VERSION "created by canmatrix"

NS_ :

BS_:

BU_: MD1_ECM ETC NODE_5 BSM_EBS RM_IRCS IC_Multic SGW BCM_NBM VCM NODE_31 ETS NODE_45 FCCU DICO NODE_72 FMReceiver SGW2 VCU ADCU MRGEN DTCO MBMS TPMS AI_CAID ELC ELC_R NODE_F7 BMS3 TUROLLA PCM SRR_Front_Left SRR_Rear_Right SRR_Front_Right SRR_Front SRR_Rear_Left ELFA3_S THERMOKING_M TMU_HP_Rr NODE_B1 NODE_B2 NODE_B3 NODE_B4 NODE_B5 NODE_B6 NODE_B7 NODE_B8 BMS2 NODE_B9 NODE_BA NODE_FC NODE_BB NODE_BC NODE_BE NODE_BD NODE_BF ACU NODE_C0 BMS1 NODE_C1 FCU NODE_C3 NODE_C4 NODE_EC NODE_C5 NODE_C6 NODE_C7 NODE_C8 VCU2 NODE_CA NODE_CB NODE_CD NODE_CE NODE_CF NODE_ED ST_ScanTool MASTER68_STD1 NODE_D1 NODE_F2 NODE_FD NODE_D2 MCSL NODE_EB NODE_D3 NODE_D4 NODE_D5 NODE_D6 VCCU NODE_D8 NODE_D9 NODE_F9 DiagTool NODE_DA NODE_DB NODE_DC NODE_DD NODE_DE NODE_DF NODE_E0 NODE_E1 NODE_E2 NODE_E9 NODE_E3 SAS NODE_FB NODE_F8 NODE_E6 ELFA3 NODE_F THERMOKING_D FMS MULTIC_S MULTIC_2 BMS4 BMS5 BMS6 BMS7 BMS8 BMS9 BMS10 BMS11 NODE_71

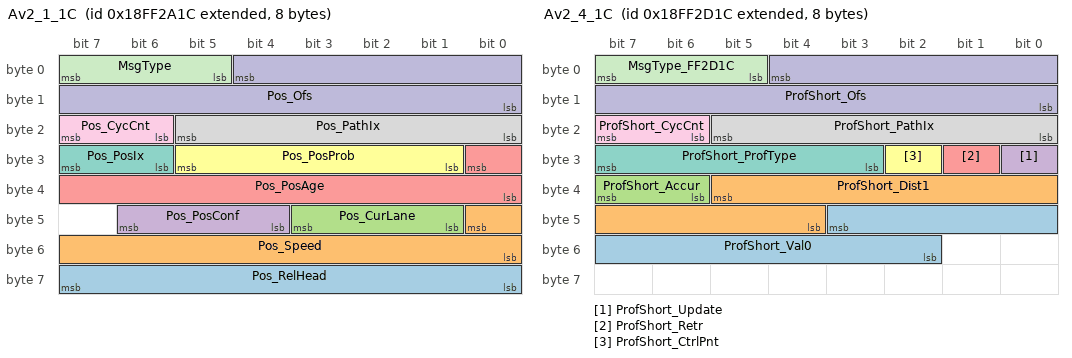
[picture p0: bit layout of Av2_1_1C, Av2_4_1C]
BO_ 2566859292 Av2_1_1C: 8 PCM
 SG_ Pos_RelHead : 63|8@0+ (1.41732283464567,0) [0|358.583] "deg" Vector__XXX
 SG_ Pos_Speed : 40|9@0+ (0.2,-12.8) [-12.8|89.4] "m/s" Vector__XXX
 SG_ Pos_CurLane : 43|3@0+ (1,0) [0|7] "" Vector__XXX
 SG_ Pos_PosConf : 46|3@0+ (1,0) [0|7] "" Vector__XXX
 SG_ Pos_PosAge : 24|9@0+ (5,0) [0|2545] "ms" Vector__XXX
 SG_ Pos_PosProb : 29|5@0+ (3.33333333333333,0) [0|100] "%" Vector__XXX
 SG_ Pos_PosIx : 31|2@0+ (1,0) [0|3] "" Vector__XXX
 SG_ Pos_PathIx : 21|6@0+ (1,0) [8|63] "" Vector__XXX
 SG_ Pos_CycCnt : 23|2@0+ (1,0) [0|3] "" Vector__XXX
 SG_ Pos_Ofs : 4|13@0+ (1,0) [0|8190] "m" Vector__XXX
 SG_ MsgType : 7|3@0+ (1,0) [0|7] "" Vector__XXX

BO_ 2566859548 Av2_2_1C: 8 PCM
 SG_ Seg_NumOfLanesInDrivDir : 58|3@0+ (1,0) [0|7] "" Vector__XXX
 SG_ Seg_NumOfLanesInOppDir : 60|2@0+ (1,0) [0|3] "" Vector__XXX
 SG_ Seg_DividedRoad : 62|2@0+ (1,0) [0|3] "" Vector__XXX
 SG_ Seg_EffSpeedLimType : 50|3@0+ (1,0) [0|7] "" Vector__XXX
 SG_ Seg_EffSpeedLim : 55|5@0+ (1,0) [0|31] "km/h or mph" Vector__XXX
 SG_ Seg_FormOfWay : 43|4@0+ (1,0) [0|14] "" Vector__XXX
 SG_ Seg_ComplexInters : 45|2@0+ (1,0) [0|3] "" Vector__XXX
 SG_ Seg_PartOfCalcRoute : 47|2@0+ (1,0) [0|3] "" Vector__XXX
 SG_ Seg_FunctRoadClass : 34|3@0+ (1,0) [0|6] "" Vector__XXX
 SG_ Seg_RelProb : 39|5@0+ (3.33333333333333,0) [0|100] "%" Vector__XXX
 SG_ Seg_Update : 24|1@0+ (1,0) [0|1] "" Vector__XXX
 SG_ Seg_Retr : 25|1@0+ (1,0) [0|1] "" Vector__XXX
 SG_ Seg_BuiltUpArea : 27|2@0+ (1,0) [0|3] "" Vector__XXX
 SG_ Seg_Bridge : 29|2@0+ (1,0) [0|3] "" Vector__XXX
 SG_ Seg_Tunnel : 31|2@0+ (1,0) [0|3] "" Vector__XXX
 SG_ Seg_PathIx : 21|6@0+ (1,0) [8|63] "" Vector__XXX
 SG_ Seg_CycCnt : 23|2@0+ (1,0) [0|3] "" Vector__XXX
 SG_ Seg_Ofs : 4|13@0+ (1,0) [0|8190] "m" Vector__XXX
 SG_ MsgType_FF2B1C : 7|3@0+ (1,0) [0|7] "" Vector__XXX

BO_ 2566859804 Av2_3_1C: 8 PCM
 SG_ Stub_NumOfLanesInDrivDir : 58|3@0+ (1,0) [0|7] "" Vector__XXX
 SG_ Stub_NumOfLanesInOppDir : 60|2@0+ (1,0) [0|3] "" Vector__XXX
 SG_ Stub_RightOfWay : 62|2@0+ (1,0) [0|3] "" Vector__XXX
 SG_ Stub_LastStubAtOfs : 63|1@0+ (1,0) [0|1] "" Vector__XXX
 SG_ Stub_TurnAngle : 55|8@0+ (1.41732283464567,0) [0|358.583] "deg" Vector__XXX
 SG_ Stub_FormOfWay : 43|4@0+ (1,0) [0|14] "" Vector__XXX
 SG_ Stub_ComplexInters : 45|2@0+ (1,0) [0|3] "" Vector__XXX
 SG_ Stub_PartOfCalcRoute : 47|2@0+ (1,0) [0|3] "" Vector__XXX
 SG_ Stub_FunctRoadClass : 34|3@0+ (1,0) [0|6] "" Vector__XXX
 SG_ Stub_RelProb : 39|5@0+ (3.33333333333333,0) [0|100] "%" Vector__XXX
 SG_ Stub_Update : 24|1@0+ (1,0) [0|1] "" Vector__XXX
 SG_ Stub_Retr : 25|1@0+ (1,0) [0|1] "" Vector__XXX
 SG_ Stub_SubPathIx : 31|6@0+ (1,0) [8|63] "" Vector__XXX
 SG_ Stub_PathIx : 21|6@0+ (1,0) [8|63] "" Vector__XXX
 SG_ Stub_CycCnt : 23|2@0+ (1,0) [0|3] "" Vector__XXX
 SG_ Stub_Ofs : 4|13@0+ (1,0) [0|8190] "m" Vector__XXX
 SG_ MsgType_FF2C1C : 7|3@0+ (1,0) [0|7] "" Vector__XXX

BO_ 2566860060 Av2_4_1C: 8 PCM
 SG_ ProfShort_Val0 : 43|10@0+ (1,0) [0|1023] "" Vector__XXX
 SG_ ProfShort_Dist1 : 37|10@0+ (1,0) [0|1022] "m" Vector__XXX
 SG_ ProfShort_Accur : 39|2@0+ (1,0) [0|3] "" Vector__XXX
 SG_ ProfShort_Update : 24|1@0+ (1,0) [0|1] "" Vector__XXX
 SG_ ProfShort_Retr : 25|1@0+ (1,0) [0|1] "" Vector__XXX
 SG_ ProfShort_CtrlPnt : 26|1@0+ (1,0) [0|1] "" Vector__XXX
 SG_ ProfShort_ProfType M : 31|5@0+ (1,0) [0|31] "" Vector__XXX
 SG_ ProfShort_PathIx : 21|6@0+ (1,0) [8|63] "" Vector__XXX
 SG_ ProfShort_CycCnt : 23|2@0+ (1,0) [0|3] "" Vector__XXX
 SG_ ProfShort_Ofs : 4|13@0+ (1,0) [0|8190] "m" Vector__XXX
 SG_ MsgType_FF2D1C : 7|3@0+ (1,0) [0|7] "" Vector__XXX

BO_ 2566860316 Av2_5_1C: 8 PCM
 SG_ ProfLong_Val31_RsvdForSysSpecTyp m31 : 39|32@0+ (1,1) [1|1] "" Vector__XXX
 SG_ ProfLong_Val30_RsvdForSysSpecTyp m30 : 39|32@0+ (1,1) [1|1] "" Vector__XXX
 SG_ ProfLong_Val29_RsvdForSysSpecTyp m29 : 39|32@0+ (1,1) [1|1] "" Vector__XXX
 SG_ ProfLong_Val28_RsvdForSysSpecTyp m28 : 39|32@0+ (1,1) [1|1] "" Vector__XXX
 SG_ ProfLong_Val27_RsvdForSysSpecTyp m27 : 39|32@0+ (1,1) [1|1] "" Vector__XXX
 SG_ ProfLong_Val26_RsvdForSysSpecTyp m26 : 39|32@0+ (1,1) [1|1] "" Vector__XXX
 SG_ ProfLong_Val25_RsvdForSysSpecTyp m25 : 39|32@0+ (1,1) [1|1] "" Vector__XXX
 SG_ ProfLong_Val24_RsvdForSysSpecTyp m24 : 39|32@0+ (1,1) [1|1] "" Vector__XXX
 SG_ ProfLong_Val23_RsvdForSysSpecTyp m23 : 39|32@0+ (1,1) [1|1] "" Vector__XXX
 SG_ ProfLong_Val22_RsvdForSysSpecTyp m22 : 39|32@0+ (1,1) [1|1] "" Vector__XXX
 SG_ ProfLong_Val21_RsvdForSysSpecTyp m21 : 39|32@0+ (1,1) [1|1] "" Vector__XXX
 SG_ ProfLong_Val20_RsvdForSysSpecTyp m20 : 39|32@0+ (1,1) [1|1] "" Vector__XXX
 SG_ ProfLong_Val19_RsvdForSysSpecTyp m19 : 39|32@0+ (1,1) [1|1] "" Vector__XXX
 SG_ ProfLong_Val18_RsvdForSysSpecTyp m18 : 39|32@0+ (1,1) [1|1] "" Vector__XXX
 SG_ ProfLong_Val17_RsvdForSysSpecTyp m17 : 39|32@0+ (1,1) [1|1] "" Vector__XXX
 SG_ ProfLong_Val16_RsvdForSysSpecTyp m16 : 39|32@0+ (1,1) [1|1] "" Vector__XXX
 SG_ ProfLong_Val15_RsvdForStdTypes m15 : 39|32@0+ (1,1) [1|1] "" Vector__XXX
 SG_ ProfLong_Val14_RsvdForStdTypes m14 : 39|32@0+ (1,1) [1|1] "" Vector__XXX
 SG_ ProfLong_Val13_RsvdForStdTypes m13 : 39|32@0+ (1,1) [1|1] "" Vector__XXX
 SG_ ProfLong_Val12_RsvdForStdTypes m12 : 39|32@0+ (1,1) [1|1] "" Vector__XXX
 SG_ ProfLong_Val11_RsvdForStdTypes m11 : 39|32@0+ (1,1) [1|1] "" Vector__XXX
 SG_ ProfLong_Val10_RsvdForStdTypes m10 : 39|32@0+ (1,1) [1|1] "" Vector__XXX
 SG_ ProfLong_Val9_RsvdForStdTypes m9 : 39|32@0+ (1,1) [1|1] "" Vector__XXX
 SG_ ProfLong_Val8_RsvdForStdTypes m8 : 39|32@0+ (1,1) [1|1] "" Vector__XXX
 SG_ ProfLong_Val7_RsvdForStdTypes m7 : 39|32@0+ (1,1) [1|1] "" Vector__XXX
 SG_ ProfLong_Val6_RsvdForStdTypes m6 : 39|32@0+ (1,1) [1|1] "" Vector__XXX
 SG_ ProfLong_Val5_RsvdForStdTypes m5 : 39|32@0+ (1,1) [1|1] "" Vector__XXX
 SG_ ProfLong_Val4_RsvdForStdTypes m4 : 39|32@0+ (1,1) [1|1] "" Vector__XXX
 SG_ ProfLong_Val3_RsvdForStdTypes m3 : 39|32@0+ (1,1) [1|1] "" Vector__XXX
 SG_ ProfLong_Val2_Lat m2 : 39|32@0+ (1E-007,-90) [-90|331.1081215] "deg" Vector__XXX
 SG_ ProfLong_Val1_Long m1 : 39|32@0+ (1E-007,-180) [-180|241.1081215] "deg" Vector__XXX
 SG_ ProfLong_Update : 24|1@0+ (1,0) [0|1] "" Vector__XXX
 SG_ ProfLong_Retr : 25|1@0+ (1,0) [0|1] "" Vector__XXX
 SG_ ProfLong_CtrlPnt : 26|1@0+ (1,0) [0|1] "" Vector__XXX
 SG_ ProfLong_ProfType M : 31|5@0+ (1,0) [0|31] "" Vector__XXX
 SG_ ProfLong_PathIx : 21|6@0+ (1,0) [8|63] "" Vector__XXX
 SG_ ProfLong_CycCnt : 23|2@0+ (1,0) [0|3] "" Vector__XXX
 SG_ ProfLong_Ofs : 4|13@0+ (1,0) [0|8190] "m" Vector__XXX
 SG_ MsgType_FF2E1C : 7|3@0+ (1,0) [0|7] "" Vector__XXX

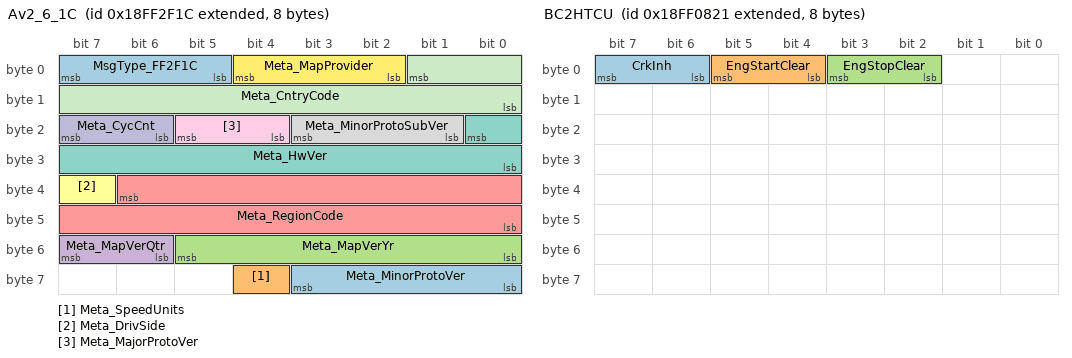
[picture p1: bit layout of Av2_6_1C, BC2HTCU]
BO_ 2566860572 Av2_6_1C: 8 PCM
 SG_ Meta_MinorProtoVer : 59|4@0+ (1,0) [0|15] "" Vector__XXX
 SG_ Meta_SpeedUnits : 60|1@0+ (1,0) [0|1] "" Vector__XXX
 SG_ Meta_MapVerYr : 53|6@0+ (1,2000) [2000|2063] "year" Vector__XXX
 SG_ Meta_MapVerQtr : 55|2@0+ (1,1) [1|4] "Quarter" Vector__XXX
 SG_ Meta_RegionCode : 38|15@0+ (1,0) [0|32767] "" Vector__XXX
 SG_ Meta_DrivSide : 39|1@0+ (1,0) [0|1] "" Vector__XXX
 SG_ Meta_HwVer : 16|9@0+ (1,0) [0|511] "" Vector__XXX
 SG_ Meta_MinorProtoSubVer : 19|3@0+ (1,0) [0|7] "" Vector__XXX
 SG_ Meta_MajorProtoVer : 21|2@0+ (1,0) [0|3] "" Vector__XXX
 SG_ Meta_CycCnt : 23|2@0+ (1,0) [0|3] "" Vector__XXX
 SG_ Meta_CntryCode : 1|10@0+ (1,0) [0|1023] "" Vector__XXX
 SG_ Meta_MapProvider : 4|3@0+ (1,0) [0|7] "" Vector__XXX
 SG_ MsgType_FF2F1C : 7|3@0+ (1,0) [0|7] "" Vector__XXX

BO_ 2565804065 BC_DR: 8 BCM_NBM
 SG_ HandLevPos : 2|6@1+ (1,0) [0|63] ""  PCM,RM_IRCS
 SG_ DisRetFtReq : 0|1@1+ (1,0) [0|1] ""  PCM,RM_IRCS

BO_ 2566850593 BC2HTCU: 8 BCM_NBM
 SG_ CrkInh : 6|2@1+ (1,0) [0|3] ""  PCM
 SG_ EngStartClear : 4|2@1+ (1,0) [0|3] ""  PCM
 SG_ EngStopClear : 2|2@1+ (1,0) [0|3] ""  PCM

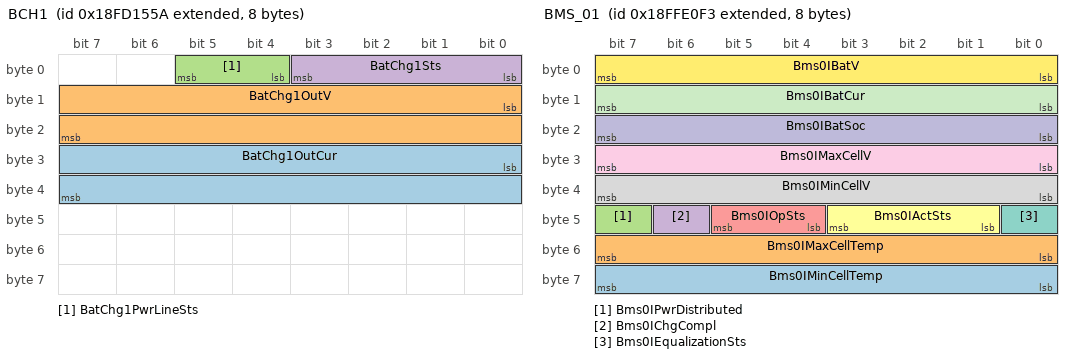
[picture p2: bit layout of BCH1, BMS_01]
BO_ 2566722906 BCH1: 8 DICO
 SG_ BatChg1OutCur : 24|16@1+ (0.05,-1600) [-1600|1612.75] "A"  PCM
 SG_ BatChg1OutV : 8|16@1+ (0.05,0) [0|3212.75] "V"  PCM
 SG_ BatChg1PwrLineSts : 4|2@1+ (1,0) [0|3] ""  PCM
 SG_ BatChg1Sts : 0|4@1+ (1,0) [0|15] ""  PCM

BO_ 2566906099 BMS_01: 8 MBMS
 SG_ Bms0IMinCellTemp : 56|8@1+ (1,-40) [-40|210] "°C"  PCM
 SG_ Bms0IMaxCellTemp : 48|8@1+ (1,-40) [-40|210] "°C"  PCM
 SG_ Bms0IPwrDistributed : 47|1@1+ (1,0) [0|1] ""  PCM
 SG_ Bms0IChgCompl : 46|1@1+ (1,0) [0|1] ""  PCM
 SG_ Bms0IOpSts : 44|2@1+ (1,0) [0|3] ""  PCM
 SG_ Bms0IActSts : 41|3@1+ (1,0) [0|7] ""  PCM
 SG_ Bms0IEqualizationSts : 40|1@1+ (1,0) [0|1] ""  PCM
 SG_ Bms0IMinCellV : 32|8@1+ (20,0) [0|5000] "Mv"  PCM
 SG_ Bms0IMaxCellV : 24|8@1+ (20,0) [0|5000] "Mv"  PCM
 SG_ Bms0IBatSoc : 16|8@1+ (0.4,0) [0|100] "%"  PCM
 SG_ Bms0IBatCur : 8|8@1+ (4,-500) [-500|500] "A"  PCM
 SG_ Bms0IBatV : 0|8@1+ (3.4,0) [0|850] "V"  PCM

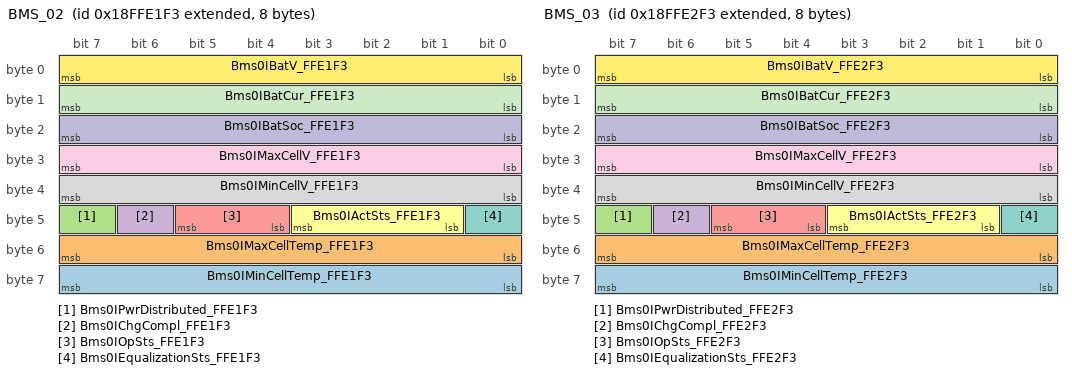
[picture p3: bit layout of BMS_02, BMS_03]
BO_ 2566906355 BMS_02: 8 MBMS
 SG_ Bms0IMinCellTemp_FFE1F3 : 56|8@1+ (1,-40) [-40|210] "°C"  PCM
 SG_ Bms0IMaxCellTemp_FFE1F3 : 48|8@1+ (1,-40) [-40|210] "°C"  PCM
 SG_ Bms0IPwrDistributed_FFE1F3 : 47|1@1+ (1,0) [0|1] ""  PCM
 SG_ Bms0IChgCompl_FFE1F3 : 46|1@1+ (1,0) [0|1] ""  PCM
 SG_ Bms0IOpSts_FFE1F3 : 44|2@1+ (1,0) [0|3] ""  PCM
 SG_ Bms0IActSts_FFE1F3 : 41|3@1+ (1,0) [0|7] ""  PCM
 SG_ Bms0IEqualizationSts_FFE1F3 : 40|1@1+ (1,0) [0|1] ""  PCM
 SG_ Bms0IMinCellV_FFE1F3 : 32|8@1+ (20,0) [0|5000] "Mv"  PCM
 SG_ Bms0IMaxCellV_FFE1F3 : 24|8@1+ (20,0) [0|5000] "Mv"  PCM
 SG_ Bms0IBatSoc_FFE1F3 : 16|8@1+ (0.4,0) [0|100] "%"  PCM
 SG_ Bms0IBatCur_FFE1F3 : 8|8@1+ (4,-500) [-500|500] "A"  PCM
 SG_ Bms0IBatV_FFE1F3 : 0|8@1+ (3.4,0) [0|850] "V"  PCM

BO_ 2566906611 BMS_03: 8 MBMS
 SG_ Bms0IMinCellTemp_FFE2F3 : 56|8@1+ (1,-40) [-40|210] "°C"  PCM
 SG_ Bms0IMaxCellTemp_FFE2F3 : 48|8@1+ (1,-40) [-40|210] "°C"  PCM
 SG_ Bms0IPwrDistributed_FFE2F3 : 47|1@1+ (1,0) [0|1] ""  PCM
 SG_ Bms0IChgCompl_FFE2F3 : 46|1@1+ (1,0) [0|1] ""  PCM
 SG_ Bms0IOpSts_FFE2F3 : 44|2@1+ (1,0) [0|3] ""  PCM
 SG_ Bms0IActSts_FFE2F3 : 41|3@1+ (1,0) [0|7] ""  PCM
 SG_ Bms0IEqualizationSts_FFE2F3 : 40|1@1+ (1,0) [0|1] ""  PCM
 SG_ Bms0IMinCellV_FFE2F3 : 32|8@1+ (20,0) [0|5000] "Mv"  PCM
 SG_ Bms0IMaxCellV_FFE2F3 : 24|8@1+ (20,0) [0|5000] "Mv"  PCM
 SG_ Bms0IBatSoc_FFE2F3 : 16|8@1+ (0.4,0) [0|100] "%"  PCM
 SG_ Bms0IBatCur_FFE2F3 : 8|8@1+ (4,-500) [-500|500] "A"  PCM
 SG_ Bms0IBatV_FFE2F3 : 0|8@1+ (3.4,0) [0|850] "V"  PCM

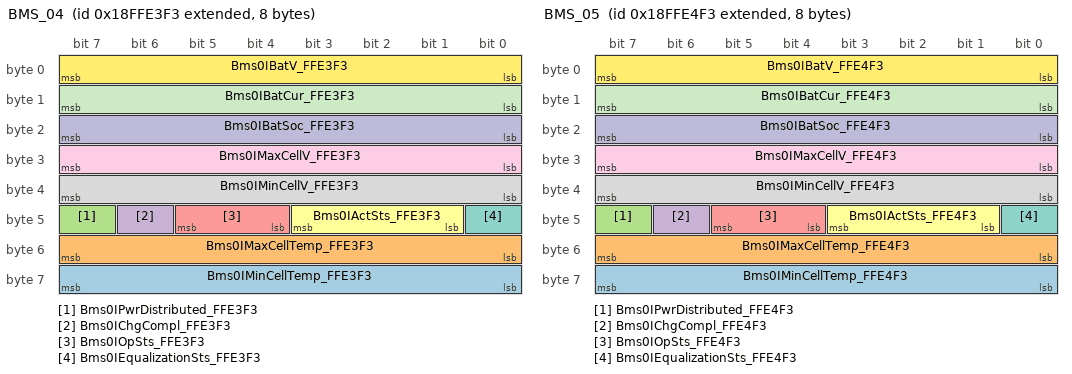
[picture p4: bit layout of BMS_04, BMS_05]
BO_ 2566906867 BMS_04: 8 MBMS
 SG_ Bms0IMinCellTemp_FFE3F3 : 56|8@1+ (1,-40) [-40|210] "°C"  PCM
 SG_ Bms0IMaxCellTemp_FFE3F3 : 48|8@1+ (1,-40) [-40|210] "°C"  PCM
 SG_ Bms0IPwrDistributed_FFE3F3 : 47|1@1+ (1,0) [0|1] ""  PCM
 SG_ Bms0IChgCompl_FFE3F3 : 46|1@1+ (1,0) [0|1] ""  PCM
 SG_ Bms0IOpSts_FFE3F3 : 44|2@1+ (1,0) [0|3] ""  PCM
 SG_ Bms0IActSts_FFE3F3 : 41|3@1+ (1,0) [0|7] ""  PCM
 SG_ Bms0IEqualizationSts_FFE3F3 : 40|1@1+ (1,0) [0|1] ""  PCM
 SG_ Bms0IMinCellV_FFE3F3 : 32|8@1+ (20,0) [0|5000] "Mv"  PCM
 SG_ Bms0IMaxCellV_FFE3F3 : 24|8@1+ (20,0) [0|5000] "Mv"  PCM
 SG_ Bms0IBatSoc_FFE3F3 : 16|8@1+ (0.4,0) [0|100] "%"  PCM
 SG_ Bms0IBatCur_FFE3F3 : 8|8@1+ (4,-500) [-500|500] "A"  PCM
 SG_ Bms0IBatV_FFE3F3 : 0|8@1+ (3.4,0) [0|850] "V"  PCM

BO_ 2566907123 BMS_05: 8 MBMS
 SG_ Bms0IMinCellTemp_FFE4F3 : 56|8@1+ (1,-40) [-40|210] "°C"  PCM
 SG_ Bms0IMaxCellTemp_FFE4F3 : 48|8@1+ (1,-40) [-40|210] "°C"  PCM
 SG_ Bms0IPwrDistributed_FFE4F3 : 47|1@1+ (1,0) [0|1] ""  PCM
 SG_ Bms0IChgCompl_FFE4F3 : 46|1@1+ (1,0) [0|1] ""  PCM
 SG_ Bms0IOpSts_FFE4F3 : 44|2@1+ (1,0) [0|3] ""  PCM
 SG_ Bms0IActSts_FFE4F3 : 41|3@1+ (1,0) [0|7] ""  PCM
 SG_ Bms0IEqualizationSts_FFE4F3 : 40|1@1+ (1,0) [0|1] ""  PCM
 SG_ Bms0IMinCellV_FFE4F3 : 32|8@1+ (20,0) [0|5000] "Mv"  PCM
 SG_ Bms0IMaxCellV_FFE4F3 : 24|8@1+ (20,0) [0|5000] "Mv"  PCM
 SG_ Bms0IBatSoc_FFE4F3 : 16|8@1+ (0.4,0) [0|100] "%"  PCM
 SG_ Bms0IBatCur_FFE4F3 : 8|8@1+ (4,-500) [-500|500] "A"  PCM
 SG_ Bms0IBatV_FFE4F3 : 0|8@1+ (3.4,0) [0|850] "V"  PCM

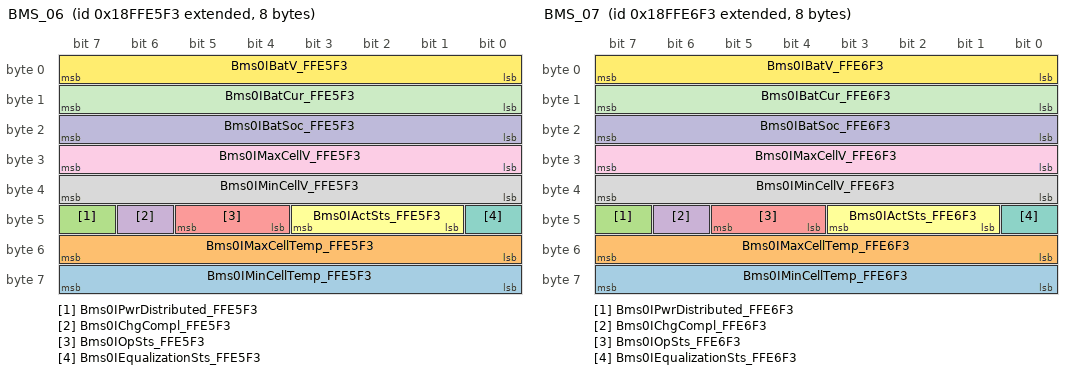
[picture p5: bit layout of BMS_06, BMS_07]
BO_ 2566907379 BMS_06: 8 MBMS
 SG_ Bms0IMinCellTemp_FFE5F3 : 56|8@1+ (1,-40) [-40|210] "°C"  PCM
 SG_ Bms0IMaxCellTemp_FFE5F3 : 48|8@1+ (1,-40) [-40|210] "°C"  PCM
 SG_ Bms0IPwrDistributed_FFE5F3 : 47|1@1+ (1,0) [0|1] ""  PCM
 SG_ Bms0IChgCompl_FFE5F3 : 46|1@1+ (1,0) [0|1] ""  PCM
 SG_ Bms0IOpSts_FFE5F3 : 44|2@1+ (1,0) [0|3] ""  PCM
 SG_ Bms0IActSts_FFE5F3 : 41|3@1+ (1,0) [0|7] ""  PCM
 SG_ Bms0IEqualizationSts_FFE5F3 : 40|1@1+ (1,0) [0|1] ""  PCM
 SG_ Bms0IMinCellV_FFE5F3 : 32|8@1+ (20,0) [0|5000] "Mv"  PCM
 SG_ Bms0IMaxCellV_FFE5F3 : 24|8@1+ (20,0) [0|5000] "Mv"  PCM
 SG_ Bms0IBatSoc_FFE5F3 : 16|8@1+ (0.4,0) [0|100] "%"  PCM
 SG_ Bms0IBatCur_FFE5F3 : 8|8@1+ (4,-500) [-500|500] "A"  PCM
 SG_ Bms0IBatV_FFE5F3 : 0|8@1+ (3.4,0) [0|850] "V"  PCM

BO_ 2566907635 BMS_07: 8 MBMS
 SG_ Bms0IMinCellTemp_FFE6F3 : 56|8@1+ (1,-40) [-40|210] "°C"  PCM
 SG_ Bms0IMaxCellTemp_FFE6F3 : 48|8@1+ (1,-40) [-40|210] "°C"  PCM
 SG_ Bms0IPwrDistributed_FFE6F3 : 47|1@1+ (1,0) [0|1] ""  PCM
 SG_ Bms0IChgCompl_FFE6F3 : 46|1@1+ (1,0) [0|1] ""  PCM
 SG_ Bms0IOpSts_FFE6F3 : 44|2@1+ (1,0) [0|3] ""  PCM
 SG_ Bms0IActSts_FFE6F3 : 41|3@1+ (1,0) [0|7] ""  PCM
 SG_ Bms0IEqualizationSts_FFE6F3 : 40|1@1+ (1,0) [0|1] ""  PCM
 SG_ Bms0IMinCellV_FFE6F3 : 32|8@1+ (20,0) [0|5000] "Mv"  PCM
 SG_ Bms0IMaxCellV_FFE6F3 : 24|8@1+ (20,0) [0|5000] "Mv"  PCM
 SG_ Bms0IBatSoc_FFE6F3 : 16|8@1+ (0.4,0) [0|100] "%"  PCM
 SG_ Bms0IBatCur_FFE6F3 : 8|8@1+ (4,-500) [-500|500] "A"  PCM
 SG_ Bms0IBatV_FFE6F3 : 0|8@1+ (3.4,0) [0|850] "V"  PCM

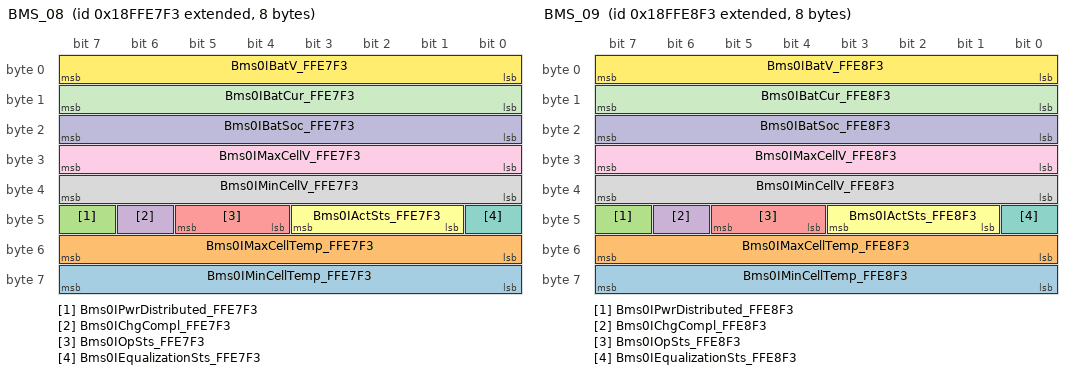
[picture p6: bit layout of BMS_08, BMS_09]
BO_ 2566907891 BMS_08: 8 MBMS
 SG_ Bms0IMinCellTemp_FFE7F3 : 56|8@1+ (1,-40) [-40|210] "°C"  PCM
 SG_ Bms0IMaxCellTemp_FFE7F3 : 48|8@1+ (1,-40) [-40|210] "°C"  PCM
 SG_ Bms0IPwrDistributed_FFE7F3 : 47|1@1+ (1,0) [0|1] ""  PCM
 SG_ Bms0IChgCompl_FFE7F3 : 46|1@1+ (1,0) [0|1] ""  PCM
 SG_ Bms0IOpSts_FFE7F3 : 44|2@1+ (1,0) [0|3] ""  PCM
 SG_ Bms0IActSts_FFE7F3 : 41|3@1+ (1,0) [0|7] ""  PCM
 SG_ Bms0IEqualizationSts_FFE7F3 : 40|1@1+ (1,0) [0|1] ""  PCM
 SG_ Bms0IMinCellV_FFE7F3 : 32|8@1+ (20,0) [0|5000] "Mv"  PCM
 SG_ Bms0IMaxCellV_FFE7F3 : 24|8@1+ (20,0) [0|5000] "Mv"  PCM
 SG_ Bms0IBatSoc_FFE7F3 : 16|8@1+ (0.4,0) [0|100] "%"  PCM
 SG_ Bms0IBatCur_FFE7F3 : 8|8@1+ (4,-500) [-500|500] "A"  PCM
 SG_ Bms0IBatV_FFE7F3 : 0|8@1+ (3.4,0) [0|850] "V"  PCM

BO_ 2566908147 BMS_09: 8 MBMS
 SG_ Bms0IMinCellTemp_FFE8F3 : 56|8@1+ (1,-40) [-40|210] "°C"  PCM
 SG_ Bms0IMaxCellTemp_FFE8F3 : 48|8@1+ (1,-40) [-40|210] "°C"  PCM
 SG_ Bms0IPwrDistributed_FFE8F3 : 47|1@1+ (1,0) [0|1] ""  PCM
 SG_ Bms0IChgCompl_FFE8F3 : 46|1@1+ (1,0) [0|1] ""  PCM
 SG_ Bms0IOpSts_FFE8F3 : 44|2@1+ (1,0) [0|3] ""  PCM
 SG_ Bms0IActSts_FFE8F3 : 41|3@1+ (1,0) [0|7] ""  PCM
 SG_ Bms0IEqualizationSts_FFE8F3 : 40|1@1+ (1,0) [0|1] ""  PCM
 SG_ Bms0IMinCellV_FFE8F3 : 32|8@1+ (20,0) [0|5000] "Mv"  PCM
 SG_ Bms0IMaxCellV_FFE8F3 : 24|8@1+ (20,0) [0|5000] "Mv"  PCM
 SG_ Bms0IBatSoc_FFE8F3 : 16|8@1+ (0.4,0) [0|100] "%"  PCM
 SG_ Bms0IBatCur_FFE8F3 : 8|8@1+ (4,-500) [-500|500] "A"  PCM
 SG_ Bms0IBatV_FFE8F3 : 0|8@1+ (3.4,0) [0|850] "V"  PCM

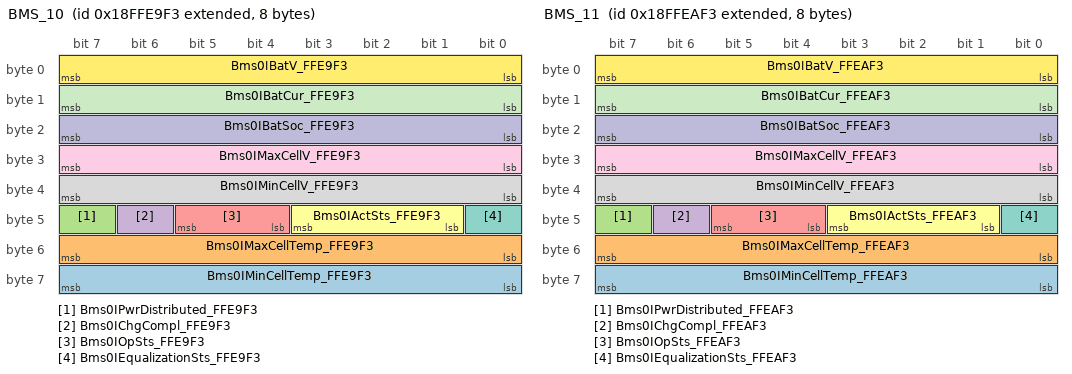
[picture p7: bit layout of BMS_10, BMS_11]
BO_ 2566908403 BMS_10: 8 MBMS
 SG_ Bms0IMinCellTemp_FFE9F3 : 56|8@1+ (1,-40) [-40|210] "°C"  PCM
 SG_ Bms0IMaxCellTemp_FFE9F3 : 48|8@1+ (1,-40) [-40|210] "°C"  PCM
 SG_ Bms0IPwrDistributed_FFE9F3 : 47|1@1+ (1,0) [0|1] ""  PCM
 SG_ Bms0IChgCompl_FFE9F3 : 46|1@1+ (1,0) [0|1] ""  PCM
 SG_ Bms0IOpSts_FFE9F3 : 44|2@1+ (1,0) [0|3] ""  PCM
 SG_ Bms0IActSts_FFE9F3 : 41|3@1+ (1,0) [0|7] ""  PCM
 SG_ Bms0IEqualizationSts_FFE9F3 : 40|1@1+ (1,0) [0|1] ""  PCM
 SG_ Bms0IMinCellV_FFE9F3 : 32|8@1+ (20,0) [0|5000] "Mv"  PCM
 SG_ Bms0IMaxCellV_FFE9F3 : 24|8@1+ (20,0) [0|5000] "Mv"  PCM
 SG_ Bms0IBatSoc_FFE9F3 : 16|8@1+ (0.4,0) [0|100] "%"  PCM
 SG_ Bms0IBatCur_FFE9F3 : 8|8@1+ (4,-500) [-500|500] "A"  PCM
 SG_ Bms0IBatV_FFE9F3 : 0|8@1+ (3.4,0) [0|850] "V"  PCM

BO_ 2566908659 BMS_11: 8 MBMS
 SG_ Bms0IMinCellTemp_FFEAF3 : 56|8@1+ (1,-40) [-40|210] "°C"  PCM
 SG_ Bms0IMaxCellTemp_FFEAF3 : 48|8@1+ (1,-40) [-40|210] "°C"  PCM
 SG_ Bms0IPwrDistributed_FFEAF3 : 47|1@1+ (1,0) [0|1] ""  PCM
 SG_ Bms0IChgCompl_FFEAF3 : 46|1@1+ (1,0) [0|1] ""  PCM
 SG_ Bms0IOpSts_FFEAF3 : 44|2@1+ (1,0) [0|3] ""  PCM
 SG_ Bms0IActSts_FFEAF3 : 41|3@1+ (1,0) [0|7] ""  PCM
 SG_ Bms0IEqualizationSts_FFEAF3 : 40|1@1+ (1,0) [0|1] ""  PCM
 SG_ Bms0IMinCellV_FFEAF3 : 32|8@1+ (20,0) [0|5000] "Mv"  PCM
 SG_ Bms0IMaxCellV_FFEAF3 : 24|8@1+ (20,0) [0|5000] "Mv"  PCM
 SG_ Bms0IBatSoc_FFEAF3 : 16|8@1+ (0.4,0) [0|100] "%"  PCM
 SG_ Bms0IBatCur_FFEAF3 : 8|8@1+ (4,-500) [-500|500] "A"  PCM
 SG_ Bms0IBatV_FFEAF3 : 0|8@1+ (3.4,0) [0|850] "V"  PCM

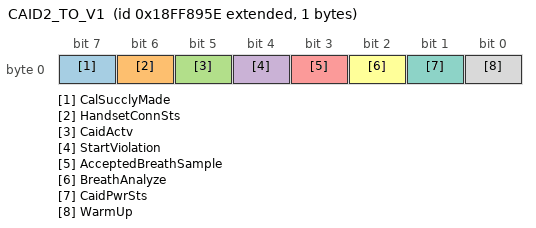
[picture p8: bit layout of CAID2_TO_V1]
BO_ 2566883678 CAID2_TO_V1: 1 AI_CAID
 SG_ CalSucclyMade : 7|1@1+ (1,0) [0|1] ""  PCM
 SG_ HandsetConnSts : 6|1@1+ (1,0) [0|1] ""  PCM
 SG_ CaidActv : 5|1@1+ (1,0) [0|1] ""  PCM
 SG_ StartViolation : 4|1@1+ (1,0) [0|1] ""  PCM
 SG_ AcceptedBreathSample : 3|1@1+ (1,0) [0|1] ""  PCM
 SG_ BreathAnalyze : 2|1@1+ (1,0) [0|1] ""  PCM
 SG_ CaidPwrSts : 1|1@1+ (1,0) [0|1] ""  PCM
 SG_ WarmUp : 0|1@1+ (1,0) [0|1] ""  PCM

BO_ 2566884190 CAID2_TO_V3: 8 AI_CAID
 SG_ DeferredData : 48|8@1+ (1,0) [0|250] ""  PCM

BO_ 2566843648 CCSS_00: 8 MD1_ECM
 SG_ DcdcCurSetPnt24VSide : 56|8@1+ (1,0) [0|250] "A"  PCM
 SG_ MaxVsl : 0|8@1+ (1,0) [0|250] "km/h"  PCM

BO_ 2566843676 CCSS_1C: 8 PCM
 SG_ MaxVsl_FEED1C : 0|8@1+ (1,0) [0|250] "km/h" Vector__XXX

CM_ BO_ 2566859292 "- 30.03.2023: Predisposition PCM3 Protocole ADASIS non J1939
-  TBC if 1 single multiplexed message  or 6-non multiplexed will be used";
CM_ SG_ 2566859292 Pos_PosAge "- Always 0 in Iveco application";
CM_ SG_ 2566859292 Pos_PathIx "- Values 1, 2, 6, 8-63 supported";
CM_ SG_ 2566859292 MsgType "- Always 1";
CM_ BO_ 2566859548 "- 30.03.2023: Predisposition PCM3 Protocole ADASIS non J1939";
CM_ SG_ 2566859548 MsgType_FF2B1C "- Always 2";
CM_ BO_ 2566859804 "- 30.03.2023: Predisposition PCM3 Protocole ADASIS non J1939";
CM_ SG_ 2566859804 MsgType_FF2C1C "- Always 3";
CM_ BO_ 2566860060 "- 30.03.2023: Predisposition PCM3 Protocole ADASIS non J1939";
CM_ SG_ 2566860060 MsgType_FF2D1C "- Always 4";
CM_ BO_ 2566860316 "- 30.03.2023: Predisposition PCM3 Protocole ADASIS non J1939";
CM_ SG_ 2566860316 MsgType_FF2E1C "- Always 5";
CM_ BO_ 2566860572 "- s.Ib..24.work.TELEM: 'AsNeeded'' reuqested for Telem (PCM3)";
CM_ SG_ 2566860572 Meta_RegionCode "- Not used in Iveco application";
CM_ SG_ 2566860572 MsgType_FF2F1C "- Always 6";
CM_ BO_ 2565804065 "- Exception - Should be J1939 p2p. Related to Voith Mild Hybrid project
-  OLD Acronym: PA_BC_DR - Body Computer to Intarder EST42";
CM_ BO_ 2566850593 "- ETC1.Vo.ETC.DiwaNXT..MH.VDB: Msg Predisposal. Only for Mild Hybrid case with AGB Diwa NextGen.
- ETC1.Vo.ETC.DiwaNXT..MH.VDB: The cranking of the engine will be inhibited  by BC till the Mild Hybrid Systems closes properly its start-up sequence. This information is available on message HTCU2BC.CRU_State == 02 / Ready for start-up";
CM_ BO_ 2566722906 "- Specific to Siemens Full Elec vehicles.";
CM_ BO_ 2566906099 "- Specific to Siemens Full Elec vehicles";
CM_ BO_ 2566906355 "- Specific to Siemens Full Elec vehicles";
CM_ BO_ 2566906611 "- Specific to Siemens Full Elec vehicles";
CM_ BO_ 2566906867 "- Specific to Siemens Full Elec vehicles";
CM_ BO_ 2566907123 "- Specific to Siemens Full Elec vehicles";
CM_ BO_ 2566907379 "- Specific to Siemens Full Elec vehicles";
CM_ BO_ 2566907635 "- Specific to Siemens Full Elec vehicles";
CM_ BO_ 2566907891 "- Specific to Siemens Full Elec vehicles";
CM_ BO_ 2566908147 "- Specific to Siemens Full Elec vehicles";
CM_ BO_ 2566908403 "- Specific to Siemens Full Elec vehicles, Forsee only.";
CM_ BO_ 2566908659 "- Specific to Siemens Full Elec vehicles, Forsee only.";
CM_ BO_ 2566843648 "- Not sent by MD1 for CNG";
CM_ SG_ 2566843648 DcdcCurSetPnt24VSide "- Used for Mild Hybrid function";
CM_ SG_ 2566843648 MaxVsl "- 20 km/h in case of Creep Mode active, otherwise FFh";
CM_ SG_ 2566843676 MaxVsl_FEED1C "- Road Speed Limit from GPS maps
-  Type of included limits shall be defined";
BA_DEF_ BO_  "CI_MsgDefinition" STRING ;
BA_DEF_ BO_  "CI_MsgId" INT 0 2147483647;
BA_DEF_ BO_  "CI_MsgName" STRING ;
BA_DEF_ BO_  "GenMsgCycleTime" INT 0 3600000;
BA_DEF_ BO_  "GenMsgCycleTimeFast" INT 0 3600000;
BA_DEF_ BO_  "GenMsgDelayTime" INT 0 3600000;
BA_DEF_ BO_  "GenMsgILSupport" ENUM  "No","Yes";
BA_DEF_ BO_  "GenMsgNrOfRepetition" INT 0 1000000;
BA_DEF_ BO_  "GenMsgRequestable" INT 0 1;
BA_DEF_ BO_  "GenMsgSendType" ENUM  "cyclic","NotUsed","NotUsed","NotUsed","NotUsed","NotUsed","NotUsed","IfActive","noMsgSendType";
BA_DEF_ BO_  "GenMsgStartDelayTime" INT 0 100000;
BA_DEF_ BO_  "TpJ1939VarDlc" ENUM  "No","Yes";
BA_DEF_ BO_  "VFrameFormat" ENUM  "StandardCAN","ExtendedCAN","reserved","J1939PG";
BA_DEF_ SG_  "CI_ParId" STRING ;
BA_DEF_ SG_  "CI_SigId" INT 0 2147483647;
BA_DEF_ SG_  "CI_SigName" STRING ;
BA_DEF_ SG_  "GenSigEVName" STRING ;
BA_DEF_ SG_  "GenSigILSupport" ENUM  "No","Yes";
BA_DEF_ SG_  "GenSigInactiveValue" INT 0 2147483647;
BA_DEF_ SG_  "GenSigSendType" ENUM  "Cyclic","OnWrite","OnWriteWithRepetition","OnChange","OnChangeWithRepetition","IfActive","IfActiveWithRepetition","NoSigSendType";
BA_DEF_ SG_  "GenSigStartValue" INT 0 2147483647;
BA_DEF_ SG_  "GenSigTimeoutTime_ACM_CANAIR" INT 0 3600000;
BA_DEF_ SG_  "GenSigTimeoutTime_ACU" INT 0 3600000;
BA_DEF_ SG_  "GenSigTimeoutTime_ADCU" INT 0 3600000;
BA_DEF_ SG_  "GenSigTimeoutTime_AI_CAID" INT 0 3600000;
BA_DEF_ SG_  "GenSigTimeoutTime_ASM_ELC5_Fr" INT 0 3600000;
BA_DEF_ SG_  "GenSigTimeoutTime_AVAS" INT 0 3600000;
BA_DEF_ SG_  "GenSigTimeoutTime_Av2HP" INT 0 3600000;
BA_DEF_ SG_  "GenSigTimeoutTime_BCM_NBM" INT 0 3600000;
BA_DEF_ SG_  "GenSigTimeoutTime_BSM_EBS" INT 0 3600000;
BA_DEF_ SG_  "GenSigTimeoutTime_DICO" INT 0 3600000;
BA_DEF_ SG_  "GenSigTimeoutTime_DMS" INT 0 3600000;
BA_DEF_ SG_  "GenSigTimeoutTime_EBS_EBR" INT 0 3600000;
BA_DEF_ SG_  "GenSigTimeoutTime_ECM_MD1_D" INT 0 3600000;
BA_DEF_ SG_  "GenSigTimeoutTime_ECM_MD1_G" INT 0 3600000;
BA_DEF_ SG_  "GenSigTimeoutTime_ETC_DiwaNXT" INT 0 3600000;
BA_DEF_ SG_  "GenSigTimeoutTime_ETC_DiwaNXT_MH" INT 0 3600000;
BA_DEF_ SG_  "GenSigTimeoutTime_ETC_Ecolife2" INT 0 3600000;
BA_DEF_ SG_  "GenSigTimeoutTime_FCCU" INT 0 3600000;
BA_DEF_ SG_  "GenSigTimeoutTime_FMS_FMS4" INT 0 3600000;
BA_DEF_ SG_  "GenSigTimeoutTime_FMS_FMS5" INT 0 3600000;
BA_DEF_ SG_  "GenSigTimeoutTime_HVPDU_HV_BOX" INT 0 3600000;
BA_DEF_ SG_  "GenSigTimeoutTime_IC_MulticII" INT 0 3600000;
BA_DEF_ SG_  "GenSigTimeoutTime_IC_MulticS" INT 0 3600000;
BA_DEF_ SG_  "GenSigTimeoutTime_INVEM1_ELFA3" INT 0 3600000;
BA_DEF_ SG_  "GenSigTimeoutTime_MBMS" INT 0 3600000;
BA_DEF_ SG_  "GenSigTimeoutTime_MCSL" INT 0 3600000;
BA_DEF_ SG_  "GenSigTimeoutTime_MPPxPTFE2" INT 0 3600000;
BA_DEF_ SG_  "GenSigTimeoutTime_PCM" INT 0 3600000;
BA_DEF_ SG_  "GenSigTimeoutTime_RDAB_SmtRadio" INT 0 3600000;
BA_DEF_ SG_  "GenSigTimeoutTime_RM_INTD" INT 0 3600000;
BA_DEF_ SG_  "GenSigTimeoutTime_RM_IRCS" INT 0 3600000;
BA_DEF_ SG_  "GenSigTimeoutTime_SAS" INT 0 3600000;
BA_DEF_ SG_  "GenSigTimeoutTime_SGW" INT 0 3600000;
BA_DEF_ SG_  "GenSigTimeoutTime_SGW2" INT 0 3600000;
BA_DEF_ SG_  "GenSigTimeoutTime_TASM_ETS" INT 0 3600000;
BA_DEF_ SG_  "GenSigTimeoutTime_TMU_HP_Fr" INT 0 3600000;
BA_DEF_ SG_  "GenSigTimeoutTime_TMU_HP_Rr" INT 0 3600000;
BA_DEF_ SG_  "GenSigTimeoutTime_TPMS" INT 0 3600000;
BA_DEF_ SG_  "GenSigTimeoutTime_Tacho_DTCO" INT 0 3600000;
BA_DEF_ SG_  "GenSigTimeoutTime_Tacho_MTCO" INT 0 3600000;
BA_DEF_ SG_  "GenSigTimeoutTime_Tacho_TSU" INT 0 3600000;
BA_DEF_ SG_  "GenSigTimeoutTime_VCM" INT 0 3600000;
BA_DEF_ SG_  "GenSigTimeoutTime_VCU" INT 0 3600000;
BA_DEF_ SG_  "GenSigTimeoutTime_VMU" INT 0 3600000;
BA_DEF_ SG_  "SPN" INT 0 524287;
BA_DEF_ SG_  "SigType" ENUM  "Default","Range","RangeSigned","ASCII","Discrete","Control","ReferencePGN","DTC","StringDelimiter","StringLength","StringLengthControl";
BA_DEF_DEF_  "CI_MsgDefinition" "";
BA_DEF_DEF_  "CI_MsgId" 0;
BA_DEF_DEF_  "CI_MsgName" "";
BA_DEF_DEF_  "GenMsgCycleTime" 0;
BA_DEF_DEF_  "GenMsgCycleTimeFast" 0;
BA_DEF_DEF_  "GenMsgDelayTime" 1;
BA_DEF_DEF_  "GenMsgILSupport" "Yes";
BA_DEF_DEF_  "GenMsgNrOfRepetition" 0;
BA_DEF_DEF_  "GenMsgRequestable" 0;
BA_DEF_DEF_  "GenMsgSendType" "noMsgSendType";
BA_DEF_DEF_  "GenMsgStartDelayTime" 0;
BA_DEF_DEF_  "TpJ1939VarDlc" "No";
BA_DEF_DEF_  "VFrameFormat" "J1939PG";
BA_DEF_DEF_  "CI_ParId" "";
BA_DEF_DEF_  "CI_SigId" 0;
BA_DEF_DEF_  "CI_SigName" "";
BA_DEF_DEF_  "GenSigEVName" "Env@Nodename_@Signame";
BA_DEF_DEF_  "GenSigILSupport" "Yes";
BA_DEF_DEF_  "GenSigInactiveValue" 0;
BA_DEF_DEF_  "GenSigSendType" "NoSigSendType";
BA_DEF_DEF_  "GenSigStartValue" 0;
BA_DEF_DEF_  "GenSigTimeoutTime_ACM_CANAIR" 0;
BA_DEF_DEF_  "GenSigTimeoutTime_ACU" 0;
BA_DEF_DEF_  "GenSigTimeoutTime_ADCU" 0;
BA_DEF_DEF_  "GenSigTimeoutTime_AI_CAID" 0;
BA_DEF_DEF_  "GenSigTimeoutTime_ASM_ELC5_Fr" 0;
BA_DEF_DEF_  "GenSigTimeoutTime_AVAS" 0;
BA_DEF_DEF_  "GenSigTimeoutTime_Av2HP" 0;
BA_DEF_DEF_  "GenSigTimeoutTime_BCM_NBM" 0;
BA_DEF_DEF_  "GenSigTimeoutTime_BSM_EBS" 0;
BA_DEF_DEF_  "GenSigTimeoutTime_DICO" 0;
BA_DEF_DEF_  "GenSigTimeoutTime_DMS" 0;
BA_DEF_DEF_  "GenSigTimeoutTime_EBS_EBR" 0;
BA_DEF_DEF_  "GenSigTimeoutTime_ECM_MD1_D" 0;
BA_DEF_DEF_  "GenSigTimeoutTime_ECM_MD1_G" 0;
BA_DEF_DEF_  "GenSigTimeoutTime_ETC_DiwaNXT" 0;
BA_DEF_DEF_  "GenSigTimeoutTime_ETC_DiwaNXT_MH" 0;
BA_DEF_DEF_  "GenSigTimeoutTime_ETC_Ecolife2" 0;
BA_DEF_DEF_  "GenSigTimeoutTime_FCCU" 0;
BA_DEF_DEF_  "GenSigTimeoutTime_FMS_FMS4" 0;
BA_DEF_DEF_  "GenSigTimeoutTime_FMS_FMS5" 0;
BA_DEF_DEF_  "GenSigTimeoutTime_HVPDU_HV_BOX" 0;
BA_DEF_DEF_  "GenSigTimeoutTime_IC_MulticII" 0;
BA_DEF_DEF_  "GenSigTimeoutTime_IC_MulticS" 0;
BA_DEF_DEF_  "GenSigTimeoutTime_INVEM1_ELFA3" 0;
BA_DEF_DEF_  "GenSigTimeoutTime_MBMS" 0;
BA_DEF_DEF_  "GenSigTimeoutTime_MCSL" 0;
BA_DEF_DEF_  "GenSigTimeoutTime_MPPxPTFE2" 0;
BA_DEF_DEF_  "GenSigTimeoutTime_PCM" 0;
BA_DEF_DEF_  "GenSigTimeoutTime_RDAB_SmtRadio" 0;
BA_DEF_DEF_  "GenSigTimeoutTime_RM_INTD" 0;
BA_DEF_DEF_  "GenSigTimeoutTime_RM_IRCS" 0;
BA_DEF_DEF_  "GenSigTimeoutTime_SAS" 0;
BA_DEF_DEF_  "GenSigTimeoutTime_SGW" 0;
BA_DEF_DEF_  "GenSigTimeoutTime_SGW2" 0;
BA_DEF_DEF_  "GenSigTimeoutTime_TASM_ETS" 0;
BA_DEF_DEF_  "GenSigTimeoutTime_TMU_HP_Fr" 0;
BA_DEF_DEF_  "GenSigTimeoutTime_TMU_HP_Rr" 0;
BA_DEF_DEF_  "GenSigTimeoutTime_TPMS" 0;
BA_DEF_DEF_  "GenSigTimeoutTime_Tacho_DTCO" 0;
BA_DEF_DEF_  "GenSigTimeoutTime_Tacho_MTCO" 0;
BA_DEF_DEF_  "GenSigTimeoutTime_Tacho_TSU" 0;
BA_DEF_DEF_  "GenSigTimeoutTime_VCM" 0;
BA_DEF_DEF_  "GenSigTimeoutTime_VCU" 0;
BA_DEF_DEF_  "GenSigTimeoutTime_VMU" 0;
BA_DEF_DEF_  "SPN" 0;
BA_DEF_DEF_  "SigType" "Default";
BA_ "GenMsgStartDelayTime" BO_ 2566859292 160;
BA_ "GenMsgDelayTime" BO_ 2566859292 500;
BA_ "CI_MsgName" BO_ 2566859292 "Av2_1_1C - ADASIS v2 (non-multiplexed) - POSITION Type ";
BA_ "CI_MsgId" BO_ 2566859292 3594;
BA_ "CI_MsgDefinition" BO_ 2566859292 "Iveco Proprietary";
BA_ "GenMsgDelayTime" BO_ 2566859548 100;
BA_ "CI_MsgName" BO_ 2566859548 "Av2_2_1C - ADASIS v2 (non-multiplexed) - SEGMENT Type ";
BA_ "CI_MsgId" BO_ 2566859548 3606;
BA_ "CI_MsgDefinition" BO_ 2566859548 "Iveco Proprietary";
BA_ "GenMsgDelayTime" BO_ 2566859804 100;
BA_ "CI_MsgName" BO_ 2566859804 "Av2_3_1C - ADASIS v2 (non-multiplexed) - STUB Type ";
BA_ "CI_MsgId" BO_ 2566859804 3626;
BA_ "CI_MsgDefinition" BO_ 2566859804 "Iveco Proprietary";
BA_ "GenMsgDelayTime" BO_ 2566860060 100;
BA_ "CI_MsgName" BO_ 2566860060 "Av2_4_1C - ADASIS v2 (non-multiplexed) - PROFILE SHORT Type ";
BA_ "CI_MsgId" BO_ 2566860060 3644;
BA_ "CI_MsgDefinition" BO_ 2566860060 "Iveco Proprietary";
BA_ "GenMsgDelayTime" BO_ 2566860316 100;
BA_ "CI_MsgName" BO_ 2566860316 "Av2_5_1C - ADASIS v2 (non-multiplexed) - PROFILE LONG Type ";
BA_ "CI_MsgId" BO_ 2566860316 3677;
BA_ "CI_MsgDefinition" BO_ 2566860316 "Iveco Proprietary";
BA_ "CI_MsgName" BO_ 2566860572 "Av2_6_1C - ADASIS v2 (non-multiplexed) - META-DATA Type ";
BA_ "CI_MsgId" BO_ 2566860572 21254;
BA_ "CI_MsgDefinition" BO_ 2566860572 "Iveco Proprietary";
BA_ "GenMsgStartDelayTime" BO_ 2565804065 46;
BA_ "GenMsgSendType" BO_ 2565804065 0;
BA_ "GenMsgDelayTime" BO_ 2565804065 50;
BA_ "GenMsgCycleTimeFast" BO_ 2565804065 100;
BA_ "GenMsgCycleTime" BO_ 2565804065 100;
BA_ "CI_MsgName" BO_ 2565804065 "BC_DR - Body Computer to Drivelie retarder";
BA_ "CI_MsgId" BO_ 2565804065 2932;
BA_ "CI_MsgDefinition" BO_ 2565804065 "Iveco SPR2 Proprietary";
BA_ "GenMsgStartDelayTime" BO_ 2566850593 75;
BA_ "GenMsgSendType" BO_ 2566850593 0;
BA_ "GenMsgDelayTime" BO_ 2566850593 50;
BA_ "GenMsgCycleTimeFast" BO_ 2566850593 100;
BA_ "GenMsgCycleTime" BO_ 2566850593 100;
BA_ "CI_MsgName" BO_ 2566850593 "BC2HTCU - BC to HTCU (Mild Hybrid)";
BA_ "CI_MsgId" BO_ 2566850593 4375;
BA_ "CI_MsgDefinition" BO_ 2566850593 "Bosch Proprietary";
BA_ "GenMsgStartDelayTime" BO_ 2566722906 9;
BA_ "GenMsgSendType" BO_ 2566722906 0;
BA_ "GenMsgDelayTime" BO_ 2566722906 50;
BA_ "GenMsgCycleTimeFast" BO_ 2566722906 100;
BA_ "GenMsgCycleTime" BO_ 2566722906 100;
BA_ "CI_MsgName" BO_ 2566722906 "BCH1 - Battery Charger 1";
BA_ "CI_MsgId" BO_ 2566722906 323;
BA_ "CI_MsgDefinition" BO_ 2566722906 "J1939DA";
BA_ "GenMsgStartDelayTime" BO_ 2566906099 56;
BA_ "GenMsgSendType" BO_ 2566906099 0;
BA_ "GenMsgDelayTime" BO_ 2566906099 2500;
BA_ "GenMsgCycleTimeFast" BO_ 2566906099 5000;
BA_ "GenMsgCycleTime" BO_ 2566906099 5000;
BA_ "CI_MsgName" BO_ 2566906099 "BMS_01 - Proprietary Iveco -  BMS0i Infos Frame";
BA_ "CI_MsgId" BO_ 2566906099 10715;
BA_ "CI_MsgDefinition" BO_ 2566906099 "Iveco Proprietary";
BA_ "GenMsgStartDelayTime" BO_ 2566906355 62;
BA_ "GenMsgSendType" BO_ 2566906355 0;
BA_ "GenMsgDelayTime" BO_ 2566906355 2500;
BA_ "GenMsgCycleTimeFast" BO_ 2566906355 5000;
BA_ "GenMsgCycleTime" BO_ 2566906355 5000;
BA_ "CI_MsgName" BO_ 2566906355 "BMS_02 - Proprietary Iveco -  BMS0i Infos Frame";
BA_ "CI_MsgId" BO_ 2566906355 10728;
BA_ "CI_MsgDefinition" BO_ 2566906355 "Iveco Proprietary";
BA_ "GenMsgStartDelayTime" BO_ 2566906611 68;
BA_ "GenMsgSendType" BO_ 2566906611 0;
BA_ "GenMsgDelayTime" BO_ 2566906611 2500;
BA_ "GenMsgCycleTimeFast" BO_ 2566906611 5000;
BA_ "GenMsgCycleTime" BO_ 2566906611 5000;
BA_ "CI_MsgName" BO_ 2566906611 "BMS_03 - Proprietary Iveco -  BMS0i Infos Frame";
BA_ "CI_MsgId" BO_ 2566906611 10741;
BA_ "CI_MsgDefinition" BO_ 2566906611 "Iveco Proprietary";
BA_ "GenMsgStartDelayTime" BO_ 2566906867 74;
BA_ "GenMsgSendType" BO_ 2566906867 0;
BA_ "GenMsgDelayTime" BO_ 2566906867 2500;
BA_ "GenMsgCycleTimeFast" BO_ 2566906867 5000;
BA_ "GenMsgCycleTime" BO_ 2566906867 5000;
BA_ "CI_MsgName" BO_ 2566906867 "BMS_04 - Proprietary Iveco -  BMS0i Infos Frame";
BA_ "CI_MsgId" BO_ 2566906867 10754;
BA_ "CI_MsgDefinition" BO_ 2566906867 "Iveco Proprietary";
BA_ "GenMsgStartDelayTime" BO_ 2566907123 80;
BA_ "GenMsgSendType" BO_ 2566907123 0;
BA_ "GenMsgDelayTime" BO_ 2566907123 2500;
BA_ "GenMsgCycleTimeFast" BO_ 2566907123 5000;
BA_ "GenMsgCycleTime" BO_ 2566907123 5000;
BA_ "CI_MsgName" BO_ 2566907123 "BMS_05 - Proprietary Iveco -  BMS0i Infos Frame";
BA_ "CI_MsgId" BO_ 2566907123 10767;
BA_ "CI_MsgDefinition" BO_ 2566907123 "Iveco Proprietary";
BA_ "GenMsgStartDelayTime" BO_ 2566907379 86;
BA_ "GenMsgSendType" BO_ 2566907379 0;
BA_ "GenMsgDelayTime" BO_ 2566907379 2500;
BA_ "GenMsgCycleTimeFast" BO_ 2566907379 5000;
BA_ "GenMsgCycleTime" BO_ 2566907379 5000;
BA_ "CI_MsgName" BO_ 2566907379 "BMS_06 - Proprietary Iveco -  BMS0i Infos Frame";
BA_ "CI_MsgId" BO_ 2566907379 10780;
BA_ "CI_MsgDefinition" BO_ 2566907379 "Iveco Proprietary";
BA_ "GenMsgStartDelayTime" BO_ 2566907635 92;
BA_ "GenMsgSendType" BO_ 2566907635 0;
BA_ "GenMsgDelayTime" BO_ 2566907635 2500;
BA_ "GenMsgCycleTimeFast" BO_ 2566907635 5000;
BA_ "GenMsgCycleTime" BO_ 2566907635 5000;
BA_ "CI_MsgName" BO_ 2566907635 "BMS_07 - Proprietary Iveco -  BMS0i Infos Frame";
BA_ "CI_MsgId" BO_ 2566907635 10793;
BA_ "CI_MsgDefinition" BO_ 2566907635 "Iveco Proprietary";
BA_ "GenMsgStartDelayTime" BO_ 2566907891 98;
BA_ "GenMsgSendType" BO_ 2566907891 0;
BA_ "GenMsgDelayTime" BO_ 2566907891 2500;
BA_ "GenMsgCycleTimeFast" BO_ 2566907891 5000;
BA_ "GenMsgCycleTime" BO_ 2566907891 5000;
BA_ "CI_MsgName" BO_ 2566907891 "BMS_08 - Proprietary Iveco -  BMS0i Infos Frame";
BA_ "CI_MsgId" BO_ 2566907891 10806;
BA_ "CI_MsgDefinition" BO_ 2566907891 "Iveco Proprietary";
BA_ "GenMsgStartDelayTime" BO_ 2566908147 104;
BA_ "GenMsgSendType" BO_ 2566908147 0;
BA_ "GenMsgDelayTime" BO_ 2566908147 2500;
BA_ "GenMsgCycleTimeFast" BO_ 2566908147 5000;
BA_ "GenMsgCycleTime" BO_ 2566908147 5000;
BA_ "CI_MsgName" BO_ 2566908147 "BMS_09 - Proprietary Iveco -  BMS0i Infos Frame";
BA_ "CI_MsgId" BO_ 2566908147 10819;
BA_ "CI_MsgDefinition" BO_ 2566908147 "Iveco Proprietary";
BA_ "GenMsgStartDelayTime" BO_ 2566908403 106;
BA_ "GenMsgSendType" BO_ 2566908403 0;
BA_ "GenMsgDelayTime" BO_ 2566908403 2500;
BA_ "GenMsgCycleTimeFast" BO_ 2566908403 5000;
BA_ "GenMsgCycleTime" BO_ 2566908403 5000;
BA_ "CI_MsgName" BO_ 2566908403 "BMS_10 - Proprietary Iveco -  BMS0i Infos Frame";
BA_ "CI_MsgId" BO_ 2566908403 10832;
BA_ "CI_MsgDefinition" BO_ 2566908403 "Iveco Proprietary";
BA_ "GenMsgStartDelayTime" BO_ 2566908659 108;
BA_ "GenMsgSendType" BO_ 2566908659 0;
BA_ "GenMsgDelayTime" BO_ 2566908659 2500;
BA_ "GenMsgCycleTimeFast" BO_ 2566908659 5000;
BA_ "GenMsgCycleTime" BO_ 2566908659 5000;
BA_ "CI_MsgName" BO_ 2566908659 "BMS_11 - Proprietary Iveco -  BMS0i Infos Frame";
BA_ "CI_MsgId" BO_ 2566908659 10845;
BA_ "CI_MsgDefinition" BO_ 2566908659 "Iveco Proprietary";
BA_ "GenMsgStartDelayTime" BO_ 2566883678 2;
BA_ "GenMsgSendType" BO_ 2566883678 0;
BA_ "GenMsgDelayTime" BO_ 2566883678 250;
BA_ "GenMsgCycleTimeFast" BO_ 2566883678 500;
BA_ "GenMsgCycleTime" BO_ 2566883678 500;
BA_ "CI_MsgName" BO_ 2566883678 "CAID2_TO_V1 - Connected Alcohol Interlock Device2 To Vehicle 1";
BA_ "CI_MsgId" BO_ 2566883678 2818;
BA_ "CI_MsgDefinition" BO_ 2566883678 "Iveco Proprietary";
BA_ "GenMsgStartDelayTime" BO_ 2566884190 8;
BA_ "GenMsgSendType" BO_ 2566884190 0;
BA_ "GenMsgDelayTime" BO_ 2566884190 500;
BA_ "GenMsgCycleTimeFast" BO_ 2566884190 1000;
BA_ "GenMsgCycleTime" BO_ 2566884190 1000;
BA_ "CI_MsgName" BO_ 2566884190 "CAID2_TO_V3 - CAID2_TO_V3";
BA_ "CI_MsgId" BO_ 2566884190 2833;
BA_ "CI_MsgDefinition" BO_ 2566884190 "Iveco Proprietary";
BA_ "GenMsgStartDelayTime" BO_ 2566843648 34;
BA_ "GenMsgSendType" BO_ 2566843648 0;
BA_ "GenMsgDelayTime" BO_ 2566843648 125;
BA_ "GenMsgCycleTimeFast" BO_ 2566843648 250;
BA_ "GenMsgCycleTime" BO_ 2566843648 250;
BA_ "CI_MsgName" BO_ 2566843648 "CCSS_00 - Cruise Control/Vehicle Speed Setup";
BA_ "CI_MsgId" BO_ 2566843648 2164;
BA_ "CI_MsgDefinition" BO_ 2566843648 "J1939DA";
BA_ "GenMsgStartDelayTime" BO_ 2566843676 156;
BA_ "GenMsgSendType" BO_ 2566843676 0;
BA_ "GenMsgDelayTime" BO_ 2566843676 100;
BA_ "GenMsgCycleTimeFast" BO_ 2566843676 1000;
BA_ "GenMsgCycleTime" BO_ 2566843676 1000;
BA_ "CI_MsgName" BO_ 2566843676 "CCSS_1C - Cruise Control/Vehicle Speed Setup";
BA_ "CI_MsgId" BO_ 2566843676 2170;
BA_ "CI_MsgDefinition" BO_ 2566843676 "J1939DA";
BA_ "SigType" SG_ 2566859292 Pos_RelHead 1;
BA_ "GenSigTimeoutTime_PCM" SG_ 2566859292 Pos_RelHead 5000;
BA_ "CI_SigName" SG_ 2566859292 Pos_RelHead "Position – Relative Heading";
BA_ "CI_SigId" SG_ 2566859292 Pos_RelHead 3605;
BA_ "CI_ParId" SG_ 2566859292 Pos_RelHead "AS008";
BA_ "GenSigTimeoutTime_PCM" SG_ 2566859292 Pos_Speed 5000;
BA_ "GenSigStartValue" SG_ 2566859292 Pos_Speed 511;
BA_ "CI_SigName" SG_ 2566859292 Pos_Speed "Position – Speed";
BA_ "CI_SigId" SG_ 2566859292 Pos_Speed 3604;
BA_ "CI_ParId" SG_ 2566859292 Pos_Speed "AS007";
BA_ "GenSigTimeoutTime_PCM" SG_ 2566859292 Pos_CurLane 5000;
BA_ "CI_SigName" SG_ 2566859292 Pos_CurLane "Position – Current Lane";
BA_ "CI_SigId" SG_ 2566859292 Pos_CurLane 3602;
BA_ "CI_ParId" SG_ 2566859292 Pos_CurLane "AS011";
BA_ "GenSigTimeoutTime_PCM" SG_ 2566859292 Pos_PosConf 5000;
BA_ "GenSigStartValue" SG_ 2566859292 Pos_PosConf 7;
BA_ "CI_SigName" SG_ 2566859292 Pos_PosConf "Position – Position Confidence";
BA_ "CI_SigId" SG_ 2566859292 Pos_PosConf 3603;
BA_ "CI_ParId" SG_ 2566859292 Pos_PosConf "AS010";
BA_ "GenSigTimeoutTime_PCM" SG_ 2566859292 Pos_PosAge 5000;
BA_ "CI_SigName" SG_ 2566859292 Pos_PosAge "Position – Position Age";
BA_ "CI_SigId" SG_ 2566859292 Pos_PosAge 3601;
BA_ "CI_ParId" SG_ 2566859292 Pos_PosAge "AS006";
BA_ "GenSigTimeoutTime_PCM" SG_ 2566859292 Pos_PosProb 5000;
BA_ "CI_SigName" SG_ 2566859292 Pos_PosProb "Position – Position Probability";
BA_ "CI_SigId" SG_ 2566859292 Pos_PosProb 3599;
BA_ "CI_ParId" SG_ 2566859292 Pos_PosProb "AS009";
BA_ "GenSigTimeoutTime_PCM" SG_ 2566859292 Pos_PosIx 5000;
BA_ "CI_SigName" SG_ 2566859292 Pos_PosIx "Position – Position Index";
BA_ "CI_SigId" SG_ 2566859292 Pos_PosIx 3600;
BA_ "CI_ParId" SG_ 2566859292 Pos_PosIx "AS005";
BA_ "GenSigTimeoutTime_PCM" SG_ 2566859292 Pos_PathIx 5000;
BA_ "GenSigStartValue" SG_ 2566859292 Pos_PathIx 8;
BA_ "CI_SigName" SG_ 2566859292 Pos_PathIx "Position – Path Index";
BA_ "CI_SigId" SG_ 2566859292 Pos_PathIx 3597;
BA_ "CI_ParId" SG_ 2566859292 Pos_PathIx "AS003";
BA_ "GenSigTimeoutTime_PCM" SG_ 2566859292 Pos_CycCnt 5000;
BA_ "CI_SigName" SG_ 2566859292 Pos_CycCnt "Position – Cyclic Counter";
BA_ "CI_SigId" SG_ 2566859292 Pos_CycCnt 3598;
BA_ "CI_ParId" SG_ 2566859292 Pos_CycCnt "AS002";
BA_ "GenSigTimeoutTime_PCM" SG_ 2566859292 Pos_Ofs 5000;
BA_ "CI_SigName" SG_ 2566859292 Pos_Ofs "Position – Offset";
BA_ "CI_SigId" SG_ 2566859292 Pos_Ofs 3596;
BA_ "CI_ParId" SG_ 2566859292 Pos_Ofs "AS004";
BA_ "GenSigTimeoutTime_PCM" SG_ 2566859292 MsgType 5000;
BA_ "GenSigStartValue" SG_ 2566859292 MsgType 6;
BA_ "CI_SigName" SG_ 2566859292 MsgType "Message Type";
BA_ "CI_SigId" SG_ 2566859292 MsgType 3595;
BA_ "CI_ParId" SG_ 2566859292 MsgType "AS001";
BA_ "GenSigStartValue" SG_ 2566859548 Seg_NumOfLanesInDrivDir 7;
BA_ "CI_SigName" SG_ 2566859548 Seg_NumOfLanesInDrivDir "Segment – Number of lanes in driving direction";
BA_ "CI_SigId" SG_ 2566859548 Seg_NumOfLanesInDrivDir 3623;
BA_ "CI_ParId" SG_ 2566859548 Seg_NumOfLanesInDrivDir "AS021";
BA_ "SigType" SG_ 2566859548 Seg_NumOfLanesInOppDir 4;
BA_ "GenSigStartValue" SG_ 2566859548 Seg_NumOfLanesInOppDir 3;
BA_ "CI_SigName" SG_ 2566859548 Seg_NumOfLanesInOppDir "Segment – Number of lanes in opposite direction";
BA_ "CI_SigId" SG_ 2566859548 Seg_NumOfLanesInOppDir 3624;
BA_ "CI_ParId" SG_ 2566859548 Seg_NumOfLanesInOppDir "AS022";
BA_ "SigType" SG_ 2566859548 Seg_DividedRoad 4;
BA_ "GenSigStartValue" SG_ 2566859548 Seg_DividedRoad 3;
BA_ "CI_SigName" SG_ 2566859548 Seg_DividedRoad "Segment – Divided Road";
BA_ "CI_SigId" SG_ 2566859548 Seg_DividedRoad 3625;
BA_ "CI_ParId" SG_ 2566859548 Seg_DividedRoad "AS025";
BA_ "GenSigStartValue" SG_ 2566859548 Seg_EffSpeedLimType 7;
BA_ "CI_SigName" SG_ 2566859548 Seg_EffSpeedLimType "Segment – Effective Speed Limit Type";
BA_ "CI_SigId" SG_ 2566859548 Seg_EffSpeedLimType 3621;
BA_ "CI_ParId" SG_ 2566859548 Seg_EffSpeedLimType "AS020";
BA_ "GenSigStartValue" SG_ 2566859548 Seg_EffSpeedLim 31;
BA_ "CI_SigName" SG_ 2566859548 Seg_EffSpeedLim "Segment – Effective Speed Limit";
BA_ "CI_SigId" SG_ 2566859548 Seg_EffSpeedLim 3622;
BA_ "CI_ParId" SG_ 2566859548 Seg_EffSpeedLim "AS019";
BA_ "GenSigStartValue" SG_ 2566859548 Seg_FormOfWay 3;
BA_ "CI_SigName" SG_ 2566859548 Seg_FormOfWay "Segment – Form of Way";
BA_ "CI_SigId" SG_ 2566859548 Seg_FormOfWay 3618;
BA_ "CI_ParId" SG_ 2566859548 Seg_FormOfWay "AS018";
BA_ "SigType" SG_ 2566859548 Seg_ComplexInters 4;
BA_ "GenSigStartValue" SG_ 2566859548 Seg_ComplexInters 3;
BA_ "CI_SigName" SG_ 2566859548 Seg_ComplexInters "Segment – Complex Intersection";
BA_ "CI_SigId" SG_ 2566859548 Seg_ComplexInters 3619;
BA_ "CI_ParId" SG_ 2566859548 Seg_ComplexInters "AS027";
BA_ "SigType" SG_ 2566859548 Seg_PartOfCalcRoute 4;
BA_ "GenSigStartValue" SG_ 2566859548 Seg_PartOfCalcRoute 3;
BA_ "CI_SigName" SG_ 2566859548 Seg_PartOfCalcRoute "Segment – Part of Calculated Route";
BA_ "CI_SigId" SG_ 2566859548 Seg_PartOfCalcRoute 3620;
BA_ "CI_ParId" SG_ 2566859548 Seg_PartOfCalcRoute "AS029";
BA_ "CI_SigName" SG_ 2566859548 Seg_FunctRoadClass "Segment – Functional Road Class";
BA_ "CI_SigId" SG_ 2566859548 Seg_FunctRoadClass 3616;
BA_ "CI_ParId" SG_ 2566859548 Seg_FunctRoadClass "AS017";
BA_ "CI_SigName" SG_ 2566859548 Seg_RelProb "Segment – Relative Probability";
BA_ "CI_SigId" SG_ 2566859548 Seg_RelProb 3617;
BA_ "CI_ParId" SG_ 2566859548 Seg_RelProb "AS028";
BA_ "CI_SigName" SG_ 2566859548 Seg_Update "Segment – Update";
BA_ "CI_SigId" SG_ 2566859548 Seg_Update 3611;
BA_ "CI_ParId" SG_ 2566859548 Seg_Update "AS016";
BA_ "CI_SigName" SG_ 2566859548 Seg_Retr "Segment – Retransmission";
BA_ "CI_SigId" SG_ 2566859548 Seg_Retr 3612;
BA_ "CI_ParId" SG_ 2566859548 Seg_Retr "AS013";
BA_ "SigType" SG_ 2566859548 Seg_BuiltUpArea 4;
BA_ "GenSigStartValue" SG_ 2566859548 Seg_BuiltUpArea 3;
BA_ "CI_SigName" SG_ 2566859548 Seg_BuiltUpArea "Segment – Built-up Area";
BA_ "CI_SigId" SG_ 2566859548 Seg_BuiltUpArea 3613;
BA_ "CI_ParId" SG_ 2566859548 Seg_BuiltUpArea "AS026";
BA_ "SigType" SG_ 2566859548 Seg_Bridge 4;
BA_ "GenSigStartValue" SG_ 2566859548 Seg_Bridge 3;
BA_ "CI_SigName" SG_ 2566859548 Seg_Bridge "Segment – Bridge";
BA_ "CI_SigId" SG_ 2566859548 Seg_Bridge 3614;
BA_ "CI_ParId" SG_ 2566859548 Seg_Bridge "AS024";
BA_ "SigType" SG_ 2566859548 Seg_Tunnel 4;
BA_ "GenSigStartValue" SG_ 2566859548 Seg_Tunnel 3;
BA_ "CI_SigName" SG_ 2566859548 Seg_Tunnel "Segment – Tunnel";
BA_ "CI_SigId" SG_ 2566859548 Seg_Tunnel 3615;
BA_ "CI_ParId" SG_ 2566859548 Seg_Tunnel "AS023";
BA_ "GenSigStartValue" SG_ 2566859548 Seg_PathIx 8;
BA_ "CI_SigName" SG_ 2566859548 Seg_PathIx "Segment – Path Index";
BA_ "CI_SigId" SG_ 2566859548 Seg_PathIx 3609;
BA_ "CI_ParId" SG_ 2566859548 Seg_PathIx "AS014";
BA_ "CI_SigName" SG_ 2566859548 Seg_CycCnt "Segment – Cyclic Counter";
BA_ "CI_SigId" SG_ 2566859548 Seg_CycCnt 3610;
BA_ "CI_ParId" SG_ 2566859548 Seg_CycCnt "AS012";
BA_ "CI_SigName" SG_ 2566859548 Seg_Ofs "Segment – Offset";
BA_ "CI_SigId" SG_ 2566859548 Seg_Ofs 3608;
BA_ "CI_ParId" SG_ 2566859548 Seg_Ofs "AS015";
BA_ "GenSigStartValue" SG_ 2566859548 MsgType_FF2B1C 6;
BA_ "CI_SigName" SG_ 2566859548 MsgType_FF2B1C "Message Type";
BA_ "CI_SigId" SG_ 2566859548 MsgType_FF2B1C 3607;
BA_ "CI_ParId" SG_ 2566859548 MsgType_FF2B1C "AS001";
BA_ "GenSigStartValue" SG_ 2566859804 Stub_NumOfLanesInDrivDir 7;
BA_ "CI_SigName" SG_ 2566859804 Stub_NumOfLanesInDrivDir "Stub – Number of lanes in driving direction";
BA_ "CI_SigId" SG_ 2566859804 Stub_NumOfLanesInDrivDir 3640;
BA_ "CI_ParId" SG_ 2566859804 Stub_NumOfLanesInDrivDir "AS039";
BA_ "SigType" SG_ 2566859804 Stub_NumOfLanesInOppDir 4;
BA_ "GenSigStartValue" SG_ 2566859804 Stub_NumOfLanesInOppDir 3;
BA_ "CI_SigName" SG_ 2566859804 Stub_NumOfLanesInOppDir "Stub – Number of lanes in opposite direction";
BA_ "CI_SigId" SG_ 2566859804 Stub_NumOfLanesInOppDir 3641;
BA_ "CI_ParId" SG_ 2566859804 Stub_NumOfLanesInOppDir "AS040";
BA_ "SigType" SG_ 2566859804 Stub_RightOfWay 4;
BA_ "GenSigStartValue" SG_ 2566859804 Stub_RightOfWay 3;
BA_ "CI_SigName" SG_ 2566859804 Stub_RightOfWay "Stub – Right of Way";
BA_ "CI_SigId" SG_ 2566859804 Stub_RightOfWay 3642;
BA_ "CI_ParId" SG_ 2566859804 Stub_RightOfWay "AS042";
BA_ "CI_SigName" SG_ 2566859804 Stub_LastStubAtOfs "Stub – Last Stub at Offset";
BA_ "CI_SigId" SG_ 2566859804 Stub_LastStubAtOfs 3643;
BA_ "CI_ParId" SG_ 2566859804 Stub_LastStubAtOfs "AS045";
BA_ "SigType" SG_ 2566859804 Stub_TurnAngle 1;
BA_ "CI_SigName" SG_ 2566859804 Stub_TurnAngle "Stub – Turn Angle";
BA_ "CI_SigId" SG_ 2566859804 Stub_TurnAngle 3639;
BA_ "CI_ParId" SG_ 2566859804 Stub_TurnAngle "AS036";
BA_ "GenSigStartValue" SG_ 2566859804 Stub_FormOfWay 3;
BA_ "CI_SigName" SG_ 2566859804 Stub_FormOfWay "Stub – Form of Way";
BA_ "CI_SigId" SG_ 2566859804 Stub_FormOfWay 3636;
BA_ "CI_ParId" SG_ 2566859804 Stub_FormOfWay "AS038";
BA_ "SigType" SG_ 2566859804 Stub_ComplexInters 4;
BA_ "GenSigStartValue" SG_ 2566859804 Stub_ComplexInters 3;
BA_ "CI_SigName" SG_ 2566859804 Stub_ComplexInters "Stub – Complex Intersection";
BA_ "CI_SigId" SG_ 2566859804 Stub_ComplexInters 3637;
BA_ "CI_ParId" SG_ 2566859804 Stub_ComplexInters "AS041";
BA_ "SigType" SG_ 2566859804 Stub_PartOfCalcRoute 4;
BA_ "GenSigStartValue" SG_ 2566859804 Stub_PartOfCalcRoute 3;
BA_ "CI_SigName" SG_ 2566859804 Stub_PartOfCalcRoute "Stub – Part of Calculated Route";
BA_ "CI_SigId" SG_ 2566859804 Stub_PartOfCalcRoute 3638;
BA_ "CI_ParId" SG_ 2566859804 Stub_PartOfCalcRoute "AS044";
BA_ "CI_SigName" SG_ 2566859804 Stub_FunctRoadClass "Stub – Functional Road Class";
BA_ "CI_SigId" SG_ 2566859804 Stub_FunctRoadClass 3634;
BA_ "CI_ParId" SG_ 2566859804 Stub_FunctRoadClass "AS043";
BA_ "CI_SigName" SG_ 2566859804 Stub_RelProb "Stub – Relative Probability";
BA_ "CI_SigId" SG_ 2566859804 Stub_RelProb 3635;
BA_ "CI_ParId" SG_ 2566859804 Stub_RelProb "AS037";
BA_ "CI_SigName" SG_ 2566859804 Stub_Update "Stub – Update";
BA_ "CI_SigId" SG_ 2566859804 Stub_Update 3631;
BA_ "CI_ParId" SG_ 2566859804 Stub_Update "AS034";
BA_ "CI_SigName" SG_ 2566859804 Stub_Retr "Stub – Retransmission";
BA_ "CI_SigId" SG_ 2566859804 Stub_Retr 3632;
BA_ "CI_ParId" SG_ 2566859804 Stub_Retr "AS031";
BA_ "GenSigStartValue" SG_ 2566859804 Stub_SubPathIx 8;
BA_ "CI_SigName" SG_ 2566859804 Stub_SubPathIx "Stub – Sub-Path Index";
BA_ "CI_SigId" SG_ 2566859804 Stub_SubPathIx 3633;
BA_ "CI_ParId" SG_ 2566859804 Stub_SubPathIx "AS035";
BA_ "GenSigStartValue" SG_ 2566859804 Stub_PathIx 8;
BA_ "CI_SigName" SG_ 2566859804 Stub_PathIx "Stub – Path Index";
BA_ "CI_SigId" SG_ 2566859804 Stub_PathIx 3629;
BA_ "CI_ParId" SG_ 2566859804 Stub_PathIx "AS032";
BA_ "CI_SigName" SG_ 2566859804 Stub_CycCnt "Stub – Cyclic Counter";
BA_ "CI_SigId" SG_ 2566859804 Stub_CycCnt 3630;
BA_ "CI_ParId" SG_ 2566859804 Stub_CycCnt "AS030";
BA_ "CI_SigName" SG_ 2566859804 Stub_Ofs "Stub – Offset";
BA_ "CI_SigId" SG_ 2566859804 Stub_Ofs 3628;
BA_ "CI_ParId" SG_ 2566859804 Stub_Ofs "AS033";
BA_ "GenSigStartValue" SG_ 2566859804 MsgType_FF2C1C 6;
BA_ "CI_SigName" SG_ 2566859804 MsgType_FF2C1C "Message Type";
BA_ "CI_SigId" SG_ 2566859804 MsgType_FF2C1C 3627;
BA_ "CI_ParId" SG_ 2566859804 MsgType_FF2C1C "AS001";
BA_ "GenSigStartValue" SG_ 2566860060 ProfShort_Val0 1023;
BA_ "CI_SigName" SG_ 2566860060 ProfShort_Val0 "Profile Short – Value 0";
BA_ "CI_SigId" SG_ 2566860060 ProfShort_Val0 3655;
BA_ "CI_ParId" SG_ 2566860060 ProfShort_Val0 "AS053";
BA_ "CI_SigName" SG_ 2566860060 ProfShort_Dist1 "Profile Short – Distance 1";
BA_ "CI_SigId" SG_ 2566860060 ProfShort_Dist1 3654;
BA_ "CI_ParId" SG_ 2566860060 ProfShort_Dist1 "AS054";
BA_ "SigType" SG_ 2566860060 ProfShort_Accur 4;
BA_ "GenSigStartValue" SG_ 2566860060 ProfShort_Accur 3;
BA_ "CI_SigName" SG_ 2566860060 ProfShort_Accur "Profile Short – Accuracy";
BA_ "CI_SigId" SG_ 2566860060 ProfShort_Accur 3653;
BA_ "CI_ParId" SG_ 2566860060 ProfShort_Accur "AS056";
BA_ "CI_SigName" SG_ 2566860060 ProfShort_Update "Profile Short – Update";
BA_ "CI_SigId" SG_ 2566860060 ProfShort_Update 3649;
BA_ "CI_ParId" SG_ 2566860060 ProfShort_Update "AS050";
BA_ "CI_SigName" SG_ 2566860060 ProfShort_Retr "Profile Short – Retransmission";
BA_ "CI_SigId" SG_ 2566860060 ProfShort_Retr 3650;
BA_ "CI_ParId" SG_ 2566860060 ProfShort_Retr "AS047";
BA_ "CI_SigName" SG_ 2566860060 ProfShort_CtrlPnt "Profile Short – Control Point";
BA_ "CI_SigId" SG_ 2566860060 ProfShort_CtrlPnt 3651;
BA_ "CI_ParId" SG_ 2566860060 ProfShort_CtrlPnt "AS052";
BA_ "CI_SigName" SG_ 2566860060 ProfShort_ProfType "Profile Short – Profile Type";
BA_ "CI_SigId" SG_ 2566860060 ProfShort_ProfType 3652;
BA_ "CI_ParId" SG_ 2566860060 ProfShort_ProfType "AS051";
BA_ "GenSigStartValue" SG_ 2566860060 ProfShort_PathIx 8;
BA_ "CI_SigName" SG_ 2566860060 ProfShort_PathIx "Profile Short – Path Index";
BA_ "CI_SigId" SG_ 2566860060 ProfShort_PathIx 3647;
BA_ "CI_ParId" SG_ 2566860060 ProfShort_PathIx "AS048";
BA_ "CI_SigName" SG_ 2566860060 ProfShort_CycCnt "Profile Short – Cyclic Counter";
BA_ "CI_SigId" SG_ 2566860060 ProfShort_CycCnt 3648;
BA_ "CI_ParId" SG_ 2566860060 ProfShort_CycCnt "AS046";
BA_ "CI_SigName" SG_ 2566860060 ProfShort_Ofs "Profile Short – Offset";
BA_ "CI_SigId" SG_ 2566860060 ProfShort_Ofs 3646;
BA_ "CI_ParId" SG_ 2566860060 ProfShort_Ofs "AS049";
BA_ "GenSigStartValue" SG_ 2566860060 MsgType_FF2D1C 6;
BA_ "CI_SigName" SG_ 2566860060 MsgType_FF2D1C "Message Type";
BA_ "CI_SigId" SG_ 2566860060 MsgType_FF2D1C 3645;
BA_ "CI_ParId" SG_ 2566860060 MsgType_FF2D1C "AS001";
BA_ "CI_SigName" SG_ 2566860316 ProfLong_Val31_RsvdForSysSpecTyp "Profile Long – Value 31 – Reserved for system specific types";
BA_ "CI_SigId" SG_ 2566860316 ProfLong_Val31_RsvdForSysSpecTyp 3717;
BA_ "CI_ParId" SG_ 2566860316 ProfLong_Val31_RsvdForSysSpecTyp "AS155";
BA_ "CI_SigName" SG_ 2566860316 ProfLong_Val30_RsvdForSysSpecTyp "Profile Long – Value 30 – Reserved for system specific types";
BA_ "CI_SigId" SG_ 2566860316 ProfLong_Val30_RsvdForSysSpecTyp 3716;
BA_ "CI_ParId" SG_ 2566860316 ProfLong_Val30_RsvdForSysSpecTyp "AS154";
BA_ "CI_SigName" SG_ 2566860316 ProfLong_Val29_RsvdForSysSpecTyp "Profile Long – Value 29 – Reserved for system specific types";
BA_ "CI_SigId" SG_ 2566860316 ProfLong_Val29_RsvdForSysSpecTyp 3715;
BA_ "CI_ParId" SG_ 2566860316 ProfLong_Val29_RsvdForSysSpecTyp "AS153";
BA_ "CI_SigName" SG_ 2566860316 ProfLong_Val28_RsvdForSysSpecTyp "Profile Long – Value 28 – Reserved for system specific types";
BA_ "CI_SigId" SG_ 2566860316 ProfLong_Val28_RsvdForSysSpecTyp 3714;
BA_ "CI_ParId" SG_ 2566860316 ProfLong_Val28_RsvdForSysSpecTyp "AS152";
BA_ "CI_SigName" SG_ 2566860316 ProfLong_Val27_RsvdForSysSpecTyp "Profile Long – Value 27 – Reserved for system specific types";
BA_ "CI_SigId" SG_ 2566860316 ProfLong_Val27_RsvdForSysSpecTyp 3713;
BA_ "CI_ParId" SG_ 2566860316 ProfLong_Val27_RsvdForSysSpecTyp "AS151";
BA_ "CI_SigName" SG_ 2566860316 ProfLong_Val26_RsvdForSysSpecTyp "Profile Long – Value 26 – Reserved for system specific types";
BA_ "CI_SigId" SG_ 2566860316 ProfLong_Val26_RsvdForSysSpecTyp 3712;
BA_ "CI_ParId" SG_ 2566860316 ProfLong_Val26_RsvdForSysSpecTyp "AS150";
BA_ "CI_SigName" SG_ 2566860316 ProfLong_Val25_RsvdForSysSpecTyp "Profile Long – Value 25 – Reserved for system specific types";
BA_ "CI_SigId" SG_ 2566860316 ProfLong_Val25_RsvdForSysSpecTyp 3711;
BA_ "CI_ParId" SG_ 2566860316 ProfLong_Val25_RsvdForSysSpecTyp "AS149";
BA_ "CI_SigName" SG_ 2566860316 ProfLong_Val24_RsvdForSysSpecTyp "Profile Long – Value 24 – Reserved for system specific types";
BA_ "CI_SigId" SG_ 2566860316 ProfLong_Val24_RsvdForSysSpecTyp 3710;
BA_ "CI_ParId" SG_ 2566860316 ProfLong_Val24_RsvdForSysSpecTyp "AS148";
BA_ "CI_SigName" SG_ 2566860316 ProfLong_Val23_RsvdForSysSpecTyp "Profile Long – Value 23 – Reserved for system specific types";
BA_ "CI_SigId" SG_ 2566860316 ProfLong_Val23_RsvdForSysSpecTyp 3709;
BA_ "CI_ParId" SG_ 2566860316 ProfLong_Val23_RsvdForSysSpecTyp "AS147";
BA_ "CI_SigName" SG_ 2566860316 ProfLong_Val22_RsvdForSysSpecTyp "Profile Long – Value 22 – Reserved for system specific types";
BA_ "CI_SigId" SG_ 2566860316 ProfLong_Val22_RsvdForSysSpecTyp 3708;
BA_ "CI_ParId" SG_ 2566860316 ProfLong_Val22_RsvdForSysSpecTyp "AS146";
BA_ "CI_SigName" SG_ 2566860316 ProfLong_Val21_RsvdForSysSpecTyp "Profile Long – Value 21 – Reserved for system specific types";
BA_ "CI_SigId" SG_ 2566860316 ProfLong_Val21_RsvdForSysSpecTyp 3707;
BA_ "CI_ParId" SG_ 2566860316 ProfLong_Val21_RsvdForSysSpecTyp "AS145";
BA_ "CI_SigName" SG_ 2566860316 ProfLong_Val20_RsvdForSysSpecTyp "Profile Long – Value 20 – Reserved for system specific types";
BA_ "CI_SigId" SG_ 2566860316 ProfLong_Val20_RsvdForSysSpecTyp 3706;
BA_ "CI_ParId" SG_ 2566860316 ProfLong_Val20_RsvdForSysSpecTyp "AS144";
BA_ "CI_SigName" SG_ 2566860316 ProfLong_Val19_RsvdForSysSpecTyp "Profile Long – Value 19 – Reserved for system specific types";
BA_ "CI_SigId" SG_ 2566860316 ProfLong_Val19_RsvdForSysSpecTyp 3705;
BA_ "CI_ParId" SG_ 2566860316 ProfLong_Val19_RsvdForSysSpecTyp "AS143";
BA_ "CI_SigName" SG_ 2566860316 ProfLong_Val18_RsvdForSysSpecTyp "Profile Long – Value 18 – Reserved for system specific types";
BA_ "CI_SigId" SG_ 2566860316 ProfLong_Val18_RsvdForSysSpecTyp 3704;
BA_ "CI_ParId" SG_ 2566860316 ProfLong_Val18_RsvdForSysSpecTyp "AS142";
BA_ "CI_SigName" SG_ 2566860316 ProfLong_Val17_RsvdForSysSpecTyp "Profile Long – Value 17 – Reserved for system specific types";
BA_ "CI_SigId" SG_ 2566860316 ProfLong_Val17_RsvdForSysSpecTyp 3703;
BA_ "CI_ParId" SG_ 2566860316 ProfLong_Val17_RsvdForSysSpecTyp "AS141";
BA_ "CI_SigName" SG_ 2566860316 ProfLong_Val16_RsvdForSysSpecTyp "Profile Long – Value 16 – Reserved for system specific types";
BA_ "CI_SigId" SG_ 2566860316 ProfLong_Val16_RsvdForSysSpecTyp 3702;
BA_ "CI_ParId" SG_ 2566860316 ProfLong_Val16_RsvdForSysSpecTyp "AS140";
BA_ "CI_SigName" SG_ 2566860316 ProfLong_Val15_RsvdForStdTypes "Profile Long – Value 15 – Reserved for standard types";
BA_ "CI_SigId" SG_ 2566860316 ProfLong_Val15_RsvdForStdTypes 3701;
BA_ "CI_ParId" SG_ 2566860316 ProfLong_Val15_RsvdForStdTypes "AS139";
BA_ "CI_SigName" SG_ 2566860316 ProfLong_Val14_RsvdForStdTypes "Profile Long – Value 14 – Reserved for standard types";
BA_ "CI_SigId" SG_ 2566860316 ProfLong_Val14_RsvdForStdTypes 3700;
BA_ "CI_ParId" SG_ 2566860316 ProfLong_Val14_RsvdForStdTypes "AS138";
BA_ "CI_SigName" SG_ 2566860316 ProfLong_Val13_RsvdForStdTypes "Profile Long – Value 13 – Reserved for standard types";
BA_ "CI_SigId" SG_ 2566860316 ProfLong_Val13_RsvdForStdTypes 3699;
BA_ "CI_ParId" SG_ 2566860316 ProfLong_Val13_RsvdForStdTypes "AS137";
BA_ "CI_SigName" SG_ 2566860316 ProfLong_Val12_RsvdForStdTypes "Profile Long – Value 12 – Reserved for standard types";
BA_ "CI_SigId" SG_ 2566860316 ProfLong_Val12_RsvdForStdTypes 3698;
BA_ "CI_ParId" SG_ 2566860316 ProfLong_Val12_RsvdForStdTypes "AS136";
BA_ "CI_SigName" SG_ 2566860316 ProfLong_Val11_RsvdForStdTypes "Profile Long – Value 11 – Reserved for standard types";
BA_ "CI_SigId" SG_ 2566860316 ProfLong_Val11_RsvdForStdTypes 3697;
BA_ "CI_ParId" SG_ 2566860316 ProfLong_Val11_RsvdForStdTypes "AS135";
BA_ "CI_SigName" SG_ 2566860316 ProfLong_Val10_RsvdForStdTypes "Profile Long – Value 10 – Reserved for standard types";
BA_ "CI_SigId" SG_ 2566860316 ProfLong_Val10_RsvdForStdTypes 3696;
BA_ "CI_ParId" SG_ 2566860316 ProfLong_Val10_RsvdForStdTypes "AS134";
BA_ "CI_SigName" SG_ 2566860316 ProfLong_Val9_RsvdForStdTypes "Profile Long – Value 9 – Reserved for standard types";
BA_ "CI_SigId" SG_ 2566860316 ProfLong_Val9_RsvdForStdTypes 3695;
BA_ "CI_ParId" SG_ 2566860316 ProfLong_Val9_RsvdForStdTypes "AS133";
BA_ "CI_SigName" SG_ 2566860316 ProfLong_Val8_RsvdForStdTypes "Profile Long – Value 8 – Reserved for standard types";
BA_ "CI_SigId" SG_ 2566860316 ProfLong_Val8_RsvdForStdTypes 3694;
BA_ "CI_ParId" SG_ 2566860316 ProfLong_Val8_RsvdForStdTypes "AS132";
BA_ "CI_SigName" SG_ 2566860316 ProfLong_Val7_RsvdForStdTypes "Profile Long – Value 7 – Reserved for standard types";
BA_ "CI_SigId" SG_ 2566860316 ProfLong_Val7_RsvdForStdTypes 3693;
BA_ "CI_ParId" SG_ 2566860316 ProfLong_Val7_RsvdForStdTypes "AS131";
BA_ "CI_SigName" SG_ 2566860316 ProfLong_Val6_RsvdForStdTypes "Profile Long – Value 6 – Reserved for standard types";
BA_ "CI_SigId" SG_ 2566860316 ProfLong_Val6_RsvdForStdTypes 3692;
BA_ "CI_ParId" SG_ 2566860316 ProfLong_Val6_RsvdForStdTypes "AS130";
BA_ "CI_SigName" SG_ 2566860316 ProfLong_Val5_RsvdForStdTypes "Profile Long – Value 5 – Reserved for standard types";
BA_ "CI_SigId" SG_ 2566860316 ProfLong_Val5_RsvdForStdTypes 3691;
BA_ "CI_ParId" SG_ 2566860316 ProfLong_Val5_RsvdForStdTypes "AS129";
BA_ "CI_SigName" SG_ 2566860316 ProfLong_Val4_RsvdForStdTypes "Profile Long – Value 4 – Reserved for standard types";
BA_ "CI_SigId" SG_ 2566860316 ProfLong_Val4_RsvdForStdTypes 3690;
BA_ "CI_ParId" SG_ 2566860316 ProfLong_Val4_RsvdForStdTypes "AS128";
BA_ "CI_SigName" SG_ 2566860316 ProfLong_Val3_RsvdForStdTypes "Profile Long – Value 3 – Reserved for standard types";
BA_ "CI_SigId" SG_ 2566860316 ProfLong_Val3_RsvdForStdTypes 3689;
BA_ "CI_ParId" SG_ 2566860316 ProfLong_Val3_RsvdForStdTypes "AS127";
BA_ "SigType" SG_ 2566860316 ProfLong_Val2_Lat 1;
BA_ "GenSigStartValue" SG_ 2566860316 ProfLong_Val2_Lat 900000000;
BA_ "CI_SigName" SG_ 2566860316 ProfLong_Val2_Lat "Profile Long – Value 2 – Latitude";
BA_ "CI_SigId" SG_ 2566860316 ProfLong_Val2_Lat 3688;
BA_ "CI_ParId" SG_ 2566860316 ProfLong_Val2_Lat "AS126";
BA_ "SigType" SG_ 2566860316 ProfLong_Val1_Long 1;
BA_ "GenSigStartValue" SG_ 2566860316 ProfLong_Val1_Long 1800000000;
BA_ "CI_SigName" SG_ 2566860316 ProfLong_Val1_Long "Profile Long – Value 1 – Longitude";
BA_ "CI_SigId" SG_ 2566860316 ProfLong_Val1_Long 3687;
BA_ "CI_ParId" SG_ 2566860316 ProfLong_Val1_Long "AS125";
BA_ "CI_SigName" SG_ 2566860316 ProfLong_Update "Profile Long – Update";
BA_ "CI_SigId" SG_ 2566860316 ProfLong_Update 3682;
BA_ "CI_ParId" SG_ 2566860316 ProfLong_Update "AS061";
BA_ "CI_SigName" SG_ 2566860316 ProfLong_Retr "Profile Long – Retransmission";
BA_ "CI_SigId" SG_ 2566860316 ProfLong_Retr 3683;
BA_ "CI_ParId" SG_ 2566860316 ProfLong_Retr "AS058";
BA_ "CI_SigName" SG_ 2566860316 ProfLong_CtrlPnt "Profile Long – Control Point";
BA_ "CI_SigId" SG_ 2566860316 ProfLong_CtrlPnt 3684;
BA_ "CI_ParId" SG_ 2566860316 ProfLong_CtrlPnt "AS063";
BA_ "CI_SigName" SG_ 2566860316 ProfLong_ProfType "Profile Long – Profile Type";
BA_ "CI_SigId" SG_ 2566860316 ProfLong_ProfType 3685;
BA_ "CI_ParId" SG_ 2566860316 ProfLong_ProfType "AS062";
BA_ "GenSigStartValue" SG_ 2566860316 ProfLong_PathIx 8;
BA_ "CI_SigName" SG_ 2566860316 ProfLong_PathIx "Profile Long – Path Index";
BA_ "CI_SigId" SG_ 2566860316 ProfLong_PathIx 3680;
BA_ "CI_ParId" SG_ 2566860316 ProfLong_PathIx "AS059";
BA_ "CI_SigName" SG_ 2566860316 ProfLong_CycCnt "Profile Long – Cyclic Counter";
BA_ "CI_SigId" SG_ 2566860316 ProfLong_CycCnt 3681;
BA_ "CI_ParId" SG_ 2566860316 ProfLong_CycCnt "AS057";
BA_ "CI_SigName" SG_ 2566860316 ProfLong_Ofs "Profile Long – Offset";
BA_ "CI_SigId" SG_ 2566860316 ProfLong_Ofs 3679;
BA_ "CI_ParId" SG_ 2566860316 ProfLong_Ofs "AS060";
BA_ "GenSigStartValue" SG_ 2566860316 MsgType_FF2E1C 6;
BA_ "CI_SigName" SG_ 2566860316 MsgType_FF2E1C "Message Type";
BA_ "CI_SigId" SG_ 2566860316 MsgType_FF2E1C 3678;
BA_ "CI_ParId" SG_ 2566860316 MsgType_FF2E1C "AS001";
BA_ "CI_SigName" SG_ 2566860572 Meta_MinorProtoVer "Meta-Data – Minor Protocol Version";
BA_ "CI_SigId" SG_ 2566860572 Meta_MinorProtoVer 3730;
BA_ "CI_ParId" SG_ 2566860572 Meta_MinorProtoVer "AS075";
BA_ "CI_SigName" SG_ 2566860572 Meta_SpeedUnits "Meta-Data – Speed Units";
BA_ "CI_SigId" SG_ 2566860572 Meta_SpeedUnits 3731;
BA_ "CI_ParId" SG_ 2566860572 Meta_SpeedUnits "AS073";
BA_ "CI_SigName" SG_ 2566860572 Meta_MapVerYr "Meta-Data – Map Version - Year";
BA_ "CI_SigId" SG_ 2566860572 Meta_MapVerYr 3728;
BA_ "CI_ParId" SG_ 2566860572 Meta_MapVerYr "AS079";
BA_ "CI_SigName" SG_ 2566860572 Meta_MapVerQtr "Meta-Data – Map Version - Year Quarter";
BA_ "CI_SigId" SG_ 2566860572 Meta_MapVerQtr 3729;
BA_ "CI_ParId" SG_ 2566860572 Meta_MapVerQtr "AS080";
BA_ "GenSigStartValue" SG_ 2566860572 Meta_RegionCode 32767;
BA_ "CI_SigName" SG_ 2566860572 Meta_RegionCode "Meta-Data – Region Code";
BA_ "CI_SigId" SG_ 2566860572 Meta_RegionCode 3727;
BA_ "CI_ParId" SG_ 2566860572 Meta_RegionCode "AS071";
BA_ "GenSigStartValue" SG_ 2566860572 Meta_DrivSide 1;
BA_ "CI_SigName" SG_ 2566860572 Meta_DrivSide "Meta-Data – Driving Side";
BA_ "CI_SigId" SG_ 2566860572 Meta_DrivSide 3726;
BA_ "CI_ParId" SG_ 2566860572 Meta_DrivSide "AS072";
BA_ "CI_SigName" SG_ 2566860572 Meta_HwVer "Meta-Data – Hardware Version";
BA_ "CI_SigId" SG_ 2566860572 Meta_HwVer 3725;
BA_ "CI_ParId" SG_ 2566860572 Meta_HwVer "AS077";
BA_ "CI_SigName" SG_ 2566860572 Meta_MinorProtoSubVer "Meta-Data – Minor Protocol Sub-Version";
BA_ "CI_SigId" SG_ 2566860572 Meta_MinorProtoSubVer 3722;
BA_ "CI_ParId" SG_ 2566860572 Meta_MinorProtoSubVer "AS076";
BA_ "CI_SigName" SG_ 2566860572 Meta_MajorProtoVer "Meta-Data – Major Protocol Version";
BA_ "CI_SigId" SG_ 2566860572 Meta_MajorProtoVer 3723;
BA_ "CI_ParId" SG_ 2566860572 Meta_MajorProtoVer "AS074";
BA_ "CI_SigName" SG_ 2566860572 Meta_CycCnt "Meta-Data – Cyclic Counter";
BA_ "CI_SigId" SG_ 2566860572 Meta_CycCnt 3724;
BA_ "CI_ParId" SG_ 2566860572 Meta_CycCnt "AS069";
BA_ "CI_SigName" SG_ 2566860572 Meta_CntryCode "Meta-Data – Country Code";
BA_ "CI_SigId" SG_ 2566860572 Meta_CntryCode 3721;
BA_ "CI_ParId" SG_ 2566860572 Meta_CntryCode "AS070";
BA_ "GenSigStartValue" SG_ 2566860572 Meta_MapProvider 7;
BA_ "CI_SigName" SG_ 2566860572 Meta_MapProvider "Meta-Data – Map Provider";
BA_ "CI_SigId" SG_ 2566860572 Meta_MapProvider 3720;
BA_ "CI_ParId" SG_ 2566860572 Meta_MapProvider "AS078";
BA_ "GenSigStartValue" SG_ 2566860572 MsgType_FF2F1C 6;
BA_ "CI_SigName" SG_ 2566860572 MsgType_FF2F1C "Message Type";
BA_ "CI_SigId" SG_ 2566860572 MsgType_FF2F1C 3719;
BA_ "CI_ParId" SG_ 2566860572 MsgType_FF2F1C "AS001";
BA_ "GenSigTimeoutTime_SGW" SG_ 2565804065 HandLevPos 500;
BA_ "GenSigTimeoutTime_PCM" SG_ 2565804065 HandLevPos 500;
BA_ "CI_SigName" SG_ 2565804065 HandLevPos "Hand Lever Position";
BA_ "CI_SigId" SG_ 2565804065 HandLevPos 2935;
BA_ "CI_ParId" SG_ 2565804065 HandLevPos "IS693";
BA_ "GenSigTimeoutTime_SGW" SG_ 2565804065 DisRetFtReq 500;
BA_ "GenSigTimeoutTime_PCM" SG_ 2565804065 DisRetFtReq 500;
BA_ "GenSigTimeoutTime_BSM_EBS" SG_ 2565804065 DisRetFtReq 500;
BA_ "CI_SigName" SG_ 2565804065 DisRetFtReq "Disable Retarder Foot Request";
BA_ "CI_SigId" SG_ 2565804065 DisRetFtReq 2933;
BA_ "CI_ParId" SG_ 2565804065 DisRetFtReq "IB010";
BA_ "SigType" SG_ 2566850593 CrkInh 4;
BA_ "GenSigTimeoutTime_SGW" SG_ 2566850593 CrkInh 500;
BA_ "GenSigTimeoutTime_PCM" SG_ 2566850593 CrkInh 500;
BA_ "GenSigTimeoutTime_ETC_DiwaNXT_MH" SG_ 2566850593 CrkInh 500;
BA_ "CI_SigName" SG_ 2566850593 CrkInh "Cranking Inhibit";
BA_ "CI_SigId" SG_ 2566850593 CrkInh 4379;
BA_ "CI_ParId" SG_ 2566850593 CrkInh "IB563";
BA_ "SigType" SG_ 2566850593 EngStartClear 4;
BA_ "GenSigTimeoutTime_SGW" SG_ 2566850593 EngStartClear 500;
BA_ "GenSigTimeoutTime_PCM" SG_ 2566850593 EngStartClear 500;
BA_ "GenSigTimeoutTime_ETC_DiwaNXT_MH" SG_ 2566850593 EngStartClear 500;
BA_ "CI_SigName" SG_ 2566850593 EngStartClear "Engine start Clearance";
BA_ "CI_SigId" SG_ 2566850593 EngStartClear 4378;
BA_ "CI_ParId" SG_ 2566850593 EngStartClear "IB562";
BA_ "SigType" SG_ 2566850593 EngStopClear 4;
BA_ "GenSigTimeoutTime_SGW" SG_ 2566850593 EngStopClear 500;
BA_ "GenSigTimeoutTime_PCM" SG_ 2566850593 EngStopClear 500;
BA_ "GenSigTimeoutTime_ETC_DiwaNXT_MH" SG_ 2566850593 EngStopClear 500;
BA_ "CI_SigName" SG_ 2566850593 EngStopClear "Engine stop Clearance";
BA_ "CI_SigId" SG_ 2566850593 EngStopClear 4377;
BA_ "CI_ParId" SG_ 2566850593 EngStopClear "IB561";
BA_ "SigType" SG_ 2566722906 BatChg1OutCur 1;
BA_ "SPN" SG_ 2566722906 BatChg1OutCur 4993;
BA_ "GenSigTimeoutTime_VMU" SG_ 2566722906 BatChg1OutCur 500;
BA_ "GenSigTimeoutTime_VCU" SG_ 2566722906 BatChg1OutCur 500;
BA_ "GenSigTimeoutTime_SGW" SG_ 2566722906 BatChg1OutCur 500;
BA_ "GenSigTimeoutTime_PCM" SG_ 2566722906 BatChg1OutCur 500;
BA_ "GenSigStartValue" SG_ 2566722906 BatChg1OutCur 32000;
BA_ "CI_SigName" SG_ 2566722906 BatChg1OutCur "Battery Charger 1 Output Current";
BA_ "CI_SigId" SG_ 2566722906 BatChg1OutCur 327;
BA_ "CI_ParId" SG_ 2566722906 BatChg1OutCur "4993";
BA_ "SigType" SG_ 2566722906 BatChg1OutV 1;
BA_ "SPN" SG_ 2566722906 BatChg1OutV 4992;
BA_ "GenSigTimeoutTime_VMU" SG_ 2566722906 BatChg1OutV 500;
BA_ "GenSigTimeoutTime_VCU" SG_ 2566722906 BatChg1OutV 500;
BA_ "GenSigTimeoutTime_SGW" SG_ 2566722906 BatChg1OutV 500;
BA_ "GenSigTimeoutTime_PCM" SG_ 2566722906 BatChg1OutV 500;
BA_ "CI_SigName" SG_ 2566722906 BatChg1OutV "Battery Charger 1 Output Voltage";
BA_ "CI_SigId" SG_ 2566722906 BatChg1OutV 326;
BA_ "CI_ParId" SG_ 2566722906 BatChg1OutV "4992";
BA_ "SigType" SG_ 2566722906 BatChg1PwrLineSts 4;
BA_ "SPN" SG_ 2566722906 BatChg1PwrLineSts 4991;
BA_ "GenSigTimeoutTime_VMU" SG_ 2566722906 BatChg1PwrLineSts 500;
BA_ "GenSigTimeoutTime_VCU" SG_ 2566722906 BatChg1PwrLineSts 500;
BA_ "GenSigTimeoutTime_SGW" SG_ 2566722906 BatChg1PwrLineSts 500;
BA_ "GenSigTimeoutTime_PCM" SG_ 2566722906 BatChg1PwrLineSts 500;
BA_ "CI_SigName" SG_ 2566722906 BatChg1PwrLineSts "Battery Charger 1 Power Line State";
BA_ "CI_SigId" SG_ 2566722906 BatChg1PwrLineSts 325;
BA_ "CI_ParId" SG_ 2566722906 BatChg1PwrLineSts "4991";
BA_ "SPN" SG_ 2566722906 BatChg1Sts 4990;
BA_ "GenSigTimeoutTime_VMU" SG_ 2566722906 BatChg1Sts 500;
BA_ "GenSigTimeoutTime_VCU" SG_ 2566722906 BatChg1Sts 500;
BA_ "GenSigTimeoutTime_SGW" SG_ 2566722906 BatChg1Sts 500;
BA_ "GenSigTimeoutTime_PCM" SG_ 2566722906 BatChg1Sts 500;
BA_ "CI_SigName" SG_ 2566722906 BatChg1Sts "Battery Charger 1 State";
BA_ "CI_SigId" SG_ 2566722906 BatChg1Sts 324;
BA_ "CI_ParId" SG_ 2566722906 BatChg1Sts "4990";
BA_ "SigType" SG_ 2566906099 Bms0IMinCellTemp 1;
BA_ "GenSigTimeoutTime_SGW" SG_ 2566906099 Bms0IMinCellTemp 25000;
BA_ "GenSigTimeoutTime_PCM" SG_ 2566906099 Bms0IMinCellTemp 25000;
BA_ "GenSigTimeoutTime_MPPxPTFE2" SG_ 2566906099 Bms0IMinCellTemp 25000;
BA_ "GenSigTimeoutTime_IC_MulticII" SG_ 2566906099 Bms0IMinCellTemp 25000;
BA_ "GenSigTimeoutTime_FMS_FMS4" SG_ 2566906099 Bms0IMinCellTemp 25000;
BA_ "GenSigStartValue" SG_ 2566906099 Bms0IMinCellTemp 40;
BA_ "CI_SigName" SG_ 2566906099 Bms0IMinCellTemp "BMS0i Min Cell Temperature";
BA_ "CI_SigId" SG_ 2566906099 Bms0IMinCellTemp 10727;
BA_ "CI_ParId" SG_ 2566906099 Bms0IMinCellTemp "IB583";
BA_ "SigType" SG_ 2566906099 Bms0IMaxCellTemp 1;
BA_ "GenSigTimeoutTime_SGW" SG_ 2566906099 Bms0IMaxCellTemp 25000;
BA_ "GenSigTimeoutTime_PCM" SG_ 2566906099 Bms0IMaxCellTemp 25000;
BA_ "GenSigTimeoutTime_MPPxPTFE2" SG_ 2566906099 Bms0IMaxCellTemp 25000;
BA_ "GenSigTimeoutTime_IC_MulticII" SG_ 2566906099 Bms0IMaxCellTemp 25000;
BA_ "GenSigTimeoutTime_FMS_FMS4" SG_ 2566906099 Bms0IMaxCellTemp 25000;
BA_ "GenSigStartValue" SG_ 2566906099 Bms0IMaxCellTemp 40;
BA_ "CI_SigName" SG_ 2566906099 Bms0IMaxCellTemp "BMS0i Max Cell Temperature";
BA_ "CI_SigId" SG_ 2566906099 Bms0IMaxCellTemp 10726;
BA_ "CI_ParId" SG_ 2566906099 Bms0IMaxCellTemp "IB582";
BA_ "GenSigTimeoutTime_SGW" SG_ 2566906099 Bms0IPwrDistributed 25000;
BA_ "GenSigTimeoutTime_PCM" SG_ 2566906099 Bms0IPwrDistributed 25000;
BA_ "GenSigTimeoutTime_MPPxPTFE2" SG_ 2566906099 Bms0IPwrDistributed 25000;
BA_ "GenSigTimeoutTime_IC_MulticII" SG_ 2566906099 Bms0IPwrDistributed 25000;
BA_ "GenSigTimeoutTime_FMS_FMS4" SG_ 2566906099 Bms0IPwrDistributed 25000;
BA_ "CI_SigName" SG_ 2566906099 Bms0IPwrDistributed "BMS0i Power Distributed";
BA_ "CI_SigId" SG_ 2566906099 Bms0IPwrDistributed 10725;
BA_ "CI_ParId" SG_ 2566906099 Bms0IPwrDistributed "IB581";
BA_ "GenSigTimeoutTime_SGW" SG_ 2566906099 Bms0IChgCompl 25000;
BA_ "GenSigTimeoutTime_PCM" SG_ 2566906099 Bms0IChgCompl 25000;
BA_ "GenSigTimeoutTime_MPPxPTFE2" SG_ 2566906099 Bms0IChgCompl 25000;
BA_ "GenSigTimeoutTime_IC_MulticII" SG_ 2566906099 Bms0IChgCompl 25000;
BA_ "GenSigTimeoutTime_FMS_FMS4" SG_ 2566906099 Bms0IChgCompl 25000;
BA_ "CI_SigName" SG_ 2566906099 Bms0IChgCompl "BMS0i Charge Completed";
BA_ "CI_SigId" SG_ 2566906099 Bms0IChgCompl 10724;
BA_ "CI_ParId" SG_ 2566906099 Bms0IChgCompl "IB580";
BA_ "SigType" SG_ 2566906099 Bms0IOpSts 4;
BA_ "GenSigTimeoutTime_SGW" SG_ 2566906099 Bms0IOpSts 25000;
BA_ "GenSigTimeoutTime_PCM" SG_ 2566906099 Bms0IOpSts 25000;
BA_ "GenSigTimeoutTime_MPPxPTFE2" SG_ 2566906099 Bms0IOpSts 25000;
BA_ "GenSigTimeoutTime_IC_MulticII" SG_ 2566906099 Bms0IOpSts 25000;
BA_ "GenSigTimeoutTime_FMS_FMS4" SG_ 2566906099 Bms0IOpSts 25000;
BA_ "CI_SigName" SG_ 2566906099 Bms0IOpSts "BMS0i Operating Status";
BA_ "CI_SigId" SG_ 2566906099 Bms0IOpSts 10723;
BA_ "CI_ParId" SG_ 2566906099 Bms0IOpSts "IB579";
BA_ "GenSigTimeoutTime_SGW" SG_ 2566906099 Bms0IActSts 25000;
BA_ "GenSigTimeoutTime_PCM" SG_ 2566906099 Bms0IActSts 25000;
BA_ "GenSigTimeoutTime_MPPxPTFE2" SG_ 2566906099 Bms0IActSts 25000;
BA_ "GenSigTimeoutTime_IC_MulticII" SG_ 2566906099 Bms0IActSts 25000;
BA_ "GenSigTimeoutTime_FMS_FMS4" SG_ 2566906099 Bms0IActSts 25000;
BA_ "CI_SigName" SG_ 2566906099 Bms0IActSts "BMS0i Actual State";
BA_ "CI_SigId" SG_ 2566906099 Bms0IActSts 10722;
BA_ "CI_ParId" SG_ 2566906099 Bms0IActSts "IB578";
BA_ "GenSigTimeoutTime_SGW" SG_ 2566906099 Bms0IEqualizationSts 25000;
BA_ "GenSigTimeoutTime_PCM" SG_ 2566906099 Bms0IEqualizationSts 25000;
BA_ "GenSigTimeoutTime_MPPxPTFE2" SG_ 2566906099 Bms0IEqualizationSts 25000;
BA_ "GenSigTimeoutTime_IC_MulticII" SG_ 2566906099 Bms0IEqualizationSts 25000;
BA_ "GenSigTimeoutTime_FMS_FMS4" SG_ 2566906099 Bms0IEqualizationSts 25000;
BA_ "CI_SigName" SG_ 2566906099 Bms0IEqualizationSts "BMS0i Equalization Status";
BA_ "CI_SigId" SG_ 2566906099 Bms0IEqualizationSts 10721;
BA_ "CI_ParId" SG_ 2566906099 Bms0IEqualizationSts "IB577";
BA_ "SigType" SG_ 2566906099 Bms0IMinCellV 1;
BA_ "GenSigTimeoutTime_SGW" SG_ 2566906099 Bms0IMinCellV 25000;
BA_ "GenSigTimeoutTime_PCM" SG_ 2566906099 Bms0IMinCellV 25000;
BA_ "GenSigTimeoutTime_MPPxPTFE2" SG_ 2566906099 Bms0IMinCellV 25000;
BA_ "GenSigTimeoutTime_IC_MulticII" SG_ 2566906099 Bms0IMinCellV 25000;
BA_ "GenSigTimeoutTime_FMS_FMS4" SG_ 2566906099 Bms0IMinCellV 25000;
BA_ "CI_SigName" SG_ 2566906099 Bms0IMinCellV "BMS0i Min Cell Voltage";
BA_ "CI_SigId" SG_ 2566906099 Bms0IMinCellV 10720;
BA_ "CI_ParId" SG_ 2566906099 Bms0IMinCellV "IB576";
BA_ "SigType" SG_ 2566906099 Bms0IMaxCellV 1;
BA_ "GenSigTimeoutTime_SGW" SG_ 2566906099 Bms0IMaxCellV 25000;
BA_ "GenSigTimeoutTime_PCM" SG_ 2566906099 Bms0IMaxCellV 25000;
BA_ "GenSigTimeoutTime_MPPxPTFE2" SG_ 2566906099 Bms0IMaxCellV 25000;
BA_ "GenSigTimeoutTime_IC_MulticII" SG_ 2566906099 Bms0IMaxCellV 25000;
BA_ "GenSigTimeoutTime_FMS_FMS4" SG_ 2566906099 Bms0IMaxCellV 25000;
BA_ "CI_SigName" SG_ 2566906099 Bms0IMaxCellV "BMS0i Max Cell Voltage";
BA_ "CI_SigId" SG_ 2566906099 Bms0IMaxCellV 10719;
BA_ "CI_ParId" SG_ 2566906099 Bms0IMaxCellV "IB575";
BA_ "SigType" SG_ 2566906099 Bms0IBatSoc 1;
BA_ "GenSigTimeoutTime_SGW" SG_ 2566906099 Bms0IBatSoc 25000;
BA_ "GenSigTimeoutTime_PCM" SG_ 2566906099 Bms0IBatSoc 25000;
BA_ "GenSigTimeoutTime_MPPxPTFE2" SG_ 2566906099 Bms0IBatSoc 25000;
BA_ "GenSigTimeoutTime_IC_MulticII" SG_ 2566906099 Bms0IBatSoc 25000;
BA_ "GenSigTimeoutTime_FMS_FMS4" SG_ 2566906099 Bms0IBatSoc 25000;
BA_ "CI_SigName" SG_ 2566906099 Bms0IBatSoc "BMS0i Battery SOC";
BA_ "CI_SigId" SG_ 2566906099 Bms0IBatSoc 10718;
BA_ "CI_ParId" SG_ 2566906099 Bms0IBatSoc "IB574";
BA_ "SigType" SG_ 2566906099 Bms0IBatCur 1;
BA_ "GenSigTimeoutTime_SGW" SG_ 2566906099 Bms0IBatCur 25000;
BA_ "GenSigTimeoutTime_PCM" SG_ 2566906099 Bms0IBatCur 25000;
BA_ "GenSigTimeoutTime_MPPxPTFE2" SG_ 2566906099 Bms0IBatCur 25000;
BA_ "GenSigTimeoutTime_IC_MulticII" SG_ 2566906099 Bms0IBatCur 25000;
BA_ "GenSigTimeoutTime_FMS_FMS4" SG_ 2566906099 Bms0IBatCur 25000;
BA_ "GenSigStartValue" SG_ 2566906099 Bms0IBatCur 125;
BA_ "CI_SigName" SG_ 2566906099 Bms0IBatCur "BMS0i Battery Current";
BA_ "CI_SigId" SG_ 2566906099 Bms0IBatCur 10717;
BA_ "CI_ParId" SG_ 2566906099 Bms0IBatCur "IB573";
BA_ "SigType" SG_ 2566906099 Bms0IBatV 1;
BA_ "GenSigTimeoutTime_SGW" SG_ 2566906099 Bms0IBatV 25000;
BA_ "GenSigTimeoutTime_PCM" SG_ 2566906099 Bms0IBatV 25000;
BA_ "GenSigTimeoutTime_MPPxPTFE2" SG_ 2566906099 Bms0IBatV 25000;
BA_ "GenSigTimeoutTime_IC_MulticII" SG_ 2566906099 Bms0IBatV 25000;
BA_ "GenSigTimeoutTime_FMS_FMS4" SG_ 2566906099 Bms0IBatV 25000;
BA_ "CI_SigName" SG_ 2566906099 Bms0IBatV "BMS0i Battery Voltage";
BA_ "CI_SigId" SG_ 2566906099 Bms0IBatV 10716;
BA_ "CI_ParId" SG_ 2566906099 Bms0IBatV "IB572";
BA_ "SigType" SG_ 2566906355 Bms0IMinCellTemp_FFE1F3 1;
BA_ "GenSigTimeoutTime_SGW" SG_ 2566906355 Bms0IMinCellTemp_FFE1F3 25000;
BA_ "GenSigTimeoutTime_PCM" SG_ 2566906355 Bms0IMinCellTemp_FFE1F3 25000;
BA_ "GenSigTimeoutTime_MPPxPTFE2" SG_ 2566906355 Bms0IMinCellTemp_FFE1F3 25000;
BA_ "GenSigTimeoutTime_IC_MulticII" SG_ 2566906355 Bms0IMinCellTemp_FFE1F3 25000;
BA_ "GenSigTimeoutTime_FMS_FMS4" SG_ 2566906355 Bms0IMinCellTemp_FFE1F3 25000;
BA_ "GenSigStartValue" SG_ 2566906355 Bms0IMinCellTemp_FFE1F3 40;
BA_ "CI_SigName" SG_ 2566906355 Bms0IMinCellTemp_FFE1F3 "BMS0i Min Cell Temperature";
BA_ "CI_SigId" SG_ 2566906355 Bms0IMinCellTemp_FFE1F3 10740;
BA_ "CI_ParId" SG_ 2566906355 Bms0IMinCellTemp_FFE1F3 "IB583";
BA_ "SigType" SG_ 2566906355 Bms0IMaxCellTemp_FFE1F3 1;
BA_ "GenSigTimeoutTime_SGW" SG_ 2566906355 Bms0IMaxCellTemp_FFE1F3 25000;
BA_ "GenSigTimeoutTime_PCM" SG_ 2566906355 Bms0IMaxCellTemp_FFE1F3 25000;
BA_ "GenSigTimeoutTime_MPPxPTFE2" SG_ 2566906355 Bms0IMaxCellTemp_FFE1F3 25000;
BA_ "GenSigTimeoutTime_IC_MulticII" SG_ 2566906355 Bms0IMaxCellTemp_FFE1F3 25000;
BA_ "GenSigTimeoutTime_FMS_FMS4" SG_ 2566906355 Bms0IMaxCellTemp_FFE1F3 25000;
BA_ "GenSigStartValue" SG_ 2566906355 Bms0IMaxCellTemp_FFE1F3 40;
BA_ "CI_SigName" SG_ 2566906355 Bms0IMaxCellTemp_FFE1F3 "BMS0i Max Cell Temperature";
BA_ "CI_SigId" SG_ 2566906355 Bms0IMaxCellTemp_FFE1F3 10739;
BA_ "CI_ParId" SG_ 2566906355 Bms0IMaxCellTemp_FFE1F3 "IB582";
BA_ "GenSigTimeoutTime_SGW" SG_ 2566906355 Bms0IPwrDistributed_FFE1F3 25000;
BA_ "GenSigTimeoutTime_PCM" SG_ 2566906355 Bms0IPwrDistributed_FFE1F3 25000;
BA_ "GenSigTimeoutTime_MPPxPTFE2" SG_ 2566906355 Bms0IPwrDistributed_FFE1F3 25000;
BA_ "GenSigTimeoutTime_IC_MulticII" SG_ 2566906355 Bms0IPwrDistributed_FFE1F3 25000;
BA_ "GenSigTimeoutTime_FMS_FMS4" SG_ 2566906355 Bms0IPwrDistributed_FFE1F3 25000;
BA_ "CI_SigName" SG_ 2566906355 Bms0IPwrDistributed_FFE1F3 "BMS0i Power Distributed";
BA_ "CI_SigId" SG_ 2566906355 Bms0IPwrDistributed_FFE1F3 10738;
BA_ "CI_ParId" SG_ 2566906355 Bms0IPwrDistributed_FFE1F3 "IB581";
BA_ "GenSigTimeoutTime_SGW" SG_ 2566906355 Bms0IChgCompl_FFE1F3 25000;
BA_ "GenSigTimeoutTime_PCM" SG_ 2566906355 Bms0IChgCompl_FFE1F3 25000;
BA_ "GenSigTimeoutTime_MPPxPTFE2" SG_ 2566906355 Bms0IChgCompl_FFE1F3 25000;
BA_ "GenSigTimeoutTime_IC_MulticII" SG_ 2566906355 Bms0IChgCompl_FFE1F3 25000;
BA_ "GenSigTimeoutTime_FMS_FMS4" SG_ 2566906355 Bms0IChgCompl_FFE1F3 25000;
BA_ "CI_SigName" SG_ 2566906355 Bms0IChgCompl_FFE1F3 "BMS0i Charge Completed";
BA_ "CI_SigId" SG_ 2566906355 Bms0IChgCompl_FFE1F3 10737;
BA_ "CI_ParId" SG_ 2566906355 Bms0IChgCompl_FFE1F3 "IB580";
BA_ "SigType" SG_ 2566906355 Bms0IOpSts_FFE1F3 4;
BA_ "GenSigTimeoutTime_SGW" SG_ 2566906355 Bms0IOpSts_FFE1F3 25000;
BA_ "GenSigTimeoutTime_PCM" SG_ 2566906355 Bms0IOpSts_FFE1F3 25000;
BA_ "GenSigTimeoutTime_MPPxPTFE2" SG_ 2566906355 Bms0IOpSts_FFE1F3 25000;
BA_ "GenSigTimeoutTime_IC_MulticII" SG_ 2566906355 Bms0IOpSts_FFE1F3 25000;
BA_ "GenSigTimeoutTime_FMS_FMS4" SG_ 2566906355 Bms0IOpSts_FFE1F3 25000;
BA_ "CI_SigName" SG_ 2566906355 Bms0IOpSts_FFE1F3 "BMS0i Operating Status";
BA_ "CI_SigId" SG_ 2566906355 Bms0IOpSts_FFE1F3 10736;
BA_ "CI_ParId" SG_ 2566906355 Bms0IOpSts_FFE1F3 "IB579";
BA_ "GenSigTimeoutTime_SGW" SG_ 2566906355 Bms0IActSts_FFE1F3 25000;
BA_ "GenSigTimeoutTime_PCM" SG_ 2566906355 Bms0IActSts_FFE1F3 25000;
BA_ "GenSigTimeoutTime_MPPxPTFE2" SG_ 2566906355 Bms0IActSts_FFE1F3 25000;
BA_ "GenSigTimeoutTime_IC_MulticII" SG_ 2566906355 Bms0IActSts_FFE1F3 25000;
BA_ "GenSigTimeoutTime_FMS_FMS4" SG_ 2566906355 Bms0IActSts_FFE1F3 25000;
BA_ "CI_SigName" SG_ 2566906355 Bms0IActSts_FFE1F3 "BMS0i Actual State";
BA_ "CI_SigId" SG_ 2566906355 Bms0IActSts_FFE1F3 10735;
BA_ "CI_ParId" SG_ 2566906355 Bms0IActSts_FFE1F3 "IB578";
BA_ "GenSigTimeoutTime_SGW" SG_ 2566906355 Bms0IEqualizationSts_FFE1F3 25000;
BA_ "GenSigTimeoutTime_PCM" SG_ 2566906355 Bms0IEqualizationSts_FFE1F3 25000;
BA_ "GenSigTimeoutTime_MPPxPTFE2" SG_ 2566906355 Bms0IEqualizationSts_FFE1F3 25000;
BA_ "GenSigTimeoutTime_IC_MulticII" SG_ 2566906355 Bms0IEqualizationSts_FFE1F3 25000;
BA_ "GenSigTimeoutTime_FMS_FMS4" SG_ 2566906355 Bms0IEqualizationSts_FFE1F3 25000;
BA_ "CI_SigName" SG_ 2566906355 Bms0IEqualizationSts_FFE1F3 "BMS0i Equalization Status";
BA_ "CI_SigId" SG_ 2566906355 Bms0IEqualizationSts_FFE1F3 10734;
BA_ "CI_ParId" SG_ 2566906355 Bms0IEqualizationSts_FFE1F3 "IB577";
BA_ "SigType" SG_ 2566906355 Bms0IMinCellV_FFE1F3 1;
BA_ "GenSigTimeoutTime_SGW" SG_ 2566906355 Bms0IMinCellV_FFE1F3 25000;
BA_ "GenSigTimeoutTime_PCM" SG_ 2566906355 Bms0IMinCellV_FFE1F3 25000;
BA_ "GenSigTimeoutTime_MPPxPTFE2" SG_ 2566906355 Bms0IMinCellV_FFE1F3 25000;
BA_ "GenSigTimeoutTime_IC_MulticII" SG_ 2566906355 Bms0IMinCellV_FFE1F3 25000;
BA_ "GenSigTimeoutTime_FMS_FMS4" SG_ 2566906355 Bms0IMinCellV_FFE1F3 25000;
BA_ "CI_SigName" SG_ 2566906355 Bms0IMinCellV_FFE1F3 "BMS0i Min Cell Voltage";
BA_ "CI_SigId" SG_ 2566906355 Bms0IMinCellV_FFE1F3 10733;
BA_ "CI_ParId" SG_ 2566906355 Bms0IMinCellV_FFE1F3 "IB576";
BA_ "SigType" SG_ 2566906355 Bms0IMaxCellV_FFE1F3 1;
BA_ "GenSigTimeoutTime_SGW" SG_ 2566906355 Bms0IMaxCellV_FFE1F3 25000;
BA_ "GenSigTimeoutTime_PCM" SG_ 2566906355 Bms0IMaxCellV_FFE1F3 25000;
BA_ "GenSigTimeoutTime_MPPxPTFE2" SG_ 2566906355 Bms0IMaxCellV_FFE1F3 25000;
BA_ "GenSigTimeoutTime_IC_MulticII" SG_ 2566906355 Bms0IMaxCellV_FFE1F3 25000;
BA_ "GenSigTimeoutTime_FMS_FMS4" SG_ 2566906355 Bms0IMaxCellV_FFE1F3 25000;
BA_ "CI_SigName" SG_ 2566906355 Bms0IMaxCellV_FFE1F3 "BMS0i Max Cell Voltage";
BA_ "CI_SigId" SG_ 2566906355 Bms0IMaxCellV_FFE1F3 10732;
BA_ "CI_ParId" SG_ 2566906355 Bms0IMaxCellV_FFE1F3 "IB575";
BA_ "SigType" SG_ 2566906355 Bms0IBatSoc_FFE1F3 1;
BA_ "GenSigTimeoutTime_SGW" SG_ 2566906355 Bms0IBatSoc_FFE1F3 25000;
BA_ "GenSigTimeoutTime_PCM" SG_ 2566906355 Bms0IBatSoc_FFE1F3 25000;
BA_ "GenSigTimeoutTime_MPPxPTFE2" SG_ 2566906355 Bms0IBatSoc_FFE1F3 25000;
BA_ "GenSigTimeoutTime_IC_MulticII" SG_ 2566906355 Bms0IBatSoc_FFE1F3 25000;
BA_ "GenSigTimeoutTime_FMS_FMS4" SG_ 2566906355 Bms0IBatSoc_FFE1F3 25000;
BA_ "CI_SigName" SG_ 2566906355 Bms0IBatSoc_FFE1F3 "BMS0i Battery SOC";
BA_ "CI_SigId" SG_ 2566906355 Bms0IBatSoc_FFE1F3 10731;
BA_ "CI_ParId" SG_ 2566906355 Bms0IBatSoc_FFE1F3 "IB574";
BA_ "SigType" SG_ 2566906355 Bms0IBatCur_FFE1F3 1;
BA_ "GenSigTimeoutTime_SGW" SG_ 2566906355 Bms0IBatCur_FFE1F3 25000;
BA_ "GenSigTimeoutTime_PCM" SG_ 2566906355 Bms0IBatCur_FFE1F3 25000;
BA_ "GenSigTimeoutTime_MPPxPTFE2" SG_ 2566906355 Bms0IBatCur_FFE1F3 25000;
BA_ "GenSigTimeoutTime_IC_MulticII" SG_ 2566906355 Bms0IBatCur_FFE1F3 25000;
BA_ "GenSigTimeoutTime_FMS_FMS4" SG_ 2566906355 Bms0IBatCur_FFE1F3 25000;
BA_ "GenSigStartValue" SG_ 2566906355 Bms0IBatCur_FFE1F3 125;
BA_ "CI_SigName" SG_ 2566906355 Bms0IBatCur_FFE1F3 "BMS0i Battery Current";
BA_ "CI_SigId" SG_ 2566906355 Bms0IBatCur_FFE1F3 10730;
BA_ "CI_ParId" SG_ 2566906355 Bms0IBatCur_FFE1F3 "IB573";
BA_ "SigType" SG_ 2566906355 Bms0IBatV_FFE1F3 1;
BA_ "GenSigTimeoutTime_SGW" SG_ 2566906355 Bms0IBatV_FFE1F3 25000;
BA_ "GenSigTimeoutTime_PCM" SG_ 2566906355 Bms0IBatV_FFE1F3 25000;
BA_ "GenSigTimeoutTime_MPPxPTFE2" SG_ 2566906355 Bms0IBatV_FFE1F3 25000;
BA_ "GenSigTimeoutTime_IC_MulticII" SG_ 2566906355 Bms0IBatV_FFE1F3 25000;
BA_ "GenSigTimeoutTime_FMS_FMS4" SG_ 2566906355 Bms0IBatV_FFE1F3 25000;
BA_ "CI_SigName" SG_ 2566906355 Bms0IBatV_FFE1F3 "BMS0i Battery Voltage";
BA_ "CI_SigId" SG_ 2566906355 Bms0IBatV_FFE1F3 10729;
BA_ "CI_ParId" SG_ 2566906355 Bms0IBatV_FFE1F3 "IB572";
BA_ "SigType" SG_ 2566906611 Bms0IMinCellTemp_FFE2F3 1;
BA_ "GenSigTimeoutTime_SGW" SG_ 2566906611 Bms0IMinCellTemp_FFE2F3 25000;
BA_ "GenSigTimeoutTime_PCM" SG_ 2566906611 Bms0IMinCellTemp_FFE2F3 25000;
BA_ "GenSigTimeoutTime_MPPxPTFE2" SG_ 2566906611 Bms0IMinCellTemp_FFE2F3 25000;
BA_ "GenSigTimeoutTime_IC_MulticII" SG_ 2566906611 Bms0IMinCellTemp_FFE2F3 25000;
BA_ "GenSigTimeoutTime_FMS_FMS4" SG_ 2566906611 Bms0IMinCellTemp_FFE2F3 25000;
BA_ "GenSigStartValue" SG_ 2566906611 Bms0IMinCellTemp_FFE2F3 40;
BA_ "CI_SigName" SG_ 2566906611 Bms0IMinCellTemp_FFE2F3 "BMS0i Min Cell Temperature";
BA_ "CI_SigId" SG_ 2566906611 Bms0IMinCellTemp_FFE2F3 10753;
BA_ "CI_ParId" SG_ 2566906611 Bms0IMinCellTemp_FFE2F3 "IB583";
BA_ "SigType" SG_ 2566906611 Bms0IMaxCellTemp_FFE2F3 1;
BA_ "GenSigTimeoutTime_SGW" SG_ 2566906611 Bms0IMaxCellTemp_FFE2F3 25000;
BA_ "GenSigTimeoutTime_PCM" SG_ 2566906611 Bms0IMaxCellTemp_FFE2F3 25000;
BA_ "GenSigTimeoutTime_MPPxPTFE2" SG_ 2566906611 Bms0IMaxCellTemp_FFE2F3 25000;
BA_ "GenSigTimeoutTime_IC_MulticII" SG_ 2566906611 Bms0IMaxCellTemp_FFE2F3 25000;
BA_ "GenSigTimeoutTime_FMS_FMS4" SG_ 2566906611 Bms0IMaxCellTemp_FFE2F3 25000;
BA_ "GenSigStartValue" SG_ 2566906611 Bms0IMaxCellTemp_FFE2F3 40;
BA_ "CI_SigName" SG_ 2566906611 Bms0IMaxCellTemp_FFE2F3 "BMS0i Max Cell Temperature";
BA_ "CI_SigId" SG_ 2566906611 Bms0IMaxCellTemp_FFE2F3 10752;
BA_ "CI_ParId" SG_ 2566906611 Bms0IMaxCellTemp_FFE2F3 "IB582";
BA_ "GenSigTimeoutTime_SGW" SG_ 2566906611 Bms0IPwrDistributed_FFE2F3 25000;
BA_ "GenSigTimeoutTime_PCM" SG_ 2566906611 Bms0IPwrDistributed_FFE2F3 25000;
BA_ "GenSigTimeoutTime_MPPxPTFE2" SG_ 2566906611 Bms0IPwrDistributed_FFE2F3 25000;
BA_ "GenSigTimeoutTime_IC_MulticII" SG_ 2566906611 Bms0IPwrDistributed_FFE2F3 25000;
BA_ "GenSigTimeoutTime_FMS_FMS4" SG_ 2566906611 Bms0IPwrDistributed_FFE2F3 25000;
BA_ "CI_SigName" SG_ 2566906611 Bms0IPwrDistributed_FFE2F3 "BMS0i Power Distributed";
BA_ "CI_SigId" SG_ 2566906611 Bms0IPwrDistributed_FFE2F3 10751;
BA_ "CI_ParId" SG_ 2566906611 Bms0IPwrDistributed_FFE2F3 "IB581";
BA_ "GenSigTimeoutTime_SGW" SG_ 2566906611 Bms0IChgCompl_FFE2F3 25000;
BA_ "GenSigTimeoutTime_PCM" SG_ 2566906611 Bms0IChgCompl_FFE2F3 25000;
BA_ "GenSigTimeoutTime_MPPxPTFE2" SG_ 2566906611 Bms0IChgCompl_FFE2F3 25000;
BA_ "GenSigTimeoutTime_IC_MulticII" SG_ 2566906611 Bms0IChgCompl_FFE2F3 25000;
BA_ "GenSigTimeoutTime_FMS_FMS4" SG_ 2566906611 Bms0IChgCompl_FFE2F3 25000;
BA_ "CI_SigName" SG_ 2566906611 Bms0IChgCompl_FFE2F3 "BMS0i Charge Completed";
BA_ "CI_SigId" SG_ 2566906611 Bms0IChgCompl_FFE2F3 10750;
BA_ "CI_ParId" SG_ 2566906611 Bms0IChgCompl_FFE2F3 "IB580";
BA_ "SigType" SG_ 2566906611 Bms0IOpSts_FFE2F3 4;
BA_ "GenSigTimeoutTime_SGW" SG_ 2566906611 Bms0IOpSts_FFE2F3 25000;
BA_ "GenSigTimeoutTime_PCM" SG_ 2566906611 Bms0IOpSts_FFE2F3 25000;
BA_ "GenSigTimeoutTime_MPPxPTFE2" SG_ 2566906611 Bms0IOpSts_FFE2F3 25000;
BA_ "GenSigTimeoutTime_IC_MulticII" SG_ 2566906611 Bms0IOpSts_FFE2F3 25000;
BA_ "GenSigTimeoutTime_FMS_FMS4" SG_ 2566906611 Bms0IOpSts_FFE2F3 25000;
BA_ "CI_SigName" SG_ 2566906611 Bms0IOpSts_FFE2F3 "BMS0i Operating Status";
BA_ "CI_SigId" SG_ 2566906611 Bms0IOpSts_FFE2F3 10749;
BA_ "CI_ParId" SG_ 2566906611 Bms0IOpSts_FFE2F3 "IB579";
BA_ "GenSigTimeoutTime_SGW" SG_ 2566906611 Bms0IActSts_FFE2F3 25000;
BA_ "GenSigTimeoutTime_PCM" SG_ 2566906611 Bms0IActSts_FFE2F3 25000;
BA_ "GenSigTimeoutTime_MPPxPTFE2" SG_ 2566906611 Bms0IActSts_FFE2F3 25000;
BA_ "GenSigTimeoutTime_IC_MulticII" SG_ 2566906611 Bms0IActSts_FFE2F3 25000;
BA_ "GenSigTimeoutTime_FMS_FMS4" SG_ 2566906611 Bms0IActSts_FFE2F3 25000;
BA_ "CI_SigName" SG_ 2566906611 Bms0IActSts_FFE2F3 "BMS0i Actual State";
BA_ "CI_SigId" SG_ 2566906611 Bms0IActSts_FFE2F3 10748;
BA_ "CI_ParId" SG_ 2566906611 Bms0IActSts_FFE2F3 "IB578";
BA_ "GenSigTimeoutTime_SGW" SG_ 2566906611 Bms0IEqualizationSts_FFE2F3 25000;
BA_ "GenSigTimeoutTime_PCM" SG_ 2566906611 Bms0IEqualizationSts_FFE2F3 25000;
BA_ "GenSigTimeoutTime_MPPxPTFE2" SG_ 2566906611 Bms0IEqualizationSts_FFE2F3 25000;
BA_ "GenSigTimeoutTime_IC_MulticII" SG_ 2566906611 Bms0IEqualizationSts_FFE2F3 25000;
BA_ "GenSigTimeoutTime_FMS_FMS4" SG_ 2566906611 Bms0IEqualizationSts_FFE2F3 25000;
BA_ "CI_SigName" SG_ 2566906611 Bms0IEqualizationSts_FFE2F3 "BMS0i Equalization Status";
BA_ "CI_SigId" SG_ 2566906611 Bms0IEqualizationSts_FFE2F3 10747;
BA_ "CI_ParId" SG_ 2566906611 Bms0IEqualizationSts_FFE2F3 "IB577";
BA_ "SigType" SG_ 2566906611 Bms0IMinCellV_FFE2F3 1;
BA_ "GenSigTimeoutTime_SGW" SG_ 2566906611 Bms0IMinCellV_FFE2F3 25000;
BA_ "GenSigTimeoutTime_PCM" SG_ 2566906611 Bms0IMinCellV_FFE2F3 25000;
BA_ "GenSigTimeoutTime_MPPxPTFE2" SG_ 2566906611 Bms0IMinCellV_FFE2F3 25000;
BA_ "GenSigTimeoutTime_IC_MulticII" SG_ 2566906611 Bms0IMinCellV_FFE2F3 25000;
BA_ "GenSigTimeoutTime_FMS_FMS4" SG_ 2566906611 Bms0IMinCellV_FFE2F3 25000;
BA_ "CI_SigName" SG_ 2566906611 Bms0IMinCellV_FFE2F3 "BMS0i Min Cell Voltage";
BA_ "CI_SigId" SG_ 2566906611 Bms0IMinCellV_FFE2F3 10746;
BA_ "CI_ParId" SG_ 2566906611 Bms0IMinCellV_FFE2F3 "IB576";
BA_ "SigType" SG_ 2566906611 Bms0IMaxCellV_FFE2F3 1;
BA_ "GenSigTimeoutTime_SGW" SG_ 2566906611 Bms0IMaxCellV_FFE2F3 25000;
BA_ "GenSigTimeoutTime_PCM" SG_ 2566906611 Bms0IMaxCellV_FFE2F3 25000;
BA_ "GenSigTimeoutTime_MPPxPTFE2" SG_ 2566906611 Bms0IMaxCellV_FFE2F3 25000;
BA_ "GenSigTimeoutTime_IC_MulticII" SG_ 2566906611 Bms0IMaxCellV_FFE2F3 25000;
BA_ "GenSigTimeoutTime_FMS_FMS4" SG_ 2566906611 Bms0IMaxCellV_FFE2F3 25000;
BA_ "CI_SigName" SG_ 2566906611 Bms0IMaxCellV_FFE2F3 "BMS0i Max Cell Voltage";
BA_ "CI_SigId" SG_ 2566906611 Bms0IMaxCellV_FFE2F3 10745;
BA_ "CI_ParId" SG_ 2566906611 Bms0IMaxCellV_FFE2F3 "IB575";
BA_ "SigType" SG_ 2566906611 Bms0IBatSoc_FFE2F3 1;
BA_ "GenSigTimeoutTime_SGW" SG_ 2566906611 Bms0IBatSoc_FFE2F3 25000;
BA_ "GenSigTimeoutTime_PCM" SG_ 2566906611 Bms0IBatSoc_FFE2F3 25000;
BA_ "GenSigTimeoutTime_MPPxPTFE2" SG_ 2566906611 Bms0IBatSoc_FFE2F3 25000;
BA_ "GenSigTimeoutTime_IC_MulticII" SG_ 2566906611 Bms0IBatSoc_FFE2F3 25000;
BA_ "GenSigTimeoutTime_FMS_FMS4" SG_ 2566906611 Bms0IBatSoc_FFE2F3 25000;
BA_ "CI_SigName" SG_ 2566906611 Bms0IBatSoc_FFE2F3 "BMS0i Battery SOC";
BA_ "CI_SigId" SG_ 2566906611 Bms0IBatSoc_FFE2F3 10744;
BA_ "CI_ParId" SG_ 2566906611 Bms0IBatSoc_FFE2F3 "IB574";
BA_ "SigType" SG_ 2566906611 Bms0IBatCur_FFE2F3 1;
BA_ "GenSigTimeoutTime_SGW" SG_ 2566906611 Bms0IBatCur_FFE2F3 25000;
BA_ "GenSigTimeoutTime_PCM" SG_ 2566906611 Bms0IBatCur_FFE2F3 25000;
BA_ "GenSigTimeoutTime_MPPxPTFE2" SG_ 2566906611 Bms0IBatCur_FFE2F3 25000;
BA_ "GenSigTimeoutTime_IC_MulticII" SG_ 2566906611 Bms0IBatCur_FFE2F3 25000;
BA_ "GenSigTimeoutTime_FMS_FMS4" SG_ 2566906611 Bms0IBatCur_FFE2F3 25000;
BA_ "GenSigStartValue" SG_ 2566906611 Bms0IBatCur_FFE2F3 125;
BA_ "CI_SigName" SG_ 2566906611 Bms0IBatCur_FFE2F3 "BMS0i Battery Current";
BA_ "CI_SigId" SG_ 2566906611 Bms0IBatCur_FFE2F3 10743;
BA_ "CI_ParId" SG_ 2566906611 Bms0IBatCur_FFE2F3 "IB573";
BA_ "SigType" SG_ 2566906611 Bms0IBatV_FFE2F3 1;
BA_ "GenSigTimeoutTime_SGW" SG_ 2566906611 Bms0IBatV_FFE2F3 25000;
BA_ "GenSigTimeoutTime_PCM" SG_ 2566906611 Bms0IBatV_FFE2F3 25000;
BA_ "GenSigTimeoutTime_MPPxPTFE2" SG_ 2566906611 Bms0IBatV_FFE2F3 25000;
BA_ "GenSigTimeoutTime_IC_MulticII" SG_ 2566906611 Bms0IBatV_FFE2F3 25000;
BA_ "GenSigTimeoutTime_FMS_FMS4" SG_ 2566906611 Bms0IBatV_FFE2F3 25000;
BA_ "CI_SigName" SG_ 2566906611 Bms0IBatV_FFE2F3 "BMS0i Battery Voltage";
BA_ "CI_SigId" SG_ 2566906611 Bms0IBatV_FFE2F3 10742;
BA_ "CI_ParId" SG_ 2566906611 Bms0IBatV_FFE2F3 "IB572";
BA_ "SigType" SG_ 2566906867 Bms0IMinCellTemp_FFE3F3 1;
BA_ "GenSigTimeoutTime_SGW" SG_ 2566906867 Bms0IMinCellTemp_FFE3F3 25000;
BA_ "GenSigTimeoutTime_PCM" SG_ 2566906867 Bms0IMinCellTemp_FFE3F3 25000;
BA_ "GenSigTimeoutTime_MPPxPTFE2" SG_ 2566906867 Bms0IMinCellTemp_FFE3F3 25000;
BA_ "GenSigTimeoutTime_IC_MulticII" SG_ 2566906867 Bms0IMinCellTemp_FFE3F3 25000;
BA_ "GenSigTimeoutTime_FMS_FMS4" SG_ 2566906867 Bms0IMinCellTemp_FFE3F3 25000;
BA_ "GenSigStartValue" SG_ 2566906867 Bms0IMinCellTemp_FFE3F3 40;
BA_ "CI_SigName" SG_ 2566906867 Bms0IMinCellTemp_FFE3F3 "BMS0i Min Cell Temperature";
BA_ "CI_SigId" SG_ 2566906867 Bms0IMinCellTemp_FFE3F3 10766;
BA_ "CI_ParId" SG_ 2566906867 Bms0IMinCellTemp_FFE3F3 "IB583";
BA_ "SigType" SG_ 2566906867 Bms0IMaxCellTemp_FFE3F3 1;
BA_ "GenSigTimeoutTime_SGW" SG_ 2566906867 Bms0IMaxCellTemp_FFE3F3 25000;
BA_ "GenSigTimeoutTime_PCM" SG_ 2566906867 Bms0IMaxCellTemp_FFE3F3 25000;
BA_ "GenSigTimeoutTime_MPPxPTFE2" SG_ 2566906867 Bms0IMaxCellTemp_FFE3F3 25000;
BA_ "GenSigTimeoutTime_IC_MulticII" SG_ 2566906867 Bms0IMaxCellTemp_FFE3F3 25000;
BA_ "GenSigTimeoutTime_FMS_FMS4" SG_ 2566906867 Bms0IMaxCellTemp_FFE3F3 25000;
BA_ "GenSigStartValue" SG_ 2566906867 Bms0IMaxCellTemp_FFE3F3 40;
BA_ "CI_SigName" SG_ 2566906867 Bms0IMaxCellTemp_FFE3F3 "BMS0i Max Cell Temperature";
BA_ "CI_SigId" SG_ 2566906867 Bms0IMaxCellTemp_FFE3F3 10765;
BA_ "CI_ParId" SG_ 2566906867 Bms0IMaxCellTemp_FFE3F3 "IB582";
BA_ "GenSigTimeoutTime_SGW" SG_ 2566906867 Bms0IPwrDistributed_FFE3F3 25000;
BA_ "GenSigTimeoutTime_PCM" SG_ 2566906867 Bms0IPwrDistributed_FFE3F3 25000;
BA_ "GenSigTimeoutTime_MPPxPTFE2" SG_ 2566906867 Bms0IPwrDistributed_FFE3F3 25000;
BA_ "GenSigTimeoutTime_IC_MulticII" SG_ 2566906867 Bms0IPwrDistributed_FFE3F3 25000;
BA_ "GenSigTimeoutTime_FMS_FMS4" SG_ 2566906867 Bms0IPwrDistributed_FFE3F3 25000;
BA_ "CI_SigName" SG_ 2566906867 Bms0IPwrDistributed_FFE3F3 "BMS0i Power Distributed";
BA_ "CI_SigId" SG_ 2566906867 Bms0IPwrDistributed_FFE3F3 10764;
BA_ "CI_ParId" SG_ 2566906867 Bms0IPwrDistributed_FFE3F3 "IB581";
BA_ "GenSigTimeoutTime_SGW" SG_ 2566906867 Bms0IChgCompl_FFE3F3 25000;
BA_ "GenSigTimeoutTime_PCM" SG_ 2566906867 Bms0IChgCompl_FFE3F3 25000;
BA_ "GenSigTimeoutTime_MPPxPTFE2" SG_ 2566906867 Bms0IChgCompl_FFE3F3 25000;
BA_ "GenSigTimeoutTime_IC_MulticII" SG_ 2566906867 Bms0IChgCompl_FFE3F3 25000;
BA_ "GenSigTimeoutTime_FMS_FMS4" SG_ 2566906867 Bms0IChgCompl_FFE3F3 25000;
BA_ "CI_SigName" SG_ 2566906867 Bms0IChgCompl_FFE3F3 "BMS0i Charge Completed";
BA_ "CI_SigId" SG_ 2566906867 Bms0IChgCompl_FFE3F3 10763;
BA_ "CI_ParId" SG_ 2566906867 Bms0IChgCompl_FFE3F3 "IB580";
BA_ "SigType" SG_ 2566906867 Bms0IOpSts_FFE3F3 4;
BA_ "GenSigTimeoutTime_SGW" SG_ 2566906867 Bms0IOpSts_FFE3F3 25000;
BA_ "GenSigTimeoutTime_PCM" SG_ 2566906867 Bms0IOpSts_FFE3F3 25000;
BA_ "GenSigTimeoutTime_MPPxPTFE2" SG_ 2566906867 Bms0IOpSts_FFE3F3 25000;
BA_ "GenSigTimeoutTime_IC_MulticII" SG_ 2566906867 Bms0IOpSts_FFE3F3 25000;
BA_ "GenSigTimeoutTime_FMS_FMS4" SG_ 2566906867 Bms0IOpSts_FFE3F3 25000;
BA_ "CI_SigName" SG_ 2566906867 Bms0IOpSts_FFE3F3 "BMS0i Operating Status";
BA_ "CI_SigId" SG_ 2566906867 Bms0IOpSts_FFE3F3 10762;
BA_ "CI_ParId" SG_ 2566906867 Bms0IOpSts_FFE3F3 "IB579";
BA_ "GenSigTimeoutTime_SGW" SG_ 2566906867 Bms0IActSts_FFE3F3 25000;
BA_ "GenSigTimeoutTime_PCM" SG_ 2566906867 Bms0IActSts_FFE3F3 25000;
BA_ "GenSigTimeoutTime_MPPxPTFE2" SG_ 2566906867 Bms0IActSts_FFE3F3 25000;
BA_ "GenSigTimeoutTime_IC_MulticII" SG_ 2566906867 Bms0IActSts_FFE3F3 25000;
BA_ "GenSigTimeoutTime_FMS_FMS4" SG_ 2566906867 Bms0IActSts_FFE3F3 25000;
BA_ "CI_SigName" SG_ 2566906867 Bms0IActSts_FFE3F3 "BMS0i Actual State";
BA_ "CI_SigId" SG_ 2566906867 Bms0IActSts_FFE3F3 10761;
BA_ "CI_ParId" SG_ 2566906867 Bms0IActSts_FFE3F3 "IB578";
BA_ "GenSigTimeoutTime_SGW" SG_ 2566906867 Bms0IEqualizationSts_FFE3F3 25000;
BA_ "GenSigTimeoutTime_PCM" SG_ 2566906867 Bms0IEqualizationSts_FFE3F3 25000;
BA_ "GenSigTimeoutTime_MPPxPTFE2" SG_ 2566906867 Bms0IEqualizationSts_FFE3F3 25000;
BA_ "GenSigTimeoutTime_IC_MulticII" SG_ 2566906867 Bms0IEqualizationSts_FFE3F3 25000;
BA_ "GenSigTimeoutTime_FMS_FMS4" SG_ 2566906867 Bms0IEqualizationSts_FFE3F3 25000;
BA_ "CI_SigName" SG_ 2566906867 Bms0IEqualizationSts_FFE3F3 "BMS0i Equalization Status";
BA_ "CI_SigId" SG_ 2566906867 Bms0IEqualizationSts_FFE3F3 10760;
BA_ "CI_ParId" SG_ 2566906867 Bms0IEqualizationSts_FFE3F3 "IB577";
BA_ "SigType" SG_ 2566906867 Bms0IMinCellV_FFE3F3 1;
BA_ "GenSigTimeoutTime_SGW" SG_ 2566906867 Bms0IMinCellV_FFE3F3 25000;
BA_ "GenSigTimeoutTime_PCM" SG_ 2566906867 Bms0IMinCellV_FFE3F3 25000;
BA_ "GenSigTimeoutTime_MPPxPTFE2" SG_ 2566906867 Bms0IMinCellV_FFE3F3 25000;
BA_ "GenSigTimeoutTime_IC_MulticII" SG_ 2566906867 Bms0IMinCellV_FFE3F3 25000;
BA_ "GenSigTimeoutTime_FMS_FMS4" SG_ 2566906867 Bms0IMinCellV_FFE3F3 25000;
BA_ "CI_SigName" SG_ 2566906867 Bms0IMinCellV_FFE3F3 "BMS0i Min Cell Voltage";
BA_ "CI_SigId" SG_ 2566906867 Bms0IMinCellV_FFE3F3 10759;
BA_ "CI_ParId" SG_ 2566906867 Bms0IMinCellV_FFE3F3 "IB576";
BA_ "SigType" SG_ 2566906867 Bms0IMaxCellV_FFE3F3 1;
BA_ "GenSigTimeoutTime_SGW" SG_ 2566906867 Bms0IMaxCellV_FFE3F3 25000;
BA_ "GenSigTimeoutTime_PCM" SG_ 2566906867 Bms0IMaxCellV_FFE3F3 25000;
BA_ "GenSigTimeoutTime_MPPxPTFE2" SG_ 2566906867 Bms0IMaxCellV_FFE3F3 25000;
BA_ "GenSigTimeoutTime_IC_MulticII" SG_ 2566906867 Bms0IMaxCellV_FFE3F3 25000;
BA_ "GenSigTimeoutTime_FMS_FMS4" SG_ 2566906867 Bms0IMaxCellV_FFE3F3 25000;
BA_ "CI_SigName" SG_ 2566906867 Bms0IMaxCellV_FFE3F3 "BMS0i Max Cell Voltage";
BA_ "CI_SigId" SG_ 2566906867 Bms0IMaxCellV_FFE3F3 10758;
BA_ "CI_ParId" SG_ 2566906867 Bms0IMaxCellV_FFE3F3 "IB575";
BA_ "SigType" SG_ 2566906867 Bms0IBatSoc_FFE3F3 1;
BA_ "GenSigTimeoutTime_SGW" SG_ 2566906867 Bms0IBatSoc_FFE3F3 25000;
BA_ "GenSigTimeoutTime_PCM" SG_ 2566906867 Bms0IBatSoc_FFE3F3 25000;
BA_ "GenSigTimeoutTime_MPPxPTFE2" SG_ 2566906867 Bms0IBatSoc_FFE3F3 25000;
BA_ "GenSigTimeoutTime_IC_MulticII" SG_ 2566906867 Bms0IBatSoc_FFE3F3 25000;
BA_ "GenSigTimeoutTime_FMS_FMS4" SG_ 2566906867 Bms0IBatSoc_FFE3F3 25000;
BA_ "CI_SigName" SG_ 2566906867 Bms0IBatSoc_FFE3F3 "BMS0i Battery SOC";
BA_ "CI_SigId" SG_ 2566906867 Bms0IBatSoc_FFE3F3 10757;
BA_ "CI_ParId" SG_ 2566906867 Bms0IBatSoc_FFE3F3 "IB574";
BA_ "SigType" SG_ 2566906867 Bms0IBatCur_FFE3F3 1;
BA_ "GenSigTimeoutTime_SGW" SG_ 2566906867 Bms0IBatCur_FFE3F3 25000;
BA_ "GenSigTimeoutTime_PCM" SG_ 2566906867 Bms0IBatCur_FFE3F3 25000;
BA_ "GenSigTimeoutTime_MPPxPTFE2" SG_ 2566906867 Bms0IBatCur_FFE3F3 25000;
BA_ "GenSigTimeoutTime_IC_MulticII" SG_ 2566906867 Bms0IBatCur_FFE3F3 25000;
BA_ "GenSigTimeoutTime_FMS_FMS4" SG_ 2566906867 Bms0IBatCur_FFE3F3 25000;
BA_ "GenSigStartValue" SG_ 2566906867 Bms0IBatCur_FFE3F3 125;
BA_ "CI_SigName" SG_ 2566906867 Bms0IBatCur_FFE3F3 "BMS0i Battery Current";
BA_ "CI_SigId" SG_ 2566906867 Bms0IBatCur_FFE3F3 10756;
BA_ "CI_ParId" SG_ 2566906867 Bms0IBatCur_FFE3F3 "IB573";
BA_ "SigType" SG_ 2566906867 Bms0IBatV_FFE3F3 1;
BA_ "GenSigTimeoutTime_SGW" SG_ 2566906867 Bms0IBatV_FFE3F3 25000;
BA_ "GenSigTimeoutTime_PCM" SG_ 2566906867 Bms0IBatV_FFE3F3 25000;
BA_ "GenSigTimeoutTime_MPPxPTFE2" SG_ 2566906867 Bms0IBatV_FFE3F3 25000;
BA_ "GenSigTimeoutTime_IC_MulticII" SG_ 2566906867 Bms0IBatV_FFE3F3 25000;
BA_ "GenSigTimeoutTime_FMS_FMS4" SG_ 2566906867 Bms0IBatV_FFE3F3 25000;
BA_ "CI_SigName" SG_ 2566906867 Bms0IBatV_FFE3F3 "BMS0i Battery Voltage";
BA_ "CI_SigId" SG_ 2566906867 Bms0IBatV_FFE3F3 10755;
BA_ "CI_ParId" SG_ 2566906867 Bms0IBatV_FFE3F3 "IB572";
BA_ "SigType" SG_ 2566907123 Bms0IMinCellTemp_FFE4F3 1;
BA_ "GenSigTimeoutTime_SGW" SG_ 2566907123 Bms0IMinCellTemp_FFE4F3 25000;
BA_ "GenSigTimeoutTime_PCM" SG_ 2566907123 Bms0IMinCellTemp_FFE4F3 25000;
BA_ "GenSigTimeoutTime_MPPxPTFE2" SG_ 2566907123 Bms0IMinCellTemp_FFE4F3 25000;
BA_ "GenSigTimeoutTime_IC_MulticII" SG_ 2566907123 Bms0IMinCellTemp_FFE4F3 25000;
BA_ "GenSigTimeoutTime_FMS_FMS4" SG_ 2566907123 Bms0IMinCellTemp_FFE4F3 25000;
BA_ "GenSigStartValue" SG_ 2566907123 Bms0IMinCellTemp_FFE4F3 40;
BA_ "CI_SigName" SG_ 2566907123 Bms0IMinCellTemp_FFE4F3 "BMS0i Min Cell Temperature";
BA_ "CI_SigId" SG_ 2566907123 Bms0IMinCellTemp_FFE4F3 10779;
BA_ "CI_ParId" SG_ 2566907123 Bms0IMinCellTemp_FFE4F3 "IB583";
BA_ "SigType" SG_ 2566907123 Bms0IMaxCellTemp_FFE4F3 1;
BA_ "GenSigTimeoutTime_SGW" SG_ 2566907123 Bms0IMaxCellTemp_FFE4F3 25000;
BA_ "GenSigTimeoutTime_PCM" SG_ 2566907123 Bms0IMaxCellTemp_FFE4F3 25000;
BA_ "GenSigTimeoutTime_MPPxPTFE2" SG_ 2566907123 Bms0IMaxCellTemp_FFE4F3 25000;
BA_ "GenSigTimeoutTime_IC_MulticII" SG_ 2566907123 Bms0IMaxCellTemp_FFE4F3 25000;
BA_ "GenSigTimeoutTime_FMS_FMS4" SG_ 2566907123 Bms0IMaxCellTemp_FFE4F3 25000;
BA_ "GenSigStartValue" SG_ 2566907123 Bms0IMaxCellTemp_FFE4F3 40;
BA_ "CI_SigName" SG_ 2566907123 Bms0IMaxCellTemp_FFE4F3 "BMS0i Max Cell Temperature";
BA_ "CI_SigId" SG_ 2566907123 Bms0IMaxCellTemp_FFE4F3 10778;
BA_ "CI_ParId" SG_ 2566907123 Bms0IMaxCellTemp_FFE4F3 "IB582";
BA_ "GenSigTimeoutTime_SGW" SG_ 2566907123 Bms0IPwrDistributed_FFE4F3 25000;
BA_ "GenSigTimeoutTime_PCM" SG_ 2566907123 Bms0IPwrDistributed_FFE4F3 25000;
BA_ "GenSigTimeoutTime_MPPxPTFE2" SG_ 2566907123 Bms0IPwrDistributed_FFE4F3 25000;
BA_ "GenSigTimeoutTime_IC_MulticII" SG_ 2566907123 Bms0IPwrDistributed_FFE4F3 25000;
BA_ "GenSigTimeoutTime_FMS_FMS4" SG_ 2566907123 Bms0IPwrDistributed_FFE4F3 25000;
BA_ "CI_SigName" SG_ 2566907123 Bms0IPwrDistributed_FFE4F3 "BMS0i Power Distributed";
BA_ "CI_SigId" SG_ 2566907123 Bms0IPwrDistributed_FFE4F3 10777;
BA_ "CI_ParId" SG_ 2566907123 Bms0IPwrDistributed_FFE4F3 "IB581";
BA_ "GenSigTimeoutTime_SGW" SG_ 2566907123 Bms0IChgCompl_FFE4F3 25000;
BA_ "GenSigTimeoutTime_PCM" SG_ 2566907123 Bms0IChgCompl_FFE4F3 25000;
BA_ "GenSigTimeoutTime_MPPxPTFE2" SG_ 2566907123 Bms0IChgCompl_FFE4F3 25000;
BA_ "GenSigTimeoutTime_IC_MulticII" SG_ 2566907123 Bms0IChgCompl_FFE4F3 25000;
BA_ "GenSigTimeoutTime_FMS_FMS4" SG_ 2566907123 Bms0IChgCompl_FFE4F3 25000;
BA_ "CI_SigName" SG_ 2566907123 Bms0IChgCompl_FFE4F3 "BMS0i Charge Completed";
BA_ "CI_SigId" SG_ 2566907123 Bms0IChgCompl_FFE4F3 10776;
BA_ "CI_ParId" SG_ 2566907123 Bms0IChgCompl_FFE4F3 "IB580";
BA_ "SigType" SG_ 2566907123 Bms0IOpSts_FFE4F3 4;
BA_ "GenSigTimeoutTime_SGW" SG_ 2566907123 Bms0IOpSts_FFE4F3 25000;
BA_ "GenSigTimeoutTime_PCM" SG_ 2566907123 Bms0IOpSts_FFE4F3 25000;
BA_ "GenSigTimeoutTime_MPPxPTFE2" SG_ 2566907123 Bms0IOpSts_FFE4F3 25000;
BA_ "GenSigTimeoutTime_IC_MulticII" SG_ 2566907123 Bms0IOpSts_FFE4F3 25000;
BA_ "GenSigTimeoutTime_FMS_FMS4" SG_ 2566907123 Bms0IOpSts_FFE4F3 25000;
BA_ "CI_SigName" SG_ 2566907123 Bms0IOpSts_FFE4F3 "BMS0i Operating Status";
BA_ "CI_SigId" SG_ 2566907123 Bms0IOpSts_FFE4F3 10775;
BA_ "CI_ParId" SG_ 2566907123 Bms0IOpSts_FFE4F3 "IB579";
BA_ "GenSigTimeoutTime_SGW" SG_ 2566907123 Bms0IActSts_FFE4F3 25000;
BA_ "GenSigTimeoutTime_PCM" SG_ 2566907123 Bms0IActSts_FFE4F3 25000;
BA_ "GenSigTimeoutTime_MPPxPTFE2" SG_ 2566907123 Bms0IActSts_FFE4F3 25000;
BA_ "GenSigTimeoutTime_IC_MulticII" SG_ 2566907123 Bms0IActSts_FFE4F3 25000;
BA_ "GenSigTimeoutTime_FMS_FMS4" SG_ 2566907123 Bms0IActSts_FFE4F3 25000;
BA_ "CI_SigName" SG_ 2566907123 Bms0IActSts_FFE4F3 "BMS0i Actual State";
BA_ "CI_SigId" SG_ 2566907123 Bms0IActSts_FFE4F3 10774;
BA_ "CI_ParId" SG_ 2566907123 Bms0IActSts_FFE4F3 "IB578";
BA_ "GenSigTimeoutTime_SGW" SG_ 2566907123 Bms0IEqualizationSts_FFE4F3 25000;
BA_ "GenSigTimeoutTime_PCM" SG_ 2566907123 Bms0IEqualizationSts_FFE4F3 25000;
BA_ "GenSigTimeoutTime_MPPxPTFE2" SG_ 2566907123 Bms0IEqualizationSts_FFE4F3 25000;
BA_ "GenSigTimeoutTime_IC_MulticII" SG_ 2566907123 Bms0IEqualizationSts_FFE4F3 25000;
BA_ "GenSigTimeoutTime_FMS_FMS4" SG_ 2566907123 Bms0IEqualizationSts_FFE4F3 25000;
BA_ "CI_SigName" SG_ 2566907123 Bms0IEqualizationSts_FFE4F3 "BMS0i Equalization Status";
BA_ "CI_SigId" SG_ 2566907123 Bms0IEqualizationSts_FFE4F3 10773;
BA_ "CI_ParId" SG_ 2566907123 Bms0IEqualizationSts_FFE4F3 "IB577";
BA_ "SigType" SG_ 2566907123 Bms0IMinCellV_FFE4F3 1;
BA_ "GenSigTimeoutTime_SGW" SG_ 2566907123 Bms0IMinCellV_FFE4F3 25000;
BA_ "GenSigTimeoutTime_PCM" SG_ 2566907123 Bms0IMinCellV_FFE4F3 25000;
BA_ "GenSigTimeoutTime_MPPxPTFE2" SG_ 2566907123 Bms0IMinCellV_FFE4F3 25000;
BA_ "GenSigTimeoutTime_IC_MulticII" SG_ 2566907123 Bms0IMinCellV_FFE4F3 25000;
BA_ "GenSigTimeoutTime_FMS_FMS4" SG_ 2566907123 Bms0IMinCellV_FFE4F3 25000;
BA_ "CI_SigName" SG_ 2566907123 Bms0IMinCellV_FFE4F3 "BMS0i Min Cell Voltage";
BA_ "CI_SigId" SG_ 2566907123 Bms0IMinCellV_FFE4F3 10772;
BA_ "CI_ParId" SG_ 2566907123 Bms0IMinCellV_FFE4F3 "IB576";
BA_ "SigType" SG_ 2566907123 Bms0IMaxCellV_FFE4F3 1;
BA_ "GenSigTimeoutTime_SGW" SG_ 2566907123 Bms0IMaxCellV_FFE4F3 25000;
BA_ "GenSigTimeoutTime_PCM" SG_ 2566907123 Bms0IMaxCellV_FFE4F3 25000;
BA_ "GenSigTimeoutTime_MPPxPTFE2" SG_ 2566907123 Bms0IMaxCellV_FFE4F3 25000;
BA_ "GenSigTimeoutTime_IC_MulticII" SG_ 2566907123 Bms0IMaxCellV_FFE4F3 25000;
BA_ "GenSigTimeoutTime_FMS_FMS4" SG_ 2566907123 Bms0IMaxCellV_FFE4F3 25000;
BA_ "CI_SigName" SG_ 2566907123 Bms0IMaxCellV_FFE4F3 "BMS0i Max Cell Voltage";
BA_ "CI_SigId" SG_ 2566907123 Bms0IMaxCellV_FFE4F3 10771;
BA_ "CI_ParId" SG_ 2566907123 Bms0IMaxCellV_FFE4F3 "IB575";
BA_ "SigType" SG_ 2566907123 Bms0IBatSoc_FFE4F3 1;
BA_ "GenSigTimeoutTime_SGW" SG_ 2566907123 Bms0IBatSoc_FFE4F3 25000;
BA_ "GenSigTimeoutTime_PCM" SG_ 2566907123 Bms0IBatSoc_FFE4F3 25000;
BA_ "GenSigTimeoutTime_MPPxPTFE2" SG_ 2566907123 Bms0IBatSoc_FFE4F3 25000;
BA_ "GenSigTimeoutTime_IC_MulticII" SG_ 2566907123 Bms0IBatSoc_FFE4F3 25000;
BA_ "GenSigTimeoutTime_FMS_FMS4" SG_ 2566907123 Bms0IBatSoc_FFE4F3 25000;
BA_ "CI_SigName" SG_ 2566907123 Bms0IBatSoc_FFE4F3 "BMS0i Battery SOC";
BA_ "CI_SigId" SG_ 2566907123 Bms0IBatSoc_FFE4F3 10770;
BA_ "CI_ParId" SG_ 2566907123 Bms0IBatSoc_FFE4F3 "IB574";
BA_ "SigType" SG_ 2566907123 Bms0IBatCur_FFE4F3 1;
BA_ "GenSigTimeoutTime_SGW" SG_ 2566907123 Bms0IBatCur_FFE4F3 25000;
BA_ "GenSigTimeoutTime_PCM" SG_ 2566907123 Bms0IBatCur_FFE4F3 25000;
BA_ "GenSigTimeoutTime_MPPxPTFE2" SG_ 2566907123 Bms0IBatCur_FFE4F3 25000;
BA_ "GenSigTimeoutTime_IC_MulticII" SG_ 2566907123 Bms0IBatCur_FFE4F3 25000;
BA_ "GenSigTimeoutTime_FMS_FMS4" SG_ 2566907123 Bms0IBatCur_FFE4F3 25000;
BA_ "GenSigStartValue" SG_ 2566907123 Bms0IBatCur_FFE4F3 125;
BA_ "CI_SigName" SG_ 2566907123 Bms0IBatCur_FFE4F3 "BMS0i Battery Current";
BA_ "CI_SigId" SG_ 2566907123 Bms0IBatCur_FFE4F3 10769;
BA_ "CI_ParId" SG_ 2566907123 Bms0IBatCur_FFE4F3 "IB573";
BA_ "SigType" SG_ 2566907123 Bms0IBatV_FFE4F3 1;
BA_ "GenSigTimeoutTime_SGW" SG_ 2566907123 Bms0IBatV_FFE4F3 25000;
BA_ "GenSigTimeoutTime_PCM" SG_ 2566907123 Bms0IBatV_FFE4F3 25000;
BA_ "GenSigTimeoutTime_MPPxPTFE2" SG_ 2566907123 Bms0IBatV_FFE4F3 25000;
BA_ "GenSigTimeoutTime_IC_MulticII" SG_ 2566907123 Bms0IBatV_FFE4F3 25000;
BA_ "GenSigTimeoutTime_FMS_FMS4" SG_ 2566907123 Bms0IBatV_FFE4F3 25000;
BA_ "CI_SigName" SG_ 2566907123 Bms0IBatV_FFE4F3 "BMS0i Battery Voltage";
BA_ "CI_SigId" SG_ 2566907123 Bms0IBatV_FFE4F3 10768;
BA_ "CI_ParId" SG_ 2566907123 Bms0IBatV_FFE4F3 "IB572";
BA_ "SigType" SG_ 2566907379 Bms0IMinCellTemp_FFE5F3 1;
BA_ "GenSigTimeoutTime_SGW" SG_ 2566907379 Bms0IMinCellTemp_FFE5F3 25000;
BA_ "GenSigTimeoutTime_PCM" SG_ 2566907379 Bms0IMinCellTemp_FFE5F3 25000;
BA_ "GenSigTimeoutTime_MPPxPTFE2" SG_ 2566907379 Bms0IMinCellTemp_FFE5F3 25000;
BA_ "GenSigTimeoutTime_IC_MulticII" SG_ 2566907379 Bms0IMinCellTemp_FFE5F3 25000;
BA_ "GenSigTimeoutTime_FMS_FMS4" SG_ 2566907379 Bms0IMinCellTemp_FFE5F3 25000;
BA_ "GenSigStartValue" SG_ 2566907379 Bms0IMinCellTemp_FFE5F3 40;
BA_ "CI_SigName" SG_ 2566907379 Bms0IMinCellTemp_FFE5F3 "BMS0i Min Cell Temperature";
BA_ "CI_SigId" SG_ 2566907379 Bms0IMinCellTemp_FFE5F3 10792;
BA_ "CI_ParId" SG_ 2566907379 Bms0IMinCellTemp_FFE5F3 "IB583";
BA_ "SigType" SG_ 2566907379 Bms0IMaxCellTemp_FFE5F3 1;
BA_ "GenSigTimeoutTime_SGW" SG_ 2566907379 Bms0IMaxCellTemp_FFE5F3 25000;
BA_ "GenSigTimeoutTime_PCM" SG_ 2566907379 Bms0IMaxCellTemp_FFE5F3 25000;
BA_ "GenSigTimeoutTime_MPPxPTFE2" SG_ 2566907379 Bms0IMaxCellTemp_FFE5F3 25000;
BA_ "GenSigTimeoutTime_IC_MulticII" SG_ 2566907379 Bms0IMaxCellTemp_FFE5F3 25000;
BA_ "GenSigTimeoutTime_FMS_FMS4" SG_ 2566907379 Bms0IMaxCellTemp_FFE5F3 25000;
BA_ "GenSigStartValue" SG_ 2566907379 Bms0IMaxCellTemp_FFE5F3 40;
BA_ "CI_SigName" SG_ 2566907379 Bms0IMaxCellTemp_FFE5F3 "BMS0i Max Cell Temperature";
BA_ "CI_SigId" SG_ 2566907379 Bms0IMaxCellTemp_FFE5F3 10791;
BA_ "CI_ParId" SG_ 2566907379 Bms0IMaxCellTemp_FFE5F3 "IB582";
BA_ "GenSigTimeoutTime_SGW" SG_ 2566907379 Bms0IPwrDistributed_FFE5F3 25000;
BA_ "GenSigTimeoutTime_PCM" SG_ 2566907379 Bms0IPwrDistributed_FFE5F3 25000;
BA_ "GenSigTimeoutTime_MPPxPTFE2" SG_ 2566907379 Bms0IPwrDistributed_FFE5F3 25000;
BA_ "GenSigTimeoutTime_IC_MulticII" SG_ 2566907379 Bms0IPwrDistributed_FFE5F3 25000;
BA_ "GenSigTimeoutTime_FMS_FMS4" SG_ 2566907379 Bms0IPwrDistributed_FFE5F3 25000;
BA_ "CI_SigName" SG_ 2566907379 Bms0IPwrDistributed_FFE5F3 "BMS0i Power Distributed";
BA_ "CI_SigId" SG_ 2566907379 Bms0IPwrDistributed_FFE5F3 10790;
BA_ "CI_ParId" SG_ 2566907379 Bms0IPwrDistributed_FFE5F3 "IB581";
BA_ "GenSigTimeoutTime_SGW" SG_ 2566907379 Bms0IChgCompl_FFE5F3 25000;
BA_ "GenSigTimeoutTime_PCM" SG_ 2566907379 Bms0IChgCompl_FFE5F3 25000;
BA_ "GenSigTimeoutTime_MPPxPTFE2" SG_ 2566907379 Bms0IChgCompl_FFE5F3 25000;
BA_ "GenSigTimeoutTime_IC_MulticII" SG_ 2566907379 Bms0IChgCompl_FFE5F3 25000;
BA_ "GenSigTimeoutTime_FMS_FMS4" SG_ 2566907379 Bms0IChgCompl_FFE5F3 25000;
BA_ "CI_SigName" SG_ 2566907379 Bms0IChgCompl_FFE5F3 "BMS0i Charge Completed";
BA_ "CI_SigId" SG_ 2566907379 Bms0IChgCompl_FFE5F3 10789;
BA_ "CI_ParId" SG_ 2566907379 Bms0IChgCompl_FFE5F3 "IB580";
BA_ "SigType" SG_ 2566907379 Bms0IOpSts_FFE5F3 4;
BA_ "GenSigTimeoutTime_SGW" SG_ 2566907379 Bms0IOpSts_FFE5F3 25000;
BA_ "GenSigTimeoutTime_PCM" SG_ 2566907379 Bms0IOpSts_FFE5F3 25000;
BA_ "GenSigTimeoutTime_MPPxPTFE2" SG_ 2566907379 Bms0IOpSts_FFE5F3 25000;
BA_ "GenSigTimeoutTime_IC_MulticII" SG_ 2566907379 Bms0IOpSts_FFE5F3 25000;
BA_ "GenSigTimeoutTime_FMS_FMS4" SG_ 2566907379 Bms0IOpSts_FFE5F3 25000;
BA_ "CI_SigName" SG_ 2566907379 Bms0IOpSts_FFE5F3 "BMS0i Operating Status";
BA_ "CI_SigId" SG_ 2566907379 Bms0IOpSts_FFE5F3 10788;
BA_ "CI_ParId" SG_ 2566907379 Bms0IOpSts_FFE5F3 "IB579";
BA_ "GenSigTimeoutTime_SGW" SG_ 2566907379 Bms0IActSts_FFE5F3 25000;
BA_ "GenSigTimeoutTime_PCM" SG_ 2566907379 Bms0IActSts_FFE5F3 25000;
BA_ "GenSigTimeoutTime_MPPxPTFE2" SG_ 2566907379 Bms0IActSts_FFE5F3 25000;
BA_ "GenSigTimeoutTime_IC_MulticII" SG_ 2566907379 Bms0IActSts_FFE5F3 25000;
BA_ "GenSigTimeoutTime_FMS_FMS4" SG_ 2566907379 Bms0IActSts_FFE5F3 25000;
BA_ "CI_SigName" SG_ 2566907379 Bms0IActSts_FFE5F3 "BMS0i Actual State";
BA_ "CI_SigId" SG_ 2566907379 Bms0IActSts_FFE5F3 10787;
BA_ "CI_ParId" SG_ 2566907379 Bms0IActSts_FFE5F3 "IB578";
BA_ "GenSigTimeoutTime_SGW" SG_ 2566907379 Bms0IEqualizationSts_FFE5F3 25000;
BA_ "GenSigTimeoutTime_PCM" SG_ 2566907379 Bms0IEqualizationSts_FFE5F3 25000;
BA_ "GenSigTimeoutTime_MPPxPTFE2" SG_ 2566907379 Bms0IEqualizationSts_FFE5F3 25000;
BA_ "GenSigTimeoutTime_IC_MulticII" SG_ 2566907379 Bms0IEqualizationSts_FFE5F3 25000;
BA_ "GenSigTimeoutTime_FMS_FMS4" SG_ 2566907379 Bms0IEqualizationSts_FFE5F3 25000;
BA_ "CI_SigName" SG_ 2566907379 Bms0IEqualizationSts_FFE5F3 "BMS0i Equalization Status";
BA_ "CI_SigId" SG_ 2566907379 Bms0IEqualizationSts_FFE5F3 10786;
BA_ "CI_ParId" SG_ 2566907379 Bms0IEqualizationSts_FFE5F3 "IB577";
BA_ "SigType" SG_ 2566907379 Bms0IMinCellV_FFE5F3 1;
BA_ "GenSigTimeoutTime_SGW" SG_ 2566907379 Bms0IMinCellV_FFE5F3 25000;
BA_ "GenSigTimeoutTime_PCM" SG_ 2566907379 Bms0IMinCellV_FFE5F3 25000;
BA_ "GenSigTimeoutTime_MPPxPTFE2" SG_ 2566907379 Bms0IMinCellV_FFE5F3 25000;
BA_ "GenSigTimeoutTime_IC_MulticII" SG_ 2566907379 Bms0IMinCellV_FFE5F3 25000;
BA_ "GenSigTimeoutTime_FMS_FMS4" SG_ 2566907379 Bms0IMinCellV_FFE5F3 25000;
BA_ "CI_SigName" SG_ 2566907379 Bms0IMinCellV_FFE5F3 "BMS0i Min Cell Voltage";
BA_ "CI_SigId" SG_ 2566907379 Bms0IMinCellV_FFE5F3 10785;
BA_ "CI_ParId" SG_ 2566907379 Bms0IMinCellV_FFE5F3 "IB576";
BA_ "SigType" SG_ 2566907379 Bms0IMaxCellV_FFE5F3 1;
BA_ "GenSigTimeoutTime_SGW" SG_ 2566907379 Bms0IMaxCellV_FFE5F3 25000;
BA_ "GenSigTimeoutTime_PCM" SG_ 2566907379 Bms0IMaxCellV_FFE5F3 25000;
BA_ "GenSigTimeoutTime_MPPxPTFE2" SG_ 2566907379 Bms0IMaxCellV_FFE5F3 25000;
BA_ "GenSigTimeoutTime_IC_MulticII" SG_ 2566907379 Bms0IMaxCellV_FFE5F3 25000;
BA_ "GenSigTimeoutTime_FMS_FMS4" SG_ 2566907379 Bms0IMaxCellV_FFE5F3 25000;
BA_ "CI_SigName" SG_ 2566907379 Bms0IMaxCellV_FFE5F3 "BMS0i Max Cell Voltage";
BA_ "CI_SigId" SG_ 2566907379 Bms0IMaxCellV_FFE5F3 10784;
BA_ "CI_ParId" SG_ 2566907379 Bms0IMaxCellV_FFE5F3 "IB575";
BA_ "SigType" SG_ 2566907379 Bms0IBatSoc_FFE5F3 1;
BA_ "GenSigTimeoutTime_SGW" SG_ 2566907379 Bms0IBatSoc_FFE5F3 25000;
BA_ "GenSigTimeoutTime_PCM" SG_ 2566907379 Bms0IBatSoc_FFE5F3 25000;
BA_ "GenSigTimeoutTime_MPPxPTFE2" SG_ 2566907379 Bms0IBatSoc_FFE5F3 25000;
BA_ "GenSigTimeoutTime_IC_MulticII" SG_ 2566907379 Bms0IBatSoc_FFE5F3 25000;
BA_ "GenSigTimeoutTime_FMS_FMS4" SG_ 2566907379 Bms0IBatSoc_FFE5F3 25000;
BA_ "CI_SigName" SG_ 2566907379 Bms0IBatSoc_FFE5F3 "BMS0i Battery SOC";
BA_ "CI_SigId" SG_ 2566907379 Bms0IBatSoc_FFE5F3 10783;
BA_ "CI_ParId" SG_ 2566907379 Bms0IBatSoc_FFE5F3 "IB574";
BA_ "SigType" SG_ 2566907379 Bms0IBatCur_FFE5F3 1;
BA_ "GenSigTimeoutTime_SGW" SG_ 2566907379 Bms0IBatCur_FFE5F3 25000;
BA_ "GenSigTimeoutTime_PCM" SG_ 2566907379 Bms0IBatCur_FFE5F3 25000;
BA_ "GenSigTimeoutTime_MPPxPTFE2" SG_ 2566907379 Bms0IBatCur_FFE5F3 25000;
BA_ "GenSigTimeoutTime_IC_MulticII" SG_ 2566907379 Bms0IBatCur_FFE5F3 25000;
BA_ "GenSigTimeoutTime_FMS_FMS4" SG_ 2566907379 Bms0IBatCur_FFE5F3 25000;
BA_ "GenSigStartValue" SG_ 2566907379 Bms0IBatCur_FFE5F3 125;
BA_ "CI_SigName" SG_ 2566907379 Bms0IBatCur_FFE5F3 "BMS0i Battery Current";
BA_ "CI_SigId" SG_ 2566907379 Bms0IBatCur_FFE5F3 10782;
BA_ "CI_ParId" SG_ 2566907379 Bms0IBatCur_FFE5F3 "IB573";
BA_ "SigType" SG_ 2566907379 Bms0IBatV_FFE5F3 1;
BA_ "GenSigTimeoutTime_SGW" SG_ 2566907379 Bms0IBatV_FFE5F3 25000;
BA_ "GenSigTimeoutTime_PCM" SG_ 2566907379 Bms0IBatV_FFE5F3 25000;
BA_ "GenSigTimeoutTime_MPPxPTFE2" SG_ 2566907379 Bms0IBatV_FFE5F3 25000;
BA_ "GenSigTimeoutTime_IC_MulticII" SG_ 2566907379 Bms0IBatV_FFE5F3 25000;
BA_ "GenSigTimeoutTime_FMS_FMS4" SG_ 2566907379 Bms0IBatV_FFE5F3 25000;
BA_ "CI_SigName" SG_ 2566907379 Bms0IBatV_FFE5F3 "BMS0i Battery Voltage";
BA_ "CI_SigId" SG_ 2566907379 Bms0IBatV_FFE5F3 10781;
BA_ "CI_ParId" SG_ 2566907379 Bms0IBatV_FFE5F3 "IB572";
BA_ "SigType" SG_ 2566907635 Bms0IMinCellTemp_FFE6F3 1;
BA_ "GenSigTimeoutTime_SGW" SG_ 2566907635 Bms0IMinCellTemp_FFE6F3 25000;
BA_ "GenSigTimeoutTime_PCM" SG_ 2566907635 Bms0IMinCellTemp_FFE6F3 25000;
BA_ "GenSigTimeoutTime_MPPxPTFE2" SG_ 2566907635 Bms0IMinCellTemp_FFE6F3 25000;
BA_ "GenSigTimeoutTime_IC_MulticII" SG_ 2566907635 Bms0IMinCellTemp_FFE6F3 25000;
BA_ "GenSigTimeoutTime_FMS_FMS4" SG_ 2566907635 Bms0IMinCellTemp_FFE6F3 25000;
BA_ "GenSigStartValue" SG_ 2566907635 Bms0IMinCellTemp_FFE6F3 40;
BA_ "CI_SigName" SG_ 2566907635 Bms0IMinCellTemp_FFE6F3 "BMS0i Min Cell Temperature";
BA_ "CI_SigId" SG_ 2566907635 Bms0IMinCellTemp_FFE6F3 10805;
BA_ "CI_ParId" SG_ 2566907635 Bms0IMinCellTemp_FFE6F3 "IB583";
BA_ "SigType" SG_ 2566907635 Bms0IMaxCellTemp_FFE6F3 1;
BA_ "GenSigTimeoutTime_SGW" SG_ 2566907635 Bms0IMaxCellTemp_FFE6F3 25000;
BA_ "GenSigTimeoutTime_PCM" SG_ 2566907635 Bms0IMaxCellTemp_FFE6F3 25000;
BA_ "GenSigTimeoutTime_MPPxPTFE2" SG_ 2566907635 Bms0IMaxCellTemp_FFE6F3 25000;
BA_ "GenSigTimeoutTime_IC_MulticII" SG_ 2566907635 Bms0IMaxCellTemp_FFE6F3 25000;
BA_ "GenSigTimeoutTime_FMS_FMS4" SG_ 2566907635 Bms0IMaxCellTemp_FFE6F3 25000;
BA_ "GenSigStartValue" SG_ 2566907635 Bms0IMaxCellTemp_FFE6F3 40;
BA_ "CI_SigName" SG_ 2566907635 Bms0IMaxCellTemp_FFE6F3 "BMS0i Max Cell Temperature";
BA_ "CI_SigId" SG_ 2566907635 Bms0IMaxCellTemp_FFE6F3 10804;
BA_ "CI_ParId" SG_ 2566907635 Bms0IMaxCellTemp_FFE6F3 "IB582";
BA_ "GenSigTimeoutTime_SGW" SG_ 2566907635 Bms0IPwrDistributed_FFE6F3 25000;
BA_ "GenSigTimeoutTime_PCM" SG_ 2566907635 Bms0IPwrDistributed_FFE6F3 25000;
BA_ "GenSigTimeoutTime_MPPxPTFE2" SG_ 2566907635 Bms0IPwrDistributed_FFE6F3 25000;
BA_ "GenSigTimeoutTime_IC_MulticII" SG_ 2566907635 Bms0IPwrDistributed_FFE6F3 25000;
BA_ "GenSigTimeoutTime_FMS_FMS4" SG_ 2566907635 Bms0IPwrDistributed_FFE6F3 25000;
BA_ "CI_SigName" SG_ 2566907635 Bms0IPwrDistributed_FFE6F3 "BMS0i Power Distributed";
BA_ "CI_SigId" SG_ 2566907635 Bms0IPwrDistributed_FFE6F3 10803;
BA_ "CI_ParId" SG_ 2566907635 Bms0IPwrDistributed_FFE6F3 "IB581";
BA_ "GenSigTimeoutTime_SGW" SG_ 2566907635 Bms0IChgCompl_FFE6F3 25000;
BA_ "GenSigTimeoutTime_PCM" SG_ 2566907635 Bms0IChgCompl_FFE6F3 25000;
BA_ "GenSigTimeoutTime_MPPxPTFE2" SG_ 2566907635 Bms0IChgCompl_FFE6F3 25000;
BA_ "GenSigTimeoutTime_IC_MulticII" SG_ 2566907635 Bms0IChgCompl_FFE6F3 25000;
BA_ "GenSigTimeoutTime_FMS_FMS4" SG_ 2566907635 Bms0IChgCompl_FFE6F3 25000;
BA_ "CI_SigName" SG_ 2566907635 Bms0IChgCompl_FFE6F3 "BMS0i Charge Completed";
BA_ "CI_SigId" SG_ 2566907635 Bms0IChgCompl_FFE6F3 10802;
BA_ "CI_ParId" SG_ 2566907635 Bms0IChgCompl_FFE6F3 "IB580";
BA_ "SigType" SG_ 2566907635 Bms0IOpSts_FFE6F3 4;
BA_ "GenSigTimeoutTime_SGW" SG_ 2566907635 Bms0IOpSts_FFE6F3 25000;
BA_ "GenSigTimeoutTime_PCM" SG_ 2566907635 Bms0IOpSts_FFE6F3 25000;
BA_ "GenSigTimeoutTime_MPPxPTFE2" SG_ 2566907635 Bms0IOpSts_FFE6F3 25000;
BA_ "GenSigTimeoutTime_IC_MulticII" SG_ 2566907635 Bms0IOpSts_FFE6F3 25000;
BA_ "GenSigTimeoutTime_FMS_FMS4" SG_ 2566907635 Bms0IOpSts_FFE6F3 25000;
BA_ "CI_SigName" SG_ 2566907635 Bms0IOpSts_FFE6F3 "BMS0i Operating Status";
BA_ "CI_SigId" SG_ 2566907635 Bms0IOpSts_FFE6F3 10801;
BA_ "CI_ParId" SG_ 2566907635 Bms0IOpSts_FFE6F3 "IB579";
BA_ "GenSigTimeoutTime_SGW" SG_ 2566907635 Bms0IActSts_FFE6F3 25000;
BA_ "GenSigTimeoutTime_PCM" SG_ 2566907635 Bms0IActSts_FFE6F3 25000;
BA_ "GenSigTimeoutTime_MPPxPTFE2" SG_ 2566907635 Bms0IActSts_FFE6F3 25000;
BA_ "GenSigTimeoutTime_IC_MulticII" SG_ 2566907635 Bms0IActSts_FFE6F3 25000;
BA_ "GenSigTimeoutTime_FMS_FMS4" SG_ 2566907635 Bms0IActSts_FFE6F3 25000;
BA_ "CI_SigName" SG_ 2566907635 Bms0IActSts_FFE6F3 "BMS0i Actual State";
BA_ "CI_SigId" SG_ 2566907635 Bms0IActSts_FFE6F3 10800;
BA_ "CI_ParId" SG_ 2566907635 Bms0IActSts_FFE6F3 "IB578";
BA_ "GenSigTimeoutTime_SGW" SG_ 2566907635 Bms0IEqualizationSts_FFE6F3 25000;
BA_ "GenSigTimeoutTime_PCM" SG_ 2566907635 Bms0IEqualizationSts_FFE6F3 25000;
BA_ "GenSigTimeoutTime_MPPxPTFE2" SG_ 2566907635 Bms0IEqualizationSts_FFE6F3 25000;
BA_ "GenSigTimeoutTime_IC_MulticII" SG_ 2566907635 Bms0IEqualizationSts_FFE6F3 25000;
BA_ "GenSigTimeoutTime_FMS_FMS4" SG_ 2566907635 Bms0IEqualizationSts_FFE6F3 25000;
BA_ "CI_SigName" SG_ 2566907635 Bms0IEqualizationSts_FFE6F3 "BMS0i Equalization Status";
BA_ "CI_SigId" SG_ 2566907635 Bms0IEqualizationSts_FFE6F3 10799;
BA_ "CI_ParId" SG_ 2566907635 Bms0IEqualizationSts_FFE6F3 "IB577";
BA_ "SigType" SG_ 2566907635 Bms0IMinCellV_FFE6F3 1;
BA_ "GenSigTimeoutTime_SGW" SG_ 2566907635 Bms0IMinCellV_FFE6F3 25000;
BA_ "GenSigTimeoutTime_PCM" SG_ 2566907635 Bms0IMinCellV_FFE6F3 25000;
BA_ "GenSigTimeoutTime_MPPxPTFE2" SG_ 2566907635 Bms0IMinCellV_FFE6F3 25000;
BA_ "GenSigTimeoutTime_IC_MulticII" SG_ 2566907635 Bms0IMinCellV_FFE6F3 25000;
BA_ "GenSigTimeoutTime_FMS_FMS4" SG_ 2566907635 Bms0IMinCellV_FFE6F3 25000;
BA_ "CI_SigName" SG_ 2566907635 Bms0IMinCellV_FFE6F3 "BMS0i Min Cell Voltage";
BA_ "CI_SigId" SG_ 2566907635 Bms0IMinCellV_FFE6F3 10798;
BA_ "CI_ParId" SG_ 2566907635 Bms0IMinCellV_FFE6F3 "IB576";
BA_ "SigType" SG_ 2566907635 Bms0IMaxCellV_FFE6F3 1;
BA_ "GenSigTimeoutTime_SGW" SG_ 2566907635 Bms0IMaxCellV_FFE6F3 25000;
BA_ "GenSigTimeoutTime_PCM" SG_ 2566907635 Bms0IMaxCellV_FFE6F3 25000;
BA_ "GenSigTimeoutTime_MPPxPTFE2" SG_ 2566907635 Bms0IMaxCellV_FFE6F3 25000;
BA_ "GenSigTimeoutTime_IC_MulticII" SG_ 2566907635 Bms0IMaxCellV_FFE6F3 25000;
BA_ "GenSigTimeoutTime_FMS_FMS4" SG_ 2566907635 Bms0IMaxCellV_FFE6F3 25000;
BA_ "CI_SigName" SG_ 2566907635 Bms0IMaxCellV_FFE6F3 "BMS0i Max Cell Voltage";
BA_ "CI_SigId" SG_ 2566907635 Bms0IMaxCellV_FFE6F3 10797;
BA_ "CI_ParId" SG_ 2566907635 Bms0IMaxCellV_FFE6F3 "IB575";
BA_ "SigType" SG_ 2566907635 Bms0IBatSoc_FFE6F3 1;
BA_ "GenSigTimeoutTime_SGW" SG_ 2566907635 Bms0IBatSoc_FFE6F3 25000;
BA_ "GenSigTimeoutTime_PCM" SG_ 2566907635 Bms0IBatSoc_FFE6F3 25000;
BA_ "GenSigTimeoutTime_MPPxPTFE2" SG_ 2566907635 Bms0IBatSoc_FFE6F3 25000;
BA_ "GenSigTimeoutTime_IC_MulticII" SG_ 2566907635 Bms0IBatSoc_FFE6F3 25000;
BA_ "GenSigTimeoutTime_FMS_FMS4" SG_ 2566907635 Bms0IBatSoc_FFE6F3 25000;
BA_ "CI_SigName" SG_ 2566907635 Bms0IBatSoc_FFE6F3 "BMS0i Battery SOC";
BA_ "CI_SigId" SG_ 2566907635 Bms0IBatSoc_FFE6F3 10796;
BA_ "CI_ParId" SG_ 2566907635 Bms0IBatSoc_FFE6F3 "IB574";
BA_ "SigType" SG_ 2566907635 Bms0IBatCur_FFE6F3 1;
BA_ "GenSigTimeoutTime_SGW" SG_ 2566907635 Bms0IBatCur_FFE6F3 25000;
BA_ "GenSigTimeoutTime_PCM" SG_ 2566907635 Bms0IBatCur_FFE6F3 25000;
BA_ "GenSigTimeoutTime_MPPxPTFE2" SG_ 2566907635 Bms0IBatCur_FFE6F3 25000;
BA_ "GenSigTimeoutTime_IC_MulticII" SG_ 2566907635 Bms0IBatCur_FFE6F3 25000;
BA_ "GenSigTimeoutTime_FMS_FMS4" SG_ 2566907635 Bms0IBatCur_FFE6F3 25000;
BA_ "GenSigStartValue" SG_ 2566907635 Bms0IBatCur_FFE6F3 125;
BA_ "CI_SigName" SG_ 2566907635 Bms0IBatCur_FFE6F3 "BMS0i Battery Current";
BA_ "CI_SigId" SG_ 2566907635 Bms0IBatCur_FFE6F3 10795;
BA_ "CI_ParId" SG_ 2566907635 Bms0IBatCur_FFE6F3 "IB573";
BA_ "SigType" SG_ 2566907635 Bms0IBatV_FFE6F3 1;
BA_ "GenSigTimeoutTime_SGW" SG_ 2566907635 Bms0IBatV_FFE6F3 25000;
BA_ "GenSigTimeoutTime_PCM" SG_ 2566907635 Bms0IBatV_FFE6F3 25000;
BA_ "GenSigTimeoutTime_MPPxPTFE2" SG_ 2566907635 Bms0IBatV_FFE6F3 25000;
BA_ "GenSigTimeoutTime_IC_MulticII" SG_ 2566907635 Bms0IBatV_FFE6F3 25000;
BA_ "GenSigTimeoutTime_FMS_FMS4" SG_ 2566907635 Bms0IBatV_FFE6F3 25000;
BA_ "CI_SigName" SG_ 2566907635 Bms0IBatV_FFE6F3 "BMS0i Battery Voltage";
BA_ "CI_SigId" SG_ 2566907635 Bms0IBatV_FFE6F3 10794;
BA_ "CI_ParId" SG_ 2566907635 Bms0IBatV_FFE6F3 "IB572";
BA_ "SigType" SG_ 2566907891 Bms0IMinCellTemp_FFE7F3 1;
BA_ "GenSigTimeoutTime_SGW" SG_ 2566907891 Bms0IMinCellTemp_FFE7F3 25000;
BA_ "GenSigTimeoutTime_PCM" SG_ 2566907891 Bms0IMinCellTemp_FFE7F3 25000;
BA_ "GenSigTimeoutTime_MPPxPTFE2" SG_ 2566907891 Bms0IMinCellTemp_FFE7F3 25000;
BA_ "GenSigTimeoutTime_IC_MulticII" SG_ 2566907891 Bms0IMinCellTemp_FFE7F3 25000;
BA_ "GenSigTimeoutTime_FMS_FMS4" SG_ 2566907891 Bms0IMinCellTemp_FFE7F3 25000;
BA_ "GenSigStartValue" SG_ 2566907891 Bms0IMinCellTemp_FFE7F3 40;
BA_ "CI_SigName" SG_ 2566907891 Bms0IMinCellTemp_FFE7F3 "BMS0i Min Cell Temperature";
BA_ "CI_SigId" SG_ 2566907891 Bms0IMinCellTemp_FFE7F3 10818;
BA_ "CI_ParId" SG_ 2566907891 Bms0IMinCellTemp_FFE7F3 "IB583";
BA_ "SigType" SG_ 2566907891 Bms0IMaxCellTemp_FFE7F3 1;
BA_ "GenSigTimeoutTime_SGW" SG_ 2566907891 Bms0IMaxCellTemp_FFE7F3 25000;
BA_ "GenSigTimeoutTime_PCM" SG_ 2566907891 Bms0IMaxCellTemp_FFE7F3 25000;
BA_ "GenSigTimeoutTime_MPPxPTFE2" SG_ 2566907891 Bms0IMaxCellTemp_FFE7F3 25000;
BA_ "GenSigTimeoutTime_IC_MulticII" SG_ 2566907891 Bms0IMaxCellTemp_FFE7F3 25000;
BA_ "GenSigTimeoutTime_FMS_FMS4" SG_ 2566907891 Bms0IMaxCellTemp_FFE7F3 25000;
BA_ "GenSigStartValue" SG_ 2566907891 Bms0IMaxCellTemp_FFE7F3 40;
BA_ "CI_SigName" SG_ 2566907891 Bms0IMaxCellTemp_FFE7F3 "BMS0i Max Cell Temperature";
BA_ "CI_SigId" SG_ 2566907891 Bms0IMaxCellTemp_FFE7F3 10817;
BA_ "CI_ParId" SG_ 2566907891 Bms0IMaxCellTemp_FFE7F3 "IB582";
BA_ "GenSigTimeoutTime_SGW" SG_ 2566907891 Bms0IPwrDistributed_FFE7F3 25000;
BA_ "GenSigTimeoutTime_PCM" SG_ 2566907891 Bms0IPwrDistributed_FFE7F3 25000;
BA_ "GenSigTimeoutTime_MPPxPTFE2" SG_ 2566907891 Bms0IPwrDistributed_FFE7F3 25000;
BA_ "GenSigTimeoutTime_IC_MulticII" SG_ 2566907891 Bms0IPwrDistributed_FFE7F3 25000;
BA_ "GenSigTimeoutTime_FMS_FMS4" SG_ 2566907891 Bms0IPwrDistributed_FFE7F3 25000;
BA_ "CI_SigName" SG_ 2566907891 Bms0IPwrDistributed_FFE7F3 "BMS0i Power Distributed";
BA_ "CI_SigId" SG_ 2566907891 Bms0IPwrDistributed_FFE7F3 10816;
BA_ "CI_ParId" SG_ 2566907891 Bms0IPwrDistributed_FFE7F3 "IB581";
BA_ "GenSigTimeoutTime_SGW" SG_ 2566907891 Bms0IChgCompl_FFE7F3 25000;
BA_ "GenSigTimeoutTime_PCM" SG_ 2566907891 Bms0IChgCompl_FFE7F3 25000;
BA_ "GenSigTimeoutTime_MPPxPTFE2" SG_ 2566907891 Bms0IChgCompl_FFE7F3 25000;
BA_ "GenSigTimeoutTime_IC_MulticII" SG_ 2566907891 Bms0IChgCompl_FFE7F3 25000;
BA_ "GenSigTimeoutTime_FMS_FMS4" SG_ 2566907891 Bms0IChgCompl_FFE7F3 25000;
BA_ "CI_SigName" SG_ 2566907891 Bms0IChgCompl_FFE7F3 "BMS0i Charge Completed";
BA_ "CI_SigId" SG_ 2566907891 Bms0IChgCompl_FFE7F3 10815;
BA_ "CI_ParId" SG_ 2566907891 Bms0IChgCompl_FFE7F3 "IB580";
BA_ "SigType" SG_ 2566907891 Bms0IOpSts_FFE7F3 4;
BA_ "GenSigTimeoutTime_SGW" SG_ 2566907891 Bms0IOpSts_FFE7F3 25000;
BA_ "GenSigTimeoutTime_PCM" SG_ 2566907891 Bms0IOpSts_FFE7F3 25000;
BA_ "GenSigTimeoutTime_MPPxPTFE2" SG_ 2566907891 Bms0IOpSts_FFE7F3 25000;
BA_ "GenSigTimeoutTime_IC_MulticII" SG_ 2566907891 Bms0IOpSts_FFE7F3 25000;
BA_ "GenSigTimeoutTime_FMS_FMS4" SG_ 2566907891 Bms0IOpSts_FFE7F3 25000;
BA_ "CI_SigName" SG_ 2566907891 Bms0IOpSts_FFE7F3 "BMS0i Operating Status";
BA_ "CI_SigId" SG_ 2566907891 Bms0IOpSts_FFE7F3 10814;
BA_ "CI_ParId" SG_ 2566907891 Bms0IOpSts_FFE7F3 "IB579";
BA_ "GenSigTimeoutTime_SGW" SG_ 2566907891 Bms0IActSts_FFE7F3 25000;
BA_ "GenSigTimeoutTime_PCM" SG_ 2566907891 Bms0IActSts_FFE7F3 25000;
BA_ "GenSigTimeoutTime_MPPxPTFE2" SG_ 2566907891 Bms0IActSts_FFE7F3 25000;
BA_ "GenSigTimeoutTime_IC_MulticII" SG_ 2566907891 Bms0IActSts_FFE7F3 25000;
BA_ "GenSigTimeoutTime_FMS_FMS4" SG_ 2566907891 Bms0IActSts_FFE7F3 25000;
BA_ "CI_SigName" SG_ 2566907891 Bms0IActSts_FFE7F3 "BMS0i Actual State";
BA_ "CI_SigId" SG_ 2566907891 Bms0IActSts_FFE7F3 10813;
BA_ "CI_ParId" SG_ 2566907891 Bms0IActSts_FFE7F3 "IB578";
BA_ "GenSigTimeoutTime_SGW" SG_ 2566907891 Bms0IEqualizationSts_FFE7F3 25000;
BA_ "GenSigTimeoutTime_PCM" SG_ 2566907891 Bms0IEqualizationSts_FFE7F3 25000;
BA_ "GenSigTimeoutTime_MPPxPTFE2" SG_ 2566907891 Bms0IEqualizationSts_FFE7F3 25000;
BA_ "GenSigTimeoutTime_IC_MulticII" SG_ 2566907891 Bms0IEqualizationSts_FFE7F3 25000;
BA_ "GenSigTimeoutTime_FMS_FMS4" SG_ 2566907891 Bms0IEqualizationSts_FFE7F3 25000;
BA_ "CI_SigName" SG_ 2566907891 Bms0IEqualizationSts_FFE7F3 "BMS0i Equalization Status";
BA_ "CI_SigId" SG_ 2566907891 Bms0IEqualizationSts_FFE7F3 10812;
BA_ "CI_ParId" SG_ 2566907891 Bms0IEqualizationSts_FFE7F3 "IB577";
BA_ "SigType" SG_ 2566907891 Bms0IMinCellV_FFE7F3 1;
BA_ "GenSigTimeoutTime_SGW" SG_ 2566907891 Bms0IMinCellV_FFE7F3 25000;
BA_ "GenSigTimeoutTime_PCM" SG_ 2566907891 Bms0IMinCellV_FFE7F3 25000;
BA_ "GenSigTimeoutTime_MPPxPTFE2" SG_ 2566907891 Bms0IMinCellV_FFE7F3 25000;
BA_ "GenSigTimeoutTime_IC_MulticII" SG_ 2566907891 Bms0IMinCellV_FFE7F3 25000;
BA_ "GenSigTimeoutTime_FMS_FMS4" SG_ 2566907891 Bms0IMinCellV_FFE7F3 25000;
BA_ "CI_SigName" SG_ 2566907891 Bms0IMinCellV_FFE7F3 "BMS0i Min Cell Voltage";
BA_ "CI_SigId" SG_ 2566907891 Bms0IMinCellV_FFE7F3 10811;
BA_ "CI_ParId" SG_ 2566907891 Bms0IMinCellV_FFE7F3 "IB576";
BA_ "SigType" SG_ 2566907891 Bms0IMaxCellV_FFE7F3 1;
BA_ "GenSigTimeoutTime_SGW" SG_ 2566907891 Bms0IMaxCellV_FFE7F3 25000;
BA_ "GenSigTimeoutTime_PCM" SG_ 2566907891 Bms0IMaxCellV_FFE7F3 25000;
BA_ "GenSigTimeoutTime_MPPxPTFE2" SG_ 2566907891 Bms0IMaxCellV_FFE7F3 25000;
BA_ "GenSigTimeoutTime_IC_MulticII" SG_ 2566907891 Bms0IMaxCellV_FFE7F3 25000;
BA_ "GenSigTimeoutTime_FMS_FMS4" SG_ 2566907891 Bms0IMaxCellV_FFE7F3 25000;
BA_ "CI_SigName" SG_ 2566907891 Bms0IMaxCellV_FFE7F3 "BMS0i Max Cell Voltage";
BA_ "CI_SigId" SG_ 2566907891 Bms0IMaxCellV_FFE7F3 10810;
BA_ "CI_ParId" SG_ 2566907891 Bms0IMaxCellV_FFE7F3 "IB575";
BA_ "SigType" SG_ 2566907891 Bms0IBatSoc_FFE7F3 1;
BA_ "GenSigTimeoutTime_SGW" SG_ 2566907891 Bms0IBatSoc_FFE7F3 25000;
BA_ "GenSigTimeoutTime_PCM" SG_ 2566907891 Bms0IBatSoc_FFE7F3 25000;
BA_ "GenSigTimeoutTime_MPPxPTFE2" SG_ 2566907891 Bms0IBatSoc_FFE7F3 25000;
BA_ "GenSigTimeoutTime_IC_MulticII" SG_ 2566907891 Bms0IBatSoc_FFE7F3 25000;
BA_ "GenSigTimeoutTime_FMS_FMS4" SG_ 2566907891 Bms0IBatSoc_FFE7F3 25000;
BA_ "CI_SigName" SG_ 2566907891 Bms0IBatSoc_FFE7F3 "BMS0i Battery SOC";
BA_ "CI_SigId" SG_ 2566907891 Bms0IBatSoc_FFE7F3 10809;
BA_ "CI_ParId" SG_ 2566907891 Bms0IBatSoc_FFE7F3 "IB574";
BA_ "SigType" SG_ 2566907891 Bms0IBatCur_FFE7F3 1;
BA_ "GenSigTimeoutTime_SGW" SG_ 2566907891 Bms0IBatCur_FFE7F3 25000;
BA_ "GenSigTimeoutTime_PCM" SG_ 2566907891 Bms0IBatCur_FFE7F3 25000;
BA_ "GenSigTimeoutTime_MPPxPTFE2" SG_ 2566907891 Bms0IBatCur_FFE7F3 25000;
BA_ "GenSigTimeoutTime_IC_MulticII" SG_ 2566907891 Bms0IBatCur_FFE7F3 25000;
BA_ "GenSigTimeoutTime_FMS_FMS4" SG_ 2566907891 Bms0IBatCur_FFE7F3 25000;
BA_ "GenSigStartValue" SG_ 2566907891 Bms0IBatCur_FFE7F3 125;
BA_ "CI_SigName" SG_ 2566907891 Bms0IBatCur_FFE7F3 "BMS0i Battery Current";
BA_ "CI_SigId" SG_ 2566907891 Bms0IBatCur_FFE7F3 10808;
BA_ "CI_ParId" SG_ 2566907891 Bms0IBatCur_FFE7F3 "IB573";
BA_ "SigType" SG_ 2566907891 Bms0IBatV_FFE7F3 1;
BA_ "GenSigTimeoutTime_SGW" SG_ 2566907891 Bms0IBatV_FFE7F3 25000;
BA_ "GenSigTimeoutTime_PCM" SG_ 2566907891 Bms0IBatV_FFE7F3 25000;
BA_ "GenSigTimeoutTime_MPPxPTFE2" SG_ 2566907891 Bms0IBatV_FFE7F3 25000;
BA_ "GenSigTimeoutTime_IC_MulticII" SG_ 2566907891 Bms0IBatV_FFE7F3 25000;
BA_ "GenSigTimeoutTime_FMS_FMS4" SG_ 2566907891 Bms0IBatV_FFE7F3 25000;
BA_ "CI_SigName" SG_ 2566907891 Bms0IBatV_FFE7F3 "BMS0i Battery Voltage";
BA_ "CI_SigId" SG_ 2566907891 Bms0IBatV_FFE7F3 10807;
BA_ "CI_ParId" SG_ 2566907891 Bms0IBatV_FFE7F3 "IB572";
BA_ "SigType" SG_ 2566908147 Bms0IMinCellTemp_FFE8F3 1;
BA_ "GenSigTimeoutTime_SGW" SG_ 2566908147 Bms0IMinCellTemp_FFE8F3 25000;
BA_ "GenSigTimeoutTime_PCM" SG_ 2566908147 Bms0IMinCellTemp_FFE8F3 25000;
BA_ "GenSigTimeoutTime_MPPxPTFE2" SG_ 2566908147 Bms0IMinCellTemp_FFE8F3 25000;
BA_ "GenSigTimeoutTime_IC_MulticII" SG_ 2566908147 Bms0IMinCellTemp_FFE8F3 25000;
BA_ "GenSigTimeoutTime_FMS_FMS4" SG_ 2566908147 Bms0IMinCellTemp_FFE8F3 25000;
BA_ "GenSigStartValue" SG_ 2566908147 Bms0IMinCellTemp_FFE8F3 40;
BA_ "CI_SigName" SG_ 2566908147 Bms0IMinCellTemp_FFE8F3 "BMS0i Min Cell Temperature";
BA_ "CI_SigId" SG_ 2566908147 Bms0IMinCellTemp_FFE8F3 10831;
BA_ "CI_ParId" SG_ 2566908147 Bms0IMinCellTemp_FFE8F3 "IB583";
BA_ "SigType" SG_ 2566908147 Bms0IMaxCellTemp_FFE8F3 1;
BA_ "GenSigTimeoutTime_SGW" SG_ 2566908147 Bms0IMaxCellTemp_FFE8F3 25000;
BA_ "GenSigTimeoutTime_PCM" SG_ 2566908147 Bms0IMaxCellTemp_FFE8F3 25000;
BA_ "GenSigTimeoutTime_MPPxPTFE2" SG_ 2566908147 Bms0IMaxCellTemp_FFE8F3 25000;
BA_ "GenSigTimeoutTime_IC_MulticII" SG_ 2566908147 Bms0IMaxCellTemp_FFE8F3 25000;
BA_ "GenSigTimeoutTime_FMS_FMS4" SG_ 2566908147 Bms0IMaxCellTemp_FFE8F3 25000;
BA_ "GenSigStartValue" SG_ 2566908147 Bms0IMaxCellTemp_FFE8F3 40;
BA_ "CI_SigName" SG_ 2566908147 Bms0IMaxCellTemp_FFE8F3 "BMS0i Max Cell Temperature";
BA_ "CI_SigId" SG_ 2566908147 Bms0IMaxCellTemp_FFE8F3 10830;
BA_ "CI_ParId" SG_ 2566908147 Bms0IMaxCellTemp_FFE8F3 "IB582";
BA_ "GenSigTimeoutTime_SGW" SG_ 2566908147 Bms0IPwrDistributed_FFE8F3 25000;
BA_ "GenSigTimeoutTime_PCM" SG_ 2566908147 Bms0IPwrDistributed_FFE8F3 25000;
BA_ "GenSigTimeoutTime_MPPxPTFE2" SG_ 2566908147 Bms0IPwrDistributed_FFE8F3 25000;
BA_ "GenSigTimeoutTime_IC_MulticII" SG_ 2566908147 Bms0IPwrDistributed_FFE8F3 25000;
BA_ "GenSigTimeoutTime_FMS_FMS4" SG_ 2566908147 Bms0IPwrDistributed_FFE8F3 25000;
BA_ "CI_SigName" SG_ 2566908147 Bms0IPwrDistributed_FFE8F3 "BMS0i Power Distributed";
BA_ "CI_SigId" SG_ 2566908147 Bms0IPwrDistributed_FFE8F3 10829;
BA_ "CI_ParId" SG_ 2566908147 Bms0IPwrDistributed_FFE8F3 "IB581";
BA_ "GenSigTimeoutTime_SGW" SG_ 2566908147 Bms0IChgCompl_FFE8F3 25000;
BA_ "GenSigTimeoutTime_PCM" SG_ 2566908147 Bms0IChgCompl_FFE8F3 25000;
BA_ "GenSigTimeoutTime_MPPxPTFE2" SG_ 2566908147 Bms0IChgCompl_FFE8F3 25000;
BA_ "GenSigTimeoutTime_IC_MulticII" SG_ 2566908147 Bms0IChgCompl_FFE8F3 25000;
BA_ "GenSigTimeoutTime_FMS_FMS4" SG_ 2566908147 Bms0IChgCompl_FFE8F3 25000;
BA_ "CI_SigName" SG_ 2566908147 Bms0IChgCompl_FFE8F3 "BMS0i Charge Completed";
BA_ "CI_SigId" SG_ 2566908147 Bms0IChgCompl_FFE8F3 10828;
BA_ "CI_ParId" SG_ 2566908147 Bms0IChgCompl_FFE8F3 "IB580";
BA_ "SigType" SG_ 2566908147 Bms0IOpSts_FFE8F3 4;
BA_ "GenSigTimeoutTime_SGW" SG_ 2566908147 Bms0IOpSts_FFE8F3 25000;
BA_ "GenSigTimeoutTime_PCM" SG_ 2566908147 Bms0IOpSts_FFE8F3 25000;
BA_ "GenSigTimeoutTime_MPPxPTFE2" SG_ 2566908147 Bms0IOpSts_FFE8F3 25000;
BA_ "GenSigTimeoutTime_IC_MulticII" SG_ 2566908147 Bms0IOpSts_FFE8F3 25000;
BA_ "GenSigTimeoutTime_FMS_FMS4" SG_ 2566908147 Bms0IOpSts_FFE8F3 25000;
BA_ "CI_SigName" SG_ 2566908147 Bms0IOpSts_FFE8F3 "BMS0i Operating Status";
BA_ "CI_SigId" SG_ 2566908147 Bms0IOpSts_FFE8F3 10827;
BA_ "CI_ParId" SG_ 2566908147 Bms0IOpSts_FFE8F3 "IB579";
BA_ "GenSigTimeoutTime_SGW" SG_ 2566908147 Bms0IActSts_FFE8F3 25000;
BA_ "GenSigTimeoutTime_PCM" SG_ 2566908147 Bms0IActSts_FFE8F3 25000;
BA_ "GenSigTimeoutTime_MPPxPTFE2" SG_ 2566908147 Bms0IActSts_FFE8F3 25000;
BA_ "GenSigTimeoutTime_IC_MulticII" SG_ 2566908147 Bms0IActSts_FFE8F3 25000;
BA_ "GenSigTimeoutTime_FMS_FMS4" SG_ 2566908147 Bms0IActSts_FFE8F3 25000;
BA_ "CI_SigName" SG_ 2566908147 Bms0IActSts_FFE8F3 "BMS0i Actual State";
BA_ "CI_SigId" SG_ 2566908147 Bms0IActSts_FFE8F3 10826;
BA_ "CI_ParId" SG_ 2566908147 Bms0IActSts_FFE8F3 "IB578";
BA_ "GenSigTimeoutTime_SGW" SG_ 2566908147 Bms0IEqualizationSts_FFE8F3 25000;
BA_ "GenSigTimeoutTime_PCM" SG_ 2566908147 Bms0IEqualizationSts_FFE8F3 25000;
BA_ "GenSigTimeoutTime_MPPxPTFE2" SG_ 2566908147 Bms0IEqualizationSts_FFE8F3 25000;
BA_ "GenSigTimeoutTime_IC_MulticII" SG_ 2566908147 Bms0IEqualizationSts_FFE8F3 25000;
BA_ "GenSigTimeoutTime_FMS_FMS4" SG_ 2566908147 Bms0IEqualizationSts_FFE8F3 25000;
BA_ "CI_SigName" SG_ 2566908147 Bms0IEqualizationSts_FFE8F3 "BMS0i Equalization Status";
BA_ "CI_SigId" SG_ 2566908147 Bms0IEqualizationSts_FFE8F3 10825;
BA_ "CI_ParId" SG_ 2566908147 Bms0IEqualizationSts_FFE8F3 "IB577";
BA_ "SigType" SG_ 2566908147 Bms0IMinCellV_FFE8F3 1;
BA_ "GenSigTimeoutTime_SGW" SG_ 2566908147 Bms0IMinCellV_FFE8F3 25000;
BA_ "GenSigTimeoutTime_PCM" SG_ 2566908147 Bms0IMinCellV_FFE8F3 25000;
BA_ "GenSigTimeoutTime_MPPxPTFE2" SG_ 2566908147 Bms0IMinCellV_FFE8F3 25000;
BA_ "GenSigTimeoutTime_IC_MulticII" SG_ 2566908147 Bms0IMinCellV_FFE8F3 25000;
BA_ "GenSigTimeoutTime_FMS_FMS4" SG_ 2566908147 Bms0IMinCellV_FFE8F3 25000;
BA_ "CI_SigName" SG_ 2566908147 Bms0IMinCellV_FFE8F3 "BMS0i Min Cell Voltage";
BA_ "CI_SigId" SG_ 2566908147 Bms0IMinCellV_FFE8F3 10824;
BA_ "CI_ParId" SG_ 2566908147 Bms0IMinCellV_FFE8F3 "IB576";
BA_ "SigType" SG_ 2566908147 Bms0IMaxCellV_FFE8F3 1;
BA_ "GenSigTimeoutTime_SGW" SG_ 2566908147 Bms0IMaxCellV_FFE8F3 25000;
BA_ "GenSigTimeoutTime_PCM" SG_ 2566908147 Bms0IMaxCellV_FFE8F3 25000;
BA_ "GenSigTimeoutTime_MPPxPTFE2" SG_ 2566908147 Bms0IMaxCellV_FFE8F3 25000;
BA_ "GenSigTimeoutTime_IC_MulticII" SG_ 2566908147 Bms0IMaxCellV_FFE8F3 25000;
BA_ "GenSigTimeoutTime_FMS_FMS4" SG_ 2566908147 Bms0IMaxCellV_FFE8F3 25000;
BA_ "CI_SigName" SG_ 2566908147 Bms0IMaxCellV_FFE8F3 "BMS0i Max Cell Voltage";
BA_ "CI_SigId" SG_ 2566908147 Bms0IMaxCellV_FFE8F3 10823;
BA_ "CI_ParId" SG_ 2566908147 Bms0IMaxCellV_FFE8F3 "IB575";
BA_ "SigType" SG_ 2566908147 Bms0IBatSoc_FFE8F3 1;
BA_ "GenSigTimeoutTime_SGW" SG_ 2566908147 Bms0IBatSoc_FFE8F3 25000;
BA_ "GenSigTimeoutTime_PCM" SG_ 2566908147 Bms0IBatSoc_FFE8F3 25000;
BA_ "GenSigTimeoutTime_MPPxPTFE2" SG_ 2566908147 Bms0IBatSoc_FFE8F3 25000;
BA_ "GenSigTimeoutTime_IC_MulticII" SG_ 2566908147 Bms0IBatSoc_FFE8F3 25000;
BA_ "GenSigTimeoutTime_FMS_FMS4" SG_ 2566908147 Bms0IBatSoc_FFE8F3 25000;
BA_ "CI_SigName" SG_ 2566908147 Bms0IBatSoc_FFE8F3 "BMS0i Battery SOC";
BA_ "CI_SigId" SG_ 2566908147 Bms0IBatSoc_FFE8F3 10822;
BA_ "CI_ParId" SG_ 2566908147 Bms0IBatSoc_FFE8F3 "IB574";
BA_ "SigType" SG_ 2566908147 Bms0IBatCur_FFE8F3 1;
BA_ "GenSigTimeoutTime_SGW" SG_ 2566908147 Bms0IBatCur_FFE8F3 25000;
BA_ "GenSigTimeoutTime_PCM" SG_ 2566908147 Bms0IBatCur_FFE8F3 25000;
BA_ "GenSigTimeoutTime_MPPxPTFE2" SG_ 2566908147 Bms0IBatCur_FFE8F3 25000;
BA_ "GenSigTimeoutTime_IC_MulticII" SG_ 2566908147 Bms0IBatCur_FFE8F3 25000;
BA_ "GenSigTimeoutTime_FMS_FMS4" SG_ 2566908147 Bms0IBatCur_FFE8F3 25000;
BA_ "GenSigStartValue" SG_ 2566908147 Bms0IBatCur_FFE8F3 125;
BA_ "CI_SigName" SG_ 2566908147 Bms0IBatCur_FFE8F3 "BMS0i Battery Current";
BA_ "CI_SigId" SG_ 2566908147 Bms0IBatCur_FFE8F3 10821;
BA_ "CI_ParId" SG_ 2566908147 Bms0IBatCur_FFE8F3 "IB573";
BA_ "SigType" SG_ 2566908147 Bms0IBatV_FFE8F3 1;
BA_ "GenSigTimeoutTime_SGW" SG_ 2566908147 Bms0IBatV_FFE8F3 25000;
BA_ "GenSigTimeoutTime_PCM" SG_ 2566908147 Bms0IBatV_FFE8F3 25000;
BA_ "GenSigTimeoutTime_MPPxPTFE2" SG_ 2566908147 Bms0IBatV_FFE8F3 25000;
BA_ "GenSigTimeoutTime_IC_MulticII" SG_ 2566908147 Bms0IBatV_FFE8F3 25000;
BA_ "GenSigTimeoutTime_FMS_FMS4" SG_ 2566908147 Bms0IBatV_FFE8F3 25000;
BA_ "CI_SigName" SG_ 2566908147 Bms0IBatV_FFE8F3 "BMS0i Battery Voltage";
BA_ "CI_SigId" SG_ 2566908147 Bms0IBatV_FFE8F3 10820;
BA_ "CI_ParId" SG_ 2566908147 Bms0IBatV_FFE8F3 "IB572";
BA_ "SigType" SG_ 2566908403 Bms0IMinCellTemp_FFE9F3 1;
BA_ "GenSigTimeoutTime_SGW" SG_ 2566908403 Bms0IMinCellTemp_FFE9F3 25000;
BA_ "GenSigTimeoutTime_PCM" SG_ 2566908403 Bms0IMinCellTemp_FFE9F3 25000;
BA_ "GenSigTimeoutTime_IC_MulticII" SG_ 2566908403 Bms0IMinCellTemp_FFE9F3 25000;
BA_ "GenSigTimeoutTime_FMS_FMS4" SG_ 2566908403 Bms0IMinCellTemp_FFE9F3 25000;
BA_ "GenSigStartValue" SG_ 2566908403 Bms0IMinCellTemp_FFE9F3 40;
BA_ "CI_SigName" SG_ 2566908403 Bms0IMinCellTemp_FFE9F3 "BMS0i Min Cell Temperature";
BA_ "CI_SigId" SG_ 2566908403 Bms0IMinCellTemp_FFE9F3 10844;
BA_ "CI_ParId" SG_ 2566908403 Bms0IMinCellTemp_FFE9F3 "IB583";
BA_ "SigType" SG_ 2566908403 Bms0IMaxCellTemp_FFE9F3 1;
BA_ "GenSigTimeoutTime_SGW" SG_ 2566908403 Bms0IMaxCellTemp_FFE9F3 25000;
BA_ "GenSigTimeoutTime_PCM" SG_ 2566908403 Bms0IMaxCellTemp_FFE9F3 25000;
BA_ "GenSigTimeoutTime_IC_MulticII" SG_ 2566908403 Bms0IMaxCellTemp_FFE9F3 25000;
BA_ "GenSigTimeoutTime_FMS_FMS4" SG_ 2566908403 Bms0IMaxCellTemp_FFE9F3 25000;
BA_ "GenSigStartValue" SG_ 2566908403 Bms0IMaxCellTemp_FFE9F3 40;
BA_ "CI_SigName" SG_ 2566908403 Bms0IMaxCellTemp_FFE9F3 "BMS0i Max Cell Temperature";
BA_ "CI_SigId" SG_ 2566908403 Bms0IMaxCellTemp_FFE9F3 10843;
BA_ "CI_ParId" SG_ 2566908403 Bms0IMaxCellTemp_FFE9F3 "IB582";
BA_ "GenSigTimeoutTime_SGW" SG_ 2566908403 Bms0IPwrDistributed_FFE9F3 25000;
BA_ "GenSigTimeoutTime_PCM" SG_ 2566908403 Bms0IPwrDistributed_FFE9F3 25000;
BA_ "GenSigTimeoutTime_IC_MulticII" SG_ 2566908403 Bms0IPwrDistributed_FFE9F3 25000;
BA_ "GenSigTimeoutTime_FMS_FMS4" SG_ 2566908403 Bms0IPwrDistributed_FFE9F3 25000;
BA_ "CI_SigName" SG_ 2566908403 Bms0IPwrDistributed_FFE9F3 "BMS0i Power Distributed";
BA_ "CI_SigId" SG_ 2566908403 Bms0IPwrDistributed_FFE9F3 10842;
BA_ "CI_ParId" SG_ 2566908403 Bms0IPwrDistributed_FFE9F3 "IB581";
BA_ "GenSigTimeoutTime_SGW" SG_ 2566908403 Bms0IChgCompl_FFE9F3 25000;
BA_ "GenSigTimeoutTime_PCM" SG_ 2566908403 Bms0IChgCompl_FFE9F3 25000;
BA_ "GenSigTimeoutTime_IC_MulticII" SG_ 2566908403 Bms0IChgCompl_FFE9F3 25000;
BA_ "GenSigTimeoutTime_FMS_FMS4" SG_ 2566908403 Bms0IChgCompl_FFE9F3 25000;
BA_ "CI_SigName" SG_ 2566908403 Bms0IChgCompl_FFE9F3 "BMS0i Charge Completed";
BA_ "CI_SigId" SG_ 2566908403 Bms0IChgCompl_FFE9F3 10841;
BA_ "CI_ParId" SG_ 2566908403 Bms0IChgCompl_FFE9F3 "IB580";
BA_ "SigType" SG_ 2566908403 Bms0IOpSts_FFE9F3 4;
BA_ "GenSigTimeoutTime_SGW" SG_ 2566908403 Bms0IOpSts_FFE9F3 25000;
BA_ "GenSigTimeoutTime_PCM" SG_ 2566908403 Bms0IOpSts_FFE9F3 25000;
BA_ "GenSigTimeoutTime_IC_MulticII" SG_ 2566908403 Bms0IOpSts_FFE9F3 25000;
BA_ "GenSigTimeoutTime_FMS_FMS4" SG_ 2566908403 Bms0IOpSts_FFE9F3 25000;
BA_ "CI_SigName" SG_ 2566908403 Bms0IOpSts_FFE9F3 "BMS0i Operating Status";
BA_ "CI_SigId" SG_ 2566908403 Bms0IOpSts_FFE9F3 10840;
BA_ "CI_ParId" SG_ 2566908403 Bms0IOpSts_FFE9F3 "IB579";
BA_ "GenSigTimeoutTime_SGW" SG_ 2566908403 Bms0IActSts_FFE9F3 25000;
BA_ "GenSigTimeoutTime_PCM" SG_ 2566908403 Bms0IActSts_FFE9F3 25000;
BA_ "GenSigTimeoutTime_IC_MulticII" SG_ 2566908403 Bms0IActSts_FFE9F3 25000;
BA_ "GenSigTimeoutTime_FMS_FMS4" SG_ 2566908403 Bms0IActSts_FFE9F3 25000;
BA_ "CI_SigName" SG_ 2566908403 Bms0IActSts_FFE9F3 "BMS0i Actual State";
BA_ "CI_SigId" SG_ 2566908403 Bms0IActSts_FFE9F3 10839;
BA_ "CI_ParId" SG_ 2566908403 Bms0IActSts_FFE9F3 "IB578";
BA_ "GenSigTimeoutTime_SGW" SG_ 2566908403 Bms0IEqualizationSts_FFE9F3 25000;
BA_ "GenSigTimeoutTime_PCM" SG_ 2566908403 Bms0IEqualizationSts_FFE9F3 25000;
BA_ "GenSigTimeoutTime_IC_MulticII" SG_ 2566908403 Bms0IEqualizationSts_FFE9F3 25000;
BA_ "GenSigTimeoutTime_FMS_FMS4" SG_ 2566908403 Bms0IEqualizationSts_FFE9F3 25000;
BA_ "CI_SigName" SG_ 2566908403 Bms0IEqualizationSts_FFE9F3 "BMS0i Equalization Status";
BA_ "CI_SigId" SG_ 2566908403 Bms0IEqualizationSts_FFE9F3 10838;
BA_ "CI_ParId" SG_ 2566908403 Bms0IEqualizationSts_FFE9F3 "IB577";
BA_ "SigType" SG_ 2566908403 Bms0IMinCellV_FFE9F3 1;
BA_ "GenSigTimeoutTime_SGW" SG_ 2566908403 Bms0IMinCellV_FFE9F3 25000;
BA_ "GenSigTimeoutTime_PCM" SG_ 2566908403 Bms0IMinCellV_FFE9F3 25000;
BA_ "GenSigTimeoutTime_IC_MulticII" SG_ 2566908403 Bms0IMinCellV_FFE9F3 25000;
BA_ "GenSigTimeoutTime_FMS_FMS4" SG_ 2566908403 Bms0IMinCellV_FFE9F3 25000;
BA_ "CI_SigName" SG_ 2566908403 Bms0IMinCellV_FFE9F3 "BMS0i Min Cell Voltage";
BA_ "CI_SigId" SG_ 2566908403 Bms0IMinCellV_FFE9F3 10837;
BA_ "CI_ParId" SG_ 2566908403 Bms0IMinCellV_FFE9F3 "IB576";
BA_ "SigType" SG_ 2566908403 Bms0IMaxCellV_FFE9F3 1;
BA_ "GenSigTimeoutTime_SGW" SG_ 2566908403 Bms0IMaxCellV_FFE9F3 25000;
BA_ "GenSigTimeoutTime_PCM" SG_ 2566908403 Bms0IMaxCellV_FFE9F3 25000;
BA_ "GenSigTimeoutTime_IC_MulticII" SG_ 2566908403 Bms0IMaxCellV_FFE9F3 25000;
BA_ "GenSigTimeoutTime_FMS_FMS4" SG_ 2566908403 Bms0IMaxCellV_FFE9F3 25000;
BA_ "CI_SigName" SG_ 2566908403 Bms0IMaxCellV_FFE9F3 "BMS0i Max Cell Voltage";
BA_ "CI_SigId" SG_ 2566908403 Bms0IMaxCellV_FFE9F3 10836;
BA_ "CI_ParId" SG_ 2566908403 Bms0IMaxCellV_FFE9F3 "IB575";
BA_ "SigType" SG_ 2566908403 Bms0IBatSoc_FFE9F3 1;
BA_ "GenSigTimeoutTime_SGW" SG_ 2566908403 Bms0IBatSoc_FFE9F3 25000;
BA_ "GenSigTimeoutTime_PCM" SG_ 2566908403 Bms0IBatSoc_FFE9F3 25000;
BA_ "GenSigTimeoutTime_IC_MulticII" SG_ 2566908403 Bms0IBatSoc_FFE9F3 25000;
BA_ "GenSigTimeoutTime_FMS_FMS4" SG_ 2566908403 Bms0IBatSoc_FFE9F3 25000;
BA_ "CI_SigName" SG_ 2566908403 Bms0IBatSoc_FFE9F3 "BMS0i Battery SOC";
BA_ "CI_SigId" SG_ 2566908403 Bms0IBatSoc_FFE9F3 10835;
BA_ "CI_ParId" SG_ 2566908403 Bms0IBatSoc_FFE9F3 "IB574";
BA_ "SigType" SG_ 2566908403 Bms0IBatCur_FFE9F3 1;
BA_ "GenSigTimeoutTime_SGW" SG_ 2566908403 Bms0IBatCur_FFE9F3 25000;
BA_ "GenSigTimeoutTime_PCM" SG_ 2566908403 Bms0IBatCur_FFE9F3 25000;
BA_ "GenSigTimeoutTime_IC_MulticII" SG_ 2566908403 Bms0IBatCur_FFE9F3 25000;
BA_ "GenSigTimeoutTime_FMS_FMS4" SG_ 2566908403 Bms0IBatCur_FFE9F3 25000;
BA_ "GenSigStartValue" SG_ 2566908403 Bms0IBatCur_FFE9F3 125;
BA_ "CI_SigName" SG_ 2566908403 Bms0IBatCur_FFE9F3 "BMS0i Battery Current";
BA_ "CI_SigId" SG_ 2566908403 Bms0IBatCur_FFE9F3 10834;
BA_ "CI_ParId" SG_ 2566908403 Bms0IBatCur_FFE9F3 "IB573";
BA_ "SigType" SG_ 2566908403 Bms0IBatV_FFE9F3 1;
BA_ "GenSigTimeoutTime_SGW" SG_ 2566908403 Bms0IBatV_FFE9F3 25000;
BA_ "GenSigTimeoutTime_PCM" SG_ 2566908403 Bms0IBatV_FFE9F3 25000;
BA_ "GenSigTimeoutTime_IC_MulticII" SG_ 2566908403 Bms0IBatV_FFE9F3 25000;
BA_ "GenSigTimeoutTime_FMS_FMS4" SG_ 2566908403 Bms0IBatV_FFE9F3 25000;
BA_ "CI_SigName" SG_ 2566908403 Bms0IBatV_FFE9F3 "BMS0i Battery Voltage";
BA_ "CI_SigId" SG_ 2566908403 Bms0IBatV_FFE9F3 10833;
BA_ "CI_ParId" SG_ 2566908403 Bms0IBatV_FFE9F3 "IB572";
BA_ "SigType" SG_ 2566908659 Bms0IMinCellTemp_FFEAF3 1;
BA_ "GenSigTimeoutTime_SGW" SG_ 2566908659 Bms0IMinCellTemp_FFEAF3 25000;
BA_ "GenSigTimeoutTime_PCM" SG_ 2566908659 Bms0IMinCellTemp_FFEAF3 25000;
BA_ "GenSigTimeoutTime_IC_MulticII" SG_ 2566908659 Bms0IMinCellTemp_FFEAF3 25000;
BA_ "GenSigTimeoutTime_FMS_FMS4" SG_ 2566908659 Bms0IMinCellTemp_FFEAF3 25000;
BA_ "GenSigStartValue" SG_ 2566908659 Bms0IMinCellTemp_FFEAF3 40;
BA_ "CI_SigName" SG_ 2566908659 Bms0IMinCellTemp_FFEAF3 "BMS0i Min Cell Temperature";
BA_ "CI_SigId" SG_ 2566908659 Bms0IMinCellTemp_FFEAF3 10857;
BA_ "CI_ParId" SG_ 2566908659 Bms0IMinCellTemp_FFEAF3 "IB583";
BA_ "SigType" SG_ 2566908659 Bms0IMaxCellTemp_FFEAF3 1;
BA_ "GenSigTimeoutTime_SGW" SG_ 2566908659 Bms0IMaxCellTemp_FFEAF3 25000;
BA_ "GenSigTimeoutTime_PCM" SG_ 2566908659 Bms0IMaxCellTemp_FFEAF3 25000;
BA_ "GenSigTimeoutTime_IC_MulticII" SG_ 2566908659 Bms0IMaxCellTemp_FFEAF3 25000;
BA_ "GenSigTimeoutTime_FMS_FMS4" SG_ 2566908659 Bms0IMaxCellTemp_FFEAF3 25000;
BA_ "GenSigStartValue" SG_ 2566908659 Bms0IMaxCellTemp_FFEAF3 40;
BA_ "CI_SigName" SG_ 2566908659 Bms0IMaxCellTemp_FFEAF3 "BMS0i Max Cell Temperature";
BA_ "CI_SigId" SG_ 2566908659 Bms0IMaxCellTemp_FFEAF3 10856;
BA_ "CI_ParId" SG_ 2566908659 Bms0IMaxCellTemp_FFEAF3 "IB582";
BA_ "GenSigTimeoutTime_SGW" SG_ 2566908659 Bms0IPwrDistributed_FFEAF3 25000;
BA_ "GenSigTimeoutTime_PCM" SG_ 2566908659 Bms0IPwrDistributed_FFEAF3 25000;
BA_ "GenSigTimeoutTime_IC_MulticII" SG_ 2566908659 Bms0IPwrDistributed_FFEAF3 25000;
BA_ "GenSigTimeoutTime_FMS_FMS4" SG_ 2566908659 Bms0IPwrDistributed_FFEAF3 25000;
BA_ "CI_SigName" SG_ 2566908659 Bms0IPwrDistributed_FFEAF3 "BMS0i Power Distributed";
BA_ "CI_SigId" SG_ 2566908659 Bms0IPwrDistributed_FFEAF3 10855;
BA_ "CI_ParId" SG_ 2566908659 Bms0IPwrDistributed_FFEAF3 "IB581";
BA_ "GenSigTimeoutTime_SGW" SG_ 2566908659 Bms0IChgCompl_FFEAF3 25000;
BA_ "GenSigTimeoutTime_PCM" SG_ 2566908659 Bms0IChgCompl_FFEAF3 25000;
BA_ "GenSigTimeoutTime_IC_MulticII" SG_ 2566908659 Bms0IChgCompl_FFEAF3 25000;
BA_ "GenSigTimeoutTime_FMS_FMS4" SG_ 2566908659 Bms0IChgCompl_FFEAF3 25000;
BA_ "CI_SigName" SG_ 2566908659 Bms0IChgCompl_FFEAF3 "BMS0i Charge Completed";
BA_ "CI_SigId" SG_ 2566908659 Bms0IChgCompl_FFEAF3 10854;
BA_ "CI_ParId" SG_ 2566908659 Bms0IChgCompl_FFEAF3 "IB580";
BA_ "SigType" SG_ 2566908659 Bms0IOpSts_FFEAF3 4;
BA_ "GenSigTimeoutTime_SGW" SG_ 2566908659 Bms0IOpSts_FFEAF3 25000;
BA_ "GenSigTimeoutTime_PCM" SG_ 2566908659 Bms0IOpSts_FFEAF3 25000;
BA_ "GenSigTimeoutTime_IC_MulticII" SG_ 2566908659 Bms0IOpSts_FFEAF3 25000;
BA_ "GenSigTimeoutTime_FMS_FMS4" SG_ 2566908659 Bms0IOpSts_FFEAF3 25000;
BA_ "CI_SigName" SG_ 2566908659 Bms0IOpSts_FFEAF3 "BMS0i Operating Status";
BA_ "CI_SigId" SG_ 2566908659 Bms0IOpSts_FFEAF3 10853;
BA_ "CI_ParId" SG_ 2566908659 Bms0IOpSts_FFEAF3 "IB579";
BA_ "GenSigTimeoutTime_SGW" SG_ 2566908659 Bms0IActSts_FFEAF3 25000;
BA_ "GenSigTimeoutTime_PCM" SG_ 2566908659 Bms0IActSts_FFEAF3 25000;
BA_ "GenSigTimeoutTime_IC_MulticII" SG_ 2566908659 Bms0IActSts_FFEAF3 25000;
BA_ "GenSigTimeoutTime_FMS_FMS4" SG_ 2566908659 Bms0IActSts_FFEAF3 25000;
BA_ "CI_SigName" SG_ 2566908659 Bms0IActSts_FFEAF3 "BMS0i Actual State";
BA_ "CI_SigId" SG_ 2566908659 Bms0IActSts_FFEAF3 10852;
BA_ "CI_ParId" SG_ 2566908659 Bms0IActSts_FFEAF3 "IB578";
BA_ "GenSigTimeoutTime_SGW" SG_ 2566908659 Bms0IEqualizationSts_FFEAF3 25000;
BA_ "GenSigTimeoutTime_PCM" SG_ 2566908659 Bms0IEqualizationSts_FFEAF3 25000;
BA_ "GenSigTimeoutTime_IC_MulticII" SG_ 2566908659 Bms0IEqualizationSts_FFEAF3 25000;
BA_ "GenSigTimeoutTime_FMS_FMS4" SG_ 2566908659 Bms0IEqualizationSts_FFEAF3 25000;
BA_ "CI_SigName" SG_ 2566908659 Bms0IEqualizationSts_FFEAF3 "BMS0i Equalization Status";
BA_ "CI_SigId" SG_ 2566908659 Bms0IEqualizationSts_FFEAF3 10851;
BA_ "CI_ParId" SG_ 2566908659 Bms0IEqualizationSts_FFEAF3 "IB577";
BA_ "SigType" SG_ 2566908659 Bms0IMinCellV_FFEAF3 1;
BA_ "GenSigTimeoutTime_SGW" SG_ 2566908659 Bms0IMinCellV_FFEAF3 25000;
BA_ "GenSigTimeoutTime_PCM" SG_ 2566908659 Bms0IMinCellV_FFEAF3 25000;
BA_ "GenSigTimeoutTime_IC_MulticII" SG_ 2566908659 Bms0IMinCellV_FFEAF3 25000;
BA_ "GenSigTimeoutTime_FMS_FMS4" SG_ 2566908659 Bms0IMinCellV_FFEAF3 25000;
BA_ "CI_SigName" SG_ 2566908659 Bms0IMinCellV_FFEAF3 "BMS0i Min Cell Voltage";
BA_ "CI_SigId" SG_ 2566908659 Bms0IMinCellV_FFEAF3 10850;
BA_ "CI_ParId" SG_ 2566908659 Bms0IMinCellV_FFEAF3 "IB576";
BA_ "SigType" SG_ 2566908659 Bms0IMaxCellV_FFEAF3 1;
BA_ "GenSigTimeoutTime_SGW" SG_ 2566908659 Bms0IMaxCellV_FFEAF3 25000;
BA_ "GenSigTimeoutTime_PCM" SG_ 2566908659 Bms0IMaxCellV_FFEAF3 25000;
BA_ "GenSigTimeoutTime_IC_MulticII" SG_ 2566908659 Bms0IMaxCellV_FFEAF3 25000;
BA_ "GenSigTimeoutTime_FMS_FMS4" SG_ 2566908659 Bms0IMaxCellV_FFEAF3 25000;
BA_ "CI_SigName" SG_ 2566908659 Bms0IMaxCellV_FFEAF3 "BMS0i Max Cell Voltage";
BA_ "CI_SigId" SG_ 2566908659 Bms0IMaxCellV_FFEAF3 10849;
BA_ "CI_ParId" SG_ 2566908659 Bms0IMaxCellV_FFEAF3 "IB575";
BA_ "SigType" SG_ 2566908659 Bms0IBatSoc_FFEAF3 1;
BA_ "GenSigTimeoutTime_SGW" SG_ 2566908659 Bms0IBatSoc_FFEAF3 25000;
BA_ "GenSigTimeoutTime_PCM" SG_ 2566908659 Bms0IBatSoc_FFEAF3 25000;
BA_ "GenSigTimeoutTime_IC_MulticII" SG_ 2566908659 Bms0IBatSoc_FFEAF3 25000;
BA_ "GenSigTimeoutTime_FMS_FMS4" SG_ 2566908659 Bms0IBatSoc_FFEAF3 25000;
BA_ "CI_SigName" SG_ 2566908659 Bms0IBatSoc_FFEAF3 "BMS0i Battery SOC";
BA_ "CI_SigId" SG_ 2566908659 Bms0IBatSoc_FFEAF3 10848;
BA_ "CI_ParId" SG_ 2566908659 Bms0IBatSoc_FFEAF3 "IB574";
BA_ "SigType" SG_ 2566908659 Bms0IBatCur_FFEAF3 1;
BA_ "GenSigTimeoutTime_SGW" SG_ 2566908659 Bms0IBatCur_FFEAF3 25000;
BA_ "GenSigTimeoutTime_PCM" SG_ 2566908659 Bms0IBatCur_FFEAF3 25000;
BA_ "GenSigTimeoutTime_IC_MulticII" SG_ 2566908659 Bms0IBatCur_FFEAF3 25000;
BA_ "GenSigTimeoutTime_FMS_FMS4" SG_ 2566908659 Bms0IBatCur_FFEAF3 25000;
BA_ "GenSigStartValue" SG_ 2566908659 Bms0IBatCur_FFEAF3 125;
BA_ "CI_SigName" SG_ 2566908659 Bms0IBatCur_FFEAF3 "BMS0i Battery Current";
BA_ "CI_SigId" SG_ 2566908659 Bms0IBatCur_FFEAF3 10847;
BA_ "CI_ParId" SG_ 2566908659 Bms0IBatCur_FFEAF3 "IB573";
BA_ "SigType" SG_ 2566908659 Bms0IBatV_FFEAF3 1;
BA_ "GenSigTimeoutTime_SGW" SG_ 2566908659 Bms0IBatV_FFEAF3 25000;
BA_ "GenSigTimeoutTime_PCM" SG_ 2566908659 Bms0IBatV_FFEAF3 25000;
BA_ "GenSigTimeoutTime_IC_MulticII" SG_ 2566908659 Bms0IBatV_FFEAF3 25000;
BA_ "GenSigTimeoutTime_FMS_FMS4" SG_ 2566908659 Bms0IBatV_FFEAF3 25000;
BA_ "CI_SigName" SG_ 2566908659 Bms0IBatV_FFEAF3 "BMS0i Battery Voltage";
BA_ "CI_SigId" SG_ 2566908659 Bms0IBatV_FFEAF3 10846;
BA_ "CI_ParId" SG_ 2566908659 Bms0IBatV_FFEAF3 "IB572";
BA_ "GenSigTimeoutTime_SGW2" SG_ 2566883678 CalSucclyMade 2500;
BA_ "GenSigTimeoutTime_SGW" SG_ 2566883678 CalSucclyMade 2500;
BA_ "GenSigTimeoutTime_PCM" SG_ 2566883678 CalSucclyMade 2500;
BA_ "CI_SigName" SG_ 2566883678 CalSucclyMade "Calibration successfully made";
BA_ "CI_SigId" SG_ 2566883678 CalSucclyMade 2826;
BA_ "CI_ParId" SG_ 2566883678 CalSucclyMade "IB441";
BA_ "GenSigTimeoutTime_SGW2" SG_ 2566883678 HandsetConnSts 2500;
BA_ "GenSigTimeoutTime_SGW" SG_ 2566883678 HandsetConnSts 2500;
BA_ "GenSigTimeoutTime_PCM" SG_ 2566883678 HandsetConnSts 2500;
BA_ "CI_SigName" SG_ 2566883678 HandsetConnSts "Handset connection state";
BA_ "CI_SigId" SG_ 2566883678 HandsetConnSts 2825;
BA_ "CI_ParId" SG_ 2566883678 HandsetConnSts "IB440";
BA_ "GenSigTimeoutTime_SGW2" SG_ 2566883678 CaidActv 2500;
BA_ "GenSigTimeoutTime_SGW" SG_ 2566883678 CaidActv 2500;
BA_ "GenSigTimeoutTime_PCM" SG_ 2566883678 CaidActv 2500;
BA_ "CI_SigName" SG_ 2566883678 CaidActv "CAID Activation";
BA_ "CI_SigId" SG_ 2566883678 CaidActv 2824;
BA_ "CI_ParId" SG_ 2566883678 CaidActv "IB439";
BA_ "GenSigTimeoutTime_SGW2" SG_ 2566883678 StartViolation 2500;
BA_ "GenSigTimeoutTime_SGW" SG_ 2566883678 StartViolation 2500;
BA_ "GenSigTimeoutTime_PCM" SG_ 2566883678 StartViolation 2500;
BA_ "CI_SigName" SG_ 2566883678 StartViolation "Start violation";
BA_ "CI_SigId" SG_ 2566883678 StartViolation 2823;
BA_ "CI_ParId" SG_ 2566883678 StartViolation "IB438";
BA_ "GenSigTimeoutTime_SGW2" SG_ 2566883678 AcceptedBreathSample 2500;
BA_ "GenSigTimeoutTime_SGW" SG_ 2566883678 AcceptedBreathSample 2500;
BA_ "GenSigTimeoutTime_PCM" SG_ 2566883678 AcceptedBreathSample 2500;
BA_ "CI_SigName" SG_ 2566883678 AcceptedBreathSample "Accepted breath sample";
BA_ "CI_SigId" SG_ 2566883678 AcceptedBreathSample 2822;
BA_ "CI_ParId" SG_ 2566883678 AcceptedBreathSample "IB437";
BA_ "GenSigTimeoutTime_SGW2" SG_ 2566883678 BreathAnalyze 2500;
BA_ "GenSigTimeoutTime_SGW" SG_ 2566883678 BreathAnalyze 2500;
BA_ "GenSigTimeoutTime_PCM" SG_ 2566883678 BreathAnalyze 2500;
BA_ "CI_SigName" SG_ 2566883678 BreathAnalyze "Breath Analyze";
BA_ "CI_SigId" SG_ 2566883678 BreathAnalyze 2821;
BA_ "CI_ParId" SG_ 2566883678 BreathAnalyze "IB436";
BA_ "GenSigTimeoutTime_SGW2" SG_ 2566883678 CaidPwrSts 2500;
BA_ "GenSigTimeoutTime_SGW" SG_ 2566883678 CaidPwrSts 2500;
BA_ "GenSigTimeoutTime_PCM" SG_ 2566883678 CaidPwrSts 2500;
BA_ "CI_SigName" SG_ 2566883678 CaidPwrSts "CAID power state";
BA_ "CI_SigId" SG_ 2566883678 CaidPwrSts 2820;
BA_ "CI_ParId" SG_ 2566883678 CaidPwrSts "IB435";
BA_ "GenSigTimeoutTime_SGW2" SG_ 2566883678 WarmUp 2500;
BA_ "GenSigTimeoutTime_SGW" SG_ 2566883678 WarmUp 2500;
BA_ "GenSigTimeoutTime_PCM" SG_ 2566883678 WarmUp 2500;
BA_ "CI_SigName" SG_ 2566883678 WarmUp "Warm up";
BA_ "CI_SigId" SG_ 2566883678 WarmUp 2819;
BA_ "CI_ParId" SG_ 2566883678 WarmUp "IB434";
BA_ "GenSigTimeoutTime_SGW2" SG_ 2566884190 DeferredData 5000;
BA_ "GenSigTimeoutTime_SGW" SG_ 2566884190 DeferredData 5000;
BA_ "GenSigTimeoutTime_PCM" SG_ 2566884190 DeferredData 5000;
BA_ "CI_SigName" SG_ 2566884190 DeferredData "Deferred data";
BA_ "CI_SigId" SG_ 2566884190 DeferredData 2834;
BA_ "CI_ParId" SG_ 2566884190 DeferredData "IB442";
BA_ "SigType" SG_ 2566843648 DcdcCurSetPnt24VSide 1;
BA_ "GenSigTimeoutTime_VCM" SG_ 2566843648 DcdcCurSetPnt24VSide 1250;
BA_ "GenSigTimeoutTime_SGW" SG_ 2566843648 DcdcCurSetPnt24VSide 1250;
BA_ "GenSigTimeoutTime_PCM" SG_ 2566843648 DcdcCurSetPnt24VSide 1250;
BA_ "GenSigTimeoutTime_ETC_DiwaNXT_MH" SG_ 2566843648 DcdcCurSetPnt24VSide 1250;
BA_ "CI_SigName" SG_ 2566843648 DcdcCurSetPnt24VSide "DCDC current set-point for the 24V side";
BA_ "CI_SigId" SG_ 2566843648 DcdcCurSetPnt24VSide 2169;
BA_ "CI_ParId" SG_ 2566843648 DcdcCurSetPnt24VSide "IB271";
BA_ "SigType" SG_ 2566843648 MaxVsl 1;
BA_ "SPN" SG_ 2566843648 MaxVsl 74;
BA_ "GenSigTimeoutTime_VCM" SG_ 2566843648 MaxVsl 1250;
BA_ "GenSigTimeoutTime_SGW" SG_ 2566843648 MaxVsl 1250;
BA_ "GenSigTimeoutTime_PCM" SG_ 2566843648 MaxVsl 1250;
BA_ "CI_SigName" SG_ 2566843648 MaxVsl "Maximum Vehicle Speed Limit";
BA_ "CI_SigId" SG_ 2566843648 MaxVsl 2165;
BA_ "CI_ParId" SG_ 2566843648 MaxVsl "74";
BA_ "SigType" SG_ 2566843676 MaxVsl_FEED1C 1;
BA_ "SPN" SG_ 2566843676 MaxVsl_FEED1C 74;
BA_ "GenSigTimeoutTime_SGW" SG_ 2566843676 MaxVsl_FEED1C 5000;
BA_ "GenSigTimeoutTime_ADCU" SG_ 2566843676 MaxVsl_FEED1C 5000;
BA_ "GenSigSendType" SG_ 2566843676 MaxVsl_FEED1C 3;
BA_ "CI_SigName" SG_ 2566843676 MaxVsl_FEED1C "Maximum Vehicle Speed Limit";
BA_ "CI_SigId" SG_ 2566843676 MaxVsl_FEED1C 2171;
BA_ "CI_ParId" SG_ 2566843676 MaxVsl_FEED1C "74";
VAL_ 2566859292 Pos_RelHead 0 "In path direction" 1 "1.417° right from path dir" 2 "2.835° right from path dir" 3 "4.252° right from path dir" 4 "5.669° right from path dir" 5 "7.087° right from path dir" 6 "8.504° right from path dir" 7 "9.921° right from path dir" 8 "11.339° right from path dir" 9 "12.756° right from path dir" 10 "14.173° right from path dir" 11 "15.591° right from path dir" 12 "17.008° right from path dir" 13 "18.425° right from path dir" 14 "19.843° right from path dir" 15 "21.26° right from path dir" 16 "22.677° right from path dir" 17 "24.094° right from path dir" 18 "25.512° right from path dir" 19 "26.929° right from path dir" 20 "28.346° right from path dir" 21 "29.764° right from path dir" 22 "31.181° right from path dir" 23 "32.598° right from path dir" 24 "34.016° right from path dir" 25 "35.433° right from path dir" 26 "36.85° right from path dir" 27 "38.268° right from path dir" 28 "39.685° right from path dir" 29 "41.102° right from path dir" 30 "42.52° right from path dir" 31 "43.937° right from path dir" 32 "45.354° right from path dir" 33 "46.772° right from path dir" 34 "48.189° right from path dir" 35 "49.606° right from path dir" 36 "51.024° right from path dir" 37 "52.441° right from path dir" 38 "53.858° right from path dir" 39 "55.276° right from path dir" 40 "56.693° right from path dir" 41 "58.11° right from path dir" 42 "59.528° right from path dir" 43 "60.945° right from path dir" 44 "62.362° right from path dir" 45 "63.78° right from path dir" 46 "65.197° right from path dir" 47 "66.614° right from path dir" 48 "68.031° right from path dir" 49 "69.449° right from path dir" 50 "70.866° right from path dir" 51 "72.283° right from path dir" 52 "73.701° right from path dir" 53 "75.118° right from path dir" 54 "76.535° right from path dir" 55 "77.953° right from path dir" 56 "79.37° right from path dir" 57 "80.787° right from path dir" 58 "82.205° right from path dir" 59 "83.622° right from path dir" 60 "85.039° right from path dir" 61 "86.457° right from path dir" 62 "87.874° right from path dir" 63 "89.291° right from path dir" 64 "90.709° right from path dir" 65 "92.126° right from path dir" 66 "93.543° right from path dir" 67 "94.961° right from path dir" 68 "96.378° right from path dir" 69 "97.795° right from path dir" 70 "99.213° right from path dir" 71 "100.63° right from path dir" 72 "102.047° right from path dir" 73 "103.465° right from path dir" 74 "104.882° right from path dir" 75 "106.299° right from path dir" 76 "107.717° right from path dir" 77 "109.134° right from path dir" 78 "110.551° right from path dir" 79 "111.969° right from path dir" 80 "113.386° right from path dir" 81 "114.803° right from path dir" 82 "116.22° right from path dir" 83 "117.638° right from path dir" 84 "119.055° right from path dir" 85 "120.472° right from path dir" 86 "121.89° right from path dir" 87 "123.307° right from path dir" 88 "124.724° right from path dir" 89 "126.142° right from path dir" 90 "127.559° right from path dir" 91 "128.976° right from path dir" 92 "130.394° right from path dir" 93 "131.811° right from path dir" 94 "133.228° right from path dir" 95 "134.646° right from path dir" 96 "136.063° right from path dir" 97 "137.48° right from path dir" 98 "138.898° right from path dir" 99 "140.315° right from path dir" 100 "141.732° right from path dir" 101 "143.15° right from path dir" 102 "144.567° right from path dir" 103 "145.984° right from path dir" 104 "147.402° right from path dir" 105 "148.819° right from path dir" 106 "150.236° right from path dir" 107 "151.654° right from path dir" 108 "153.071° right from path dir" 109 "154.488° right from path dir" 110 "155.906° right from path dir" 111 "157.323° right from path dir" 112 "158.74° right from path dir" 113 "160.157° right from path dir" 114 "161.575° right from path dir" 115 "162.992° right from path dir" 116 "164.409° right from path dir" 117 "165.827° right from path dir" 118 "167.244° right from path dir" 119 "168.661° right from path dir" 120 "170.079° right from path dir" 121 "171.496° right from path dir" 122 "172.913° right from path dir" 123 "174.331° right from path dir" 124 "175.748° right from path dir" 125 "177.165° right from path dir" 126 "178.583° right from path dir" 127 "Opposite direction" 128 "178.583° left from path dir" 129 "177.165° left from path dir" 130 "175.748° left from path dir" 131 "174.331° left from path dir" 132 "172.913° left from path dir" 133 "171.496° left from path dir" 134 "170.079° left from path dir" 135 "168.661° left from path dir" 136 "167.244° left from path dir" 137 "165.827° left from path dir" 138 "164.409° left from path dir" 139 "162.992° left from path dir" 140 "161.575° left from path dir" 141 "160.157° left from path dir" 142 "158.74° left from path dir" 143 "157.323° left from path dir" 144 "155.906° left from path dir" 145 "154.488° left from path dir" 146 "153.071° left from path dir" 147 "151.654° left from path dir" 148 "150.236° left from path dir" 149 "148.819° left from path dir" 150 "147.402° left from path dir" 151 "145.984° left from path dir" 152 "144.567° left from path dir" 153 "143.15° left from path dir" 154 "141.732° left from path dir" 155 "140.315° left from path dir" 156 "138.898° left from path dir" 157 "137.48° left from path dir" 158 "136.063° left from path dir" 159 "134.646° left from path dir" 160 "133.228° left from path dir" 161 "131.811° left from path dir" 162 "130.394° left from path dir" 163 "128.976° left from path dir" 164 "127.559° left from path dir" 165 "126.142° left from path dir" 166 "124.724° left from path dir" 167 "123.307° left from path dir" 168 "121.89° left from path dir" 169 "120.472° left from path dir" 170 "119.055° left from path dir" 171 "117.638° left from path dir" 172 "116.22° left from path dir" 173 "114.803° left from path dir" 174 "113.386° left from path dir" 175 "111.969° left from path dir" 176 "110.551° left from path dir" 177 "109.134° left from path dir" 178 "107.717° left from path dir" 179 "106.299° left from path dir" 180 "104.882° left from path dir" 181 "103.465° left from path dir" 182 "102.047° left from path dir" 183 "100.63° left from path dir" 184 "99.213° left from path dir" 185 "97.795° left from path dir" 186 "96.378° left from path dir" 187 "94.961° left from path dir" 188 "93.543° left from path dir" 189 "92.126° left from path dir" 190 "90.709° left from path dir" 191 "89.291° left from path dir" 192 "87.874° left from path dir" 193 "86.457° left from path dir" 194 "85.039° left from path dir" 195 "83.622° left from path dir" 196 "82.205° left from path dir" 197 "80.787° left from path dir" 198 "79.37° left from path dir" 199 "77.953° left from path dir" 200 "76.535° left from path dir" 201 "75.118° left from path dir" 202 "73.701° left from path dir" 203 "72.283° left from path dir" 204 "70.866° left from path dir" 205 "69.449° left from path dir" 206 "68.031° left from path dir" 207 "66.614° left from path dir" 208 "65.197° left from path dir" 209 "63.78° left from path dir" 210 "62.362° left from path dir" 211 "60.945° left from path dir" 212 "59.528° left from path dir" 213 "58.11° left from path dir" 214 "56.693° left from path dir" 215 "55.276° left from path dir" 216 "53.858° left from path dir" 217 "52.441° left from path dir" 218 "51.024° left from path dir" 219 "49.606° left from path dir" 220 "48.189° left from path dir" 221 "46.772° left from path dir" 222 "45.354° left from path dir" 223 "43.937° left from path dir" 224 "42.52° left from path dir" 225 "41.102° left from path dir" 226 "39.685° left from path dir" 227 "38.268° left from path dir" 228 "36.85° left from path dir" 229 "35.433° left from path dir" 230 "34.016° left from path dir" 231 "32.598° left from path dir" 232 "31.181° left from path dir" 233 "29.764° left from path dir" 234 "28.346° left from path dir" 235 "26.929° left from path dir" 236 "25.512° left from path dir" 237 "24.094° left from path dir" 238 "22.677° left from path dir" 239 "21.26° left from path dir" 240 "19.843° left from path dir" 241 "18.425° left from path dir" 242 "17.008° left from path dir" 243 "15.591° left from path dir" 244 "14.173° left from path dir" 245 "12.756° left from path dir" 246 "11.339° left from path dir" 247 "9.921° left from path dir" 248 "8.504° left from path dir" 249 "7.087° left from path dir" 250 "5.669° left from path dir" 251 "4.252° left from path dir" 252 "2.835° left from path dir" 253 "1.417° left from path dir" 254 "Unknown" 255 "N/A" ;
VAL_ 2566859292 Pos_Speed 510 "=+89.2 m/s" 511 "N/A" ;
VAL_ 2566859292 Pos_CurLane 0 "Unknown" 1 "Emergency lane" 2 "Single-lane road" 3 "Left-most lane" 4 "Right-most lane" 5 "Middle (road with >3 lanes)" 6 "Reserved" 7 "N/A" ;
VAL_ 2566859292 Pos_PosConf 7 "N/A" ;
VAL_ 2566859292 Pos_PosAge 510 "2545 ms" 511 "N/A" ;
VAL_ 2566859292 Pos_PosProb 0 "Unknown" 31 "N/A" ;
VAL_ 2566859292 Pos_PathIx 0 "Unknown" 1 "Not in Digitized Area" 2 "Not on-road" 3 "Av2HP not calibrated" 7 "Reserved" ;
VAL_ 2566859292 Pos_Ofs 8191 "Invalid" ;
VAL_ 2566859292 MsgType 0 "Reserved" 1 "POSITION" 2 "SEGMENT" 3 "STUB" 4 "PROFILE SHORT" 5 "PROFILE LONG" 6 "META-DATA" 7 "Reserved" ;
VAL_ 2566859548 Seg_NumOfLanesInDrivDir 0 "One-direction road in wrong dir" 1 "1 lane" 2 "2 lanes" 3 "3 lanes" 4 "4 lanes" 5 "5 lanes" 6 "6 or more lanes" 7 "N/A" ;
VAL_ 2566859548 Seg_NumOfLanesInOppDir 0 "One-direction road" 1 "1 lane only" 2 "2 or more lanes" 3 "N/A" ;
VAL_ 2566859548 Seg_DividedRoad 0 "Not part of a divided/dual road" 1 "Part of a divided/dual road" 2 "Unknown" 3 "N/A" ;
VAL_ 2566859548 Seg_EffSpeedLimType 0 "Implicit" 1 "Explicit, on traffic sign" 2 "Explicit, by night" 3 "Explicit, by day" 4 "Explicit, time of day" 5 "Explicit, rain" 6 "Explicit, snow" 7 "Unknown" ;
VAL_ 2566859548 Seg_EffSpeedLim 0 "Unknown" 1 "= 5km/h(mph)" 2 "7km/h(mph)" 3 "10km/h(mph)" 4 "15km/h(mph)" 5 "20km/h(mph)" 6 "25km/h(mph)" 7 "30km/h(mph)" 8 "35km/h(mph)" 9 "40km/h(mph)" 10 "45km/h(mph)" 11 "50km/h(mph)" 12 "55km/h(mph)" 13 "60km/h(mph)" 14 "65km/h(mph)" 15 "70km/h(mph)" 16 "75km/h(mph)" 17 "80km/h(mph)" 18 "85km/h(mph)" 19 "90km/h(mph)" 20 "95km/h(mph)" 21 "100km/h(mph)" 22 "105km/h(mph)" 23 "110km/h(mph)" 24 "115km/h(mph)" 25 "120km/h(mph)" 26 "130km/h(mph)" 27 "140km/h(mph)" 28 "150km/h(mph)" 29 "160km/h(mph)" 30 "Unlimited" 31 "N/A" ;
VAL_ 2566859548 Seg_FormOfWay 0 "Unknown" 1 "Freeway/CntrldAccess Rd" 2 "Multiple Carriageway/Digitized" 3 "Single Carriageway (default)" 4 "Roundabout Circle" 5 "Traffic Square/Special Traffic" 6 "Reserved" 7 "Reserved" 8 "Parallel Road" 9 "Freeway/CntrldAccess SlipRd" 10 "SlipRd, not on Freeway/CntrldAcc" 11 "Service/Frontage Rd" 12 "CarPark Entrance/Exit" 13 "Service Entrance/Exit" 14 "Pedestrian Zone" ;
VAL_ 2566859548 Seg_ComplexInters 0 "Not part of complex intersection" 1 "Part of a complex intersection" 2 "Unknown" 3 "N/A" ;
VAL_ 2566859548 Seg_PartOfCalcRoute 0 "Not part of Calculated Route" 1 "Part of Calculated Route" 2 "Unknown" 3 "N/A" ;
VAL_ 2566859548 Seg_FunctRoadClass 0 "Unknown" 1 "Class 1" 2 "Class 2" 3 "Class 3" 4 "Class 4" 5 "Class 5" 6 "Class 6" 7 "N/A" ;
VAL_ 2566859548 Seg_RelProb 0 "Driving not allowed on this segm" 31 "Unknown or N/A" ;
VAL_ 2566859548 Seg_Update 0 "False" 1 "True" ;
VAL_ 2566859548 Seg_Retr 0 "False" 1 "True" ;
VAL_ 2566859548 Seg_BuiltUpArea 0 "Not part of a built-up area" 1 "Part of a built-up area" 2 "Unknown" 3 "N/A" ;
VAL_ 2566859548 Seg_Bridge 0 "Not part of a bridge" 1 "Part of a bridge" 2 "Unknown" 3 "N/A" ;
VAL_ 2566859548 Seg_Tunnel 0 "Not part of a tunnel" 1 "Part of a tunnel" 2 "Unknown" 3 "N/A" ;
VAL_ 2566859548 Seg_PathIx 0 "Unknown" 4 "Msg refer to cur.pos. segm" 7 "Reserved" ;
VAL_ 2566859548 Seg_Ofs 8191 "Invalid" ;
VAL_ 2566859548 MsgType_FF2B1C 0 "Reserved" 1 "POSITION" 2 "SEGMENT" 3 "STUB" 4 "PROFILE SHORT" 5 "PROFILE LONG" 6 "META-DATA" 7 "Reserved" ;
VAL_ 2566859804 Stub_NumOfLanesInDrivDir 0 "One-direction road in wrong dir" 1 "1 lane" 2 "2 lanes" 3 "3 lanes" 4 "4 lanes" 5 "5 lanes" 6 "6 or more lanes" 7 "N/A" ;
VAL_ 2566859804 Stub_NumOfLanesInOppDir 0 "One-direction road" 1 "1 lane only" 2 "2 or more lanes" 3 "N/A" ;
VAL_ 2566859804 Stub_RightOfWay 0 "Parent path has right-of-way" 1 "Sub-path has right-of-way" 2 "Unknown" 3 "N/A" ;
VAL_ 2566859804 Stub_LastStubAtOfs 0 "False" 1 "True" ;
VAL_ 2566859804 Stub_TurnAngle 0 "In path direction" 1 "1.417° right from path dir" 2 "2.835° right from path dir" 3 "4.252° right from path dir" 4 "5.669° right from path dir" 5 "7.087° right from path dir" 6 "8.504° right from path dir" 7 "9.921° right from path dir" 8 "11.339° right from path dir" 9 "12.756° right from path dir" 10 "14.173° right from path dir" 11 "15.591° right from path dir" 12 "17.008° right from path dir" 13 "18.425° right from path dir" 14 "19.843° right from path dir" 15 "21.26° right from path dir" 16 "22.677° right from path dir" 17 "24.094° right from path dir" 18 "25.512° right from path dir" 19 "26.929° right from path dir" 20 "28.346° right from path dir" 21 "29.764° right from path dir" 22 "31.181° right from path dir" 23 "32.598° right from path dir" 24 "34.016° right from path dir" 25 "35.433° right from path dir" 26 "36.85° right from path dir" 27 "38.268° right from path dir" 28 "39.685° right from path dir" 29 "41.102° right from path dir" 30 "42.52° right from path dir" 31 "43.937° right from path dir" 32 "45.354° right from path dir" 33 "46.772° right from path dir" 34 "48.189° right from path dir" 35 "49.606° right from path dir" 36 "51.024° right from path dir" 37 "52.441° right from path dir" 38 "53.858° right from path dir" 39 "55.276° right from path dir" 40 "56.693° right from path dir" 41 "58.11° right from path dir" 42 "59.528° right from path dir" 43 "60.945° right from path dir" 44 "62.362° right from path dir" 45 "63.78° right from path dir" 46 "65.197° right from path dir" 47 "66.614° right from path dir" 48 "68.031° right from path dir" 49 "69.449° right from path dir" 50 "70.866° right from path dir" 51 "72.283° right from path dir" 52 "73.701° right from path dir" 53 "75.118° right from path dir" 54 "76.535° right from path dir" 55 "77.953° right from path dir" 56 "79.37° right from path dir" 57 "80.787° right from path dir" 58 "82.205° right from path dir" 59 "83.622° right from path dir" 60 "85.039° right from path dir" 61 "86.457° right from path dir" 62 "87.874° right from path dir" 63 "89.291° right from path dir" 64 "90.709° right from path dir" 65 "92.126° right from path dir" 66 "93.543° right from path dir" 67 "94.961° right from path dir" 68 "96.378° right from path dir" 69 "97.795° right from path dir" 70 "99.213° right from path dir" 71 "100.63° right from path dir" 72 "102.047° right from path dir" 73 "103.465° right from path dir" 74 "104.882° right from path dir" 75 "106.299° right from path dir" 76 "107.717° right from path dir" 77 "109.134° right from path dir" 78 "110.551° right from path dir" 79 "111.969° right from path dir" 80 "113.386° right from path dir" 81 "114.803° right from path dir" 82 "116.22° right from path dir" 83 "117.638° right from path dir" 84 "119.055° right from path dir" 85 "120.472° right from path dir" 86 "121.89° right from path dir" 87 "123.307° right from path dir" 88 "124.724° right from path dir" 89 "126.142° right from path dir" 90 "127.559° right from path dir" 91 "128.976° right from path dir" 92 "130.394° right from path dir" 93 "131.811° right from path dir" 94 "133.228° right from path dir" 95 "134.646° right from path dir" 96 "136.063° right from path dir" 97 "137.48° right from path dir" 98 "138.898° right from path dir" 99 "140.315° right from path dir" 100 "141.732° right from path dir" 101 "143.15° right from path dir" 102 "144.567° right from path dir" 103 "145.984° right from path dir" 104 "147.402° right from path dir" 105 "148.819° right from path dir" 106 "150.236° right from path dir" 107 "151.654° right from path dir" 108 "153.071° right from path dir" 109 "154.488° right from path dir" 110 "155.906° right from path dir" 111 "157.323° right from path dir" 112 "158.74° right from path dir" 113 "160.157° right from path dir" 114 "161.575° right from path dir" 115 "162.992° right from path dir" 116 "164.409° right from path dir" 117 "165.827° right from path dir" 118 "167.244° right from path dir" 119 "168.661° right from path dir" 120 "170.079° right from path dir" 121 "171.496° right from path dir" 122 "172.913° right from path dir" 123 "174.331° right from path dir" 124 "175.748° right from path dir" 125 "177.165° right from path dir" 126 "178.583° right from path dir" 127 "Opposite direction" 128 "178.583° left from path dir" 129 "177.165° left from path dir" 130 "175.748° left from path dir" 131 "174.331° left from path dir" 132 "172.913° left from path dir" 133 "171.496° left from path dir" 134 "170.079° left from path dir" 135 "168.661° left from path dir" 136 "167.244° left from path dir" 137 "165.827° left from path dir" 138 "164.409° left from path dir" 139 "162.992° left from path dir" 140 "161.575° left from path dir" 141 "160.157° left from path dir" 142 "158.74° left from path dir" 143 "157.323° left from path dir" 144 "155.906° left from path dir" 145 "154.488° left from path dir" 146 "153.071° left from path dir" 147 "151.654° left from path dir" 148 "150.236° left from path dir" 149 "148.819° left from path dir" 150 "147.402° left from path dir" 151 "145.984° left from path dir" 152 "144.567° left from path dir" 153 "143.15° left from path dir" 154 "141.732° left from path dir" 155 "140.315° left from path dir" 156 "138.898° left from path dir" 157 "137.48° left from path dir" 158 "136.063° left from path dir" 159 "134.646° left from path dir" 160 "133.228° left from path dir" 161 "131.811° left from path dir" 162 "130.394° left from path dir" 163 "128.976° left from path dir" 164 "127.559° left from path dir" 165 "126.142° left from path dir" 166 "124.724° left from path dir" 167 "123.307° left from path dir" 168 "121.89° left from path dir" 169 "120.472° left from path dir" 170 "119.055° left from path dir" 171 "117.638° left from path dir" 172 "116.22° left from path dir" 173 "114.803° left from path dir" 174 "113.386° left from path dir" 175 "111.969° left from path dir" 176 "110.551° left from path dir" 177 "109.134° left from path dir" 178 "107.717° left from path dir" 179 "106.299° left from path dir" 180 "104.882° left from path dir" 181 "103.465° left from path dir" 182 "102.047° left from path dir" 183 "100.63° left from path dir" 184 "99.213° left from path dir" 185 "97.795° left from path dir" 186 "96.378° left from path dir" 187 "94.961° left from path dir" 188 "93.543° left from path dir" 189 "92.126° left from path dir" 190 "90.709° left from path dir" 191 "89.291° left from path dir" 192 "87.874° left from path dir" 193 "86.457° left from path dir" 194 "85.039° left from path dir" 195 "83.622° left from path dir" 196 "82.205° left from path dir" 197 "80.787° left from path dir" 198 "79.37° left from path dir" 199 "77.953° left from path dir" 200 "76.535° left from path dir" 201 "75.118° left from path dir" 202 "73.701° left from path dir" 203 "72.283° left from path dir" 204 "70.866° left from path dir" 205 "69.449° left from path dir" 206 "68.031° left from path dir" 207 "66.614° left from path dir" 208 "65.197° left from path dir" 209 "63.78° left from path dir" 210 "62.362° left from path dir" 211 "60.945° left from path dir" 212 "59.528° left from path dir" 213 "58.11° left from path dir" 214 "56.693° left from path dir" 215 "55.276° left from path dir" 216 "53.858° left from path dir" 217 "52.441° left from path dir" 218 "51.024° left from path dir" 219 "49.606° left from path dir" 220 "48.189° left from path dir" 221 "46.772° left from path dir" 222 "45.354° left from path dir" 223 "43.937° left from path dir" 224 "42.52° left from path dir" 225 "41.102° left from path dir" 226 "39.685° left from path dir" 227 "38.268° left from path dir" 228 "36.85° left from path dir" 229 "35.433° left from path dir" 230 "34.016° left from path dir" 231 "32.598° left from path dir" 232 "31.181° left from path dir" 233 "29.764° left from path dir" 234 "28.346° left from path dir" 235 "26.929° left from path dir" 236 "25.512° left from path dir" 237 "24.094° left from path dir" 238 "22.677° left from path dir" 239 "21.26° left from path dir" 240 "19.843° left from path dir" 241 "18.425° left from path dir" 242 "17.008° left from path dir" 243 "15.591° left from path dir" 244 "14.173° left from path dir" 245 "12.756° left from path dir" 246 "11.339° left from path dir" 247 "9.921° left from path dir" 248 "8.504° left from path dir" 249 "7.087° left from path dir" 250 "5.669° left from path dir" 251 "4.252° left from path dir" 252 "2.835° left from path dir" 253 "1.417° left from path dir" 254 "Unknown" 255 "N/A" ;
VAL_ 2566859804 Stub_ComplexInters 0 "Not part of complex intersection" 1 "Part of a complex intersection" 2 "Unknown" 3 "N/A" ;
VAL_ 2566859804 Stub_PartOfCalcRoute 0 "Not part from this point on" 1 "Part from this point on" 2 "Unknown" 3 "N/A" ;
VAL_ 2566859804 Stub_FunctRoadClass 0 "Unknown" 1 "Class 1" 2 "Class 2" 3 "Class 3" 4 "Class 4" 5 "Class 5" 6 "Class 6" 7 "N/A" ;
VAL_ 2566859804 Stub_RelProb 0 "Turn is not allowed" 31 "Unknown or N/A" ;
VAL_ 2566859804 Stub_Update 0 "False" 1 "True" ;
VAL_ 2566859804 Stub_Retr 0 "False" 1 "True" ;
VAL_ 2566859804 Stub_SubPathIx 0 "Unknown" 7 "Reserved" ;
VAL_ 2566859804 Stub_PathIx 0 "Unknown" 5 "Not further appended" 6 "HEADING CHANGE" 7 "Reserved" ;
VAL_ 2566859804 Stub_Ofs 8191 "Invalid" ;
VAL_ 2566859804 MsgType_FF2C1C 0 "Reserved" 1 "POSITION" 2 "SEGMENT" 3 "STUB" 4 "PROFILE SHORT" 5 "PROFILE LONG" 6 "META-DATA" 7 "Reserved" ;
VAL_ 2566860060 ProfShort_Val0 1023 "Unknown or N/A" ;
VAL_ 2566860060 ProfShort_Dist1 1023 "Invalid" ;
VAL_ 2566860060 ProfShort_Accur 0 "Highest" 2 "Lowest" 3 "Unknown" ;
VAL_ 2566860060 ProfShort_Update 0 "False" 1 "True" ;
VAL_ 2566860060 ProfShort_Retr 0 "False" 1 "True" ;
VAL_ 2566860060 ProfShort_CtrlPnt 0 "False" 1 "True" ;
VAL_ 2566860060 ProfShort_ProfType 0 "N/A" 1 "Curvature, Linear interp." 2 "Route Number Types, Step interp" 3 "Slope, Step interp" 4 "Slope, Linear interp" 5 "Road accessibility, Step interp" 6 "Road condition, Step interp" 7 "Var Speed Sign Pos." 8 "Heading Change" 9 "Res. for std types" 10 "Res. for std types" 11 "Res. for std types" 12 "Res. for std types" 13 "Res. for std types" 14 "Res. for std types" 15 "Res. for std types" 16 "Res. for system specific types" 17 "Res. for system specific types" 18 "Res. for system specific types" 19 "Res. for system specific types" 20 "Res. for system specific types" 21 "Res. for system specific types" 22 "Res. for system specific types" 23 "Res. for system specific types" 24 "Res. for system specific types" 25 "Res. for system specific types" 26 "Res. for system specific types" 27 "Res. for system specific types" 28 "Res. for system specific types" 29 "Res. for system specific types" 30 "Res. for system specific types" 31 "Res. for system specific types" ;
VAL_ 2566860060 ProfShort_PathIx 0 "Unknown" 7 "Reserved" ;
VAL_ 2566860060 ProfShort_Ofs 8191 "Invalid" ;
VAL_ 2566860060 MsgType_FF2D1C 0 "Reserved" 1 "POSITION" 2 "SEGMENT" 3 "STUB" 4 "PROFILE SHORT" 5 "PROFILE LONG" 6 "META-DATA" 7 "Reserved" ;
VAL_ 2566860316 ProfLong_Val31_RsvdForSysSpecTyp -1 "Unknown or N/A" ;
VAL_ 2566860316 ProfLong_Val30_RsvdForSysSpecTyp -1 "Unknown or N/A" ;
VAL_ 2566860316 ProfLong_Val29_RsvdForSysSpecTyp -1 "Unknown or N/A" ;
VAL_ 2566860316 ProfLong_Val28_RsvdForSysSpecTyp -1 "Unknown or N/A" ;
VAL_ 2566860316 ProfLong_Val27_RsvdForSysSpecTyp -1 "Unknown or N/A" ;
VAL_ 2566860316 ProfLong_Val26_RsvdForSysSpecTyp -1 "Unknown or N/A" ;
VAL_ 2566860316 ProfLong_Val25_RsvdForSysSpecTyp -1 "Unknown or N/A" ;
VAL_ 2566860316 ProfLong_Val24_RsvdForSysSpecTyp -1 "Unknown or N/A" ;
VAL_ 2566860316 ProfLong_Val23_RsvdForSysSpecTyp -1 "Unknown or N/A" ;
VAL_ 2566860316 ProfLong_Val22_RsvdForSysSpecTyp -1 "Unknown or N/A" ;
VAL_ 2566860316 ProfLong_Val21_RsvdForSysSpecTyp -1 "Unknown or N/A" ;
VAL_ 2566860316 ProfLong_Val20_RsvdForSysSpecTyp -1 "Unknown or N/A" ;
VAL_ 2566860316 ProfLong_Val19_RsvdForSysSpecTyp -1 "Unknown or N/A" ;
VAL_ 2566860316 ProfLong_Val18_RsvdForSysSpecTyp -1 "Unknown or N/A" ;
VAL_ 2566860316 ProfLong_Val17_RsvdForSysSpecTyp -1 "Unknown or N/A" ;
VAL_ 2566860316 ProfLong_Val16_RsvdForSysSpecTyp -1 "Unknown or N/A" ;
VAL_ 2566860316 ProfLong_Val15_RsvdForStdTypes -1 "Unknown or N/A" ;
VAL_ 2566860316 ProfLong_Val14_RsvdForStdTypes -1 "Unknown or N/A" ;
VAL_ 2566860316 ProfLong_Val13_RsvdForStdTypes -1 "Unknown or N/A" ;
VAL_ 2566860316 ProfLong_Val12_RsvdForStdTypes -1 "Unknown or N/A" ;
VAL_ 2566860316 ProfLong_Val11_RsvdForStdTypes -1 "Unknown or N/A" ;
VAL_ 2566860316 ProfLong_Val10_RsvdForStdTypes -1 "Unknown or N/A" ;
VAL_ 2566860316 ProfLong_Val9_RsvdForStdTypes -1 "Unknown or N/A" ;
VAL_ 2566860316 ProfLong_Val8_RsvdForStdTypes -1 "Unknown or N/A" ;
VAL_ 2566860316 ProfLong_Val7_RsvdForStdTypes -1 "Unknown or N/A" ;
VAL_ 2566860316 ProfLong_Val6_RsvdForStdTypes -1 "Unknown or N/A" ;
VAL_ 2566860316 ProfLong_Val5_RsvdForStdTypes -1 "Unknown or N/A" ;
VAL_ 2566860316 ProfLong_Val4_RsvdForStdTypes -1 "Unknown or N/A" ;
VAL_ 2566860316 ProfLong_Val3_RsvdForStdTypes -1 "Unknown or N/A" ;
VAL_ 2566860316 ProfLong_Val2_Lat -1 "Unknown or N/A" ;
VAL_ 2566860316 ProfLong_Val1_Long -1 "Unknown or N/A" ;
VAL_ 2566860316 ProfLong_Update 0 "False" 1 "True" ;
VAL_ 2566860316 ProfLong_Retr 0 "False" 1 "True" ;
VAL_ 2566860316 ProfLong_CtrlPnt 0 "False" 1 "True" ;
VAL_ 2566860316 ProfLong_ProfType 0 "N/A" 1 "Longitude, Linear interp." 2 "Latitude, Linear interp." 3 "Res. for std types" 4 "Res. for std types" 5 "Res. for std types" 6 "Res. for std types" 7 "Res. for std types" 8 "Res. for std types" 9 "Res. for std types" 10 "Res. for std types" 11 "Res. for std types" 12 "Res. for std types" 13 "Res. for std types" 14 "Res. for std types" 15 "Res. for std types" 16 "Res. for system specific types" 17 "Traffic Low Data" 18 "Res. for system specific types" 19 "Res. for system specific types" 20 "Res. for system specific types" 21 "Res. for system specific types" 22 "Res. for system specific types" 23 "Res. for system specific types" 24 "Res. for system specific types" 25 "Res. for system specific types" 26 "Res. for system specific types" 27 "Res. for system specific types" 28 "Res. for system specific types" 29 "Res. for system specific types" 30 "Res. for system specific types" 31 "Res. for system specific types" ;
VAL_ 2566860316 ProfLong_PathIx 0 "Unknown" 7 "Reserved" ;
VAL_ 2566860316 ProfLong_Ofs 8191 "Invalid" ;
VAL_ 2566860316 MsgType_FF2E1C 0 "Reserved" 1 "POSITION" 2 "SEGMENT" 3 "STUB" 4 "PROFILE SHORT" 5 "PROFILE LONG" 6 "META-DATA" 7 "Reserved" ;
VAL_ 2566860572 Meta_SpeedUnits 0 "km/h" 1 "mph" ;
VAL_ 2566860572 Meta_MapVerYr 63 "N/A" ;
VAL_ 2566860572 Meta_RegionCode 0 "Unknown" 32767 "N/A" ;
VAL_ 2566860572 Meta_DrivSide 0 "Left." 1 "Right" ;
VAL_ 2566860572 Meta_HwVer 0 "Unknown" ;
VAL_ 2566860572 Meta_CntryCode 0 "Unknown" ;
VAL_ 2566860572 Meta_MapProvider 0 "Unknown" 1 "NAVTEQ" 2 "TeleAtlas" 3 "Zenrin" 4 "Reserved" 5 "Reserved" 6 "Reserved" 7 "N/A." ;
VAL_ 2566860572 MsgType_FF2F1C 0 "Reserved" 1 "POSITION" 2 "SEGMENT" 3 "STUB" 4 "PROFILE SHORT" 5 "PROFILE LONG" 6 "META-DATA" 7 "Reserved" ;
VAL_ 2565804065 HandLevPos 0 "Pos. 0, 1" 3 "Pos. 2" 7 "Pos. 3" 15 "Pos. 4" 31 "Pos. 5" 63 "Pos. 6" ;
VAL_ 2565804065 DisRetFtReq 0 "Off" 1 "On" ;
VAL_ 2566850593 CrkInh 0 "EngStartNotInhibByBC" 1 "EngStartInhibByBC" 2 "Error" 3 "Not Available" ;
VAL_ 2566850593 EngStartClear 0 "EngStartNotGranted" 1 "EngStartGranted" 2 "Error" 3 "Not Available" ;
VAL_ 2566850593 EngStopClear 0 "EngStopNotGranted" 1 "EngStopGranted" 2 "Error" 3 "Not Available" ;
VAL_ 2566722906 BatChg1PwrLineSts 0 "Disconnected from charger" 1 "Connected to the charger" 2 "Error" 3 "Not Available" ;
VAL_ 2566722906 BatChg1Sts 0 "Idling_DisconnFromCharger" 1 "Charging the battery" 2 "StandBy or maintainCharge" 13 "Battery failure" 14 "Charger failure" 15 "Not Available." ;
VAL_ 2566906099 Bms0IPwrDistributed 0 "Not Distributed or In Progress" 1 "Distributed" ;
VAL_ 2566906099 Bms0IChgCompl 0 "Not Completed" 1 "Completed" ;
VAL_ 2566906099 Bms0IOpSts 0 "Normal" 1 "Low downgraded" 2 "Failure" 3 "Invalid" ;
VAL_ 2566906099 Bms0IActSts 0 "OFF" 1 "Park" 2 "Operational" 3 "Charge" 7 "Invalid" ;
VAL_ 2566906099 Bms0IEqualizationSts 0 "No Balancing" 1 "Balancing Active" ;
VAL_ 2566906355 Bms0IPwrDistributed_FFE1F3 0 "Not Distributed or In Progress" 1 "Distributed" ;
VAL_ 2566906355 Bms0IChgCompl_FFE1F3 0 "Not Completed" 1 "Completed" ;
VAL_ 2566906355 Bms0IOpSts_FFE1F3 0 "Normal" 1 "Low downgraded" 2 "Failure" 3 "Invalid" ;
VAL_ 2566906355 Bms0IActSts_FFE1F3 0 "OFF" 1 "Park" 2 "Operational" 3 "Charge" 7 "Invalid" ;
VAL_ 2566906355 Bms0IEqualizationSts_FFE1F3 0 "No Balancing" 1 "Balancing Active" ;
VAL_ 2566906611 Bms0IPwrDistributed_FFE2F3 0 "Not Distributed or In Progress" 1 "Distributed" ;
VAL_ 2566906611 Bms0IChgCompl_FFE2F3 0 "Not Completed" 1 "Completed" ;
VAL_ 2566906611 Bms0IOpSts_FFE2F3 0 "Normal" 1 "Low downgraded" 2 "Failure" 3 "Invalid" ;
VAL_ 2566906611 Bms0IActSts_FFE2F3 0 "OFF" 1 "Park" 2 "Operational" 3 "Charge" 7 "Invalid" ;
VAL_ 2566906611 Bms0IEqualizationSts_FFE2F3 0 "No Balancing" 1 "Balancing Active" ;
VAL_ 2566906867 Bms0IPwrDistributed_FFE3F3 0 "Not Distributed or In Progress" 1 "Distributed" ;
VAL_ 2566906867 Bms0IChgCompl_FFE3F3 0 "Not Completed" 1 "Completed" ;
VAL_ 2566906867 Bms0IOpSts_FFE3F3 0 "Normal" 1 "Low downgraded" 2 "Failure" 3 "Invalid" ;
VAL_ 2566906867 Bms0IActSts_FFE3F3 0 "OFF" 1 "Park" 2 "Operational" 3 "Charge" 7 "Invalid" ;
VAL_ 2566906867 Bms0IEqualizationSts_FFE3F3 0 "No Balancing" 1 "Balancing Active" ;
VAL_ 2566907123 Bms0IPwrDistributed_FFE4F3 0 "Not Distributed or In Progress" 1 "Distributed" ;
VAL_ 2566907123 Bms0IChgCompl_FFE4F3 0 "Not Completed" 1 "Completed" ;
VAL_ 2566907123 Bms0IOpSts_FFE4F3 0 "Normal" 1 "Low downgraded" 2 "Failure" 3 "Invalid" ;
VAL_ 2566907123 Bms0IActSts_FFE4F3 0 "OFF" 1 "Park" 2 "Operational" 3 "Charge" 7 "Invalid" ;
VAL_ 2566907123 Bms0IEqualizationSts_FFE4F3 0 "No Balancing" 1 "Balancing Active" ;
VAL_ 2566907379 Bms0IPwrDistributed_FFE5F3 0 "Not Distributed or In Progress" 1 "Distributed" ;
VAL_ 2566907379 Bms0IChgCompl_FFE5F3 0 "Not Completed" 1 "Completed" ;
VAL_ 2566907379 Bms0IOpSts_FFE5F3 0 "Normal" 1 "Low downgraded" 2 "Failure" 3 "Invalid" ;
VAL_ 2566907379 Bms0IActSts_FFE5F3 0 "OFF" 1 "Park" 2 "Operational" 3 "Charge" 7 "Invalid" ;
VAL_ 2566907379 Bms0IEqualizationSts_FFE5F3 0 "No Balancing" 1 "Balancing Active" ;
VAL_ 2566907635 Bms0IPwrDistributed_FFE6F3 0 "Not Distributed or In Progress" 1 "Distributed" ;
VAL_ 2566907635 Bms0IChgCompl_FFE6F3 0 "Not Completed" 1 "Completed" ;
VAL_ 2566907635 Bms0IOpSts_FFE6F3 0 "Normal" 1 "Low downgraded" 2 "Failure" 3 "Invalid" ;
VAL_ 2566907635 Bms0IActSts_FFE6F3 0 "OFF" 1 "Park" 2 "Operational" 3 "Charge" 7 "Invalid" ;
VAL_ 2566907635 Bms0IEqualizationSts_FFE6F3 0 "No Balancing" 1 "Balancing Active" ;
VAL_ 2566907891 Bms0IPwrDistributed_FFE7F3 0 "Not Distributed or In Progress" 1 "Distributed" ;
VAL_ 2566907891 Bms0IChgCompl_FFE7F3 0 "Not Completed" 1 "Completed" ;
VAL_ 2566907891 Bms0IOpSts_FFE7F3 0 "Normal" 1 "Low downgraded" 2 "Failure" 3 "Invalid" ;
VAL_ 2566907891 Bms0IActSts_FFE7F3 0 "OFF" 1 "Park" 2 "Operational" 3 "Charge" 7 "Invalid" ;
VAL_ 2566907891 Bms0IEqualizationSts_FFE7F3 0 "No Balancing" 1 "Balancing Active" ;
VAL_ 2566908147 Bms0IPwrDistributed_FFE8F3 0 "Not Distributed or In Progress" 1 "Distributed" ;
VAL_ 2566908147 Bms0IChgCompl_FFE8F3 0 "Not Completed" 1 "Completed" ;
VAL_ 2566908147 Bms0IOpSts_FFE8F3 0 "Normal" 1 "Low downgraded" 2 "Failure" 3 "Invalid" ;
VAL_ 2566908147 Bms0IActSts_FFE8F3 0 "OFF" 1 "Park" 2 "Operational" 3 "Charge" 7 "Invalid" ;
VAL_ 2566908147 Bms0IEqualizationSts_FFE8F3 0 "No Balancing" 1 "Balancing Active" ;
VAL_ 2566908403 Bms0IPwrDistributed_FFE9F3 0 "Not Distributed or In Progress" 1 "Distributed" ;
VAL_ 2566908403 Bms0IChgCompl_FFE9F3 0 "Not Completed" 1 "Completed" ;
VAL_ 2566908403 Bms0IOpSts_FFE9F3 0 "Normal" 1 "Low downgraded" 2 "Failure" 3 "Invalid" ;
VAL_ 2566908403 Bms0IActSts_FFE9F3 0 "OFF" 1 "Park" 2 "Operational" 3 "Charge" 7 "Invalid" ;
VAL_ 2566908403 Bms0IEqualizationSts_FFE9F3 0 "No Balancing" 1 "Balancing Active" ;
VAL_ 2566908659 Bms0IPwrDistributed_FFEAF3 0 "Not Distributed or In Progress" 1 "Distributed" ;
VAL_ 2566908659 Bms0IChgCompl_FFEAF3 0 "Not Completed" 1 "Completed" ;
VAL_ 2566908659 Bms0IOpSts_FFEAF3 0 "Normal" 1 "Low downgraded" 2 "Failure" 3 "Invalid" ;
VAL_ 2566908659 Bms0IActSts_FFEAF3 0 "OFF" 1 "Park" 2 "Operational" 3 "Charge" 7 "Invalid" ;
VAL_ 2566908659 Bms0IEqualizationSts_FFEAF3 0 "No Balancing" 1 "Balancing Active" ;
